VERSION ""

NS_ :

BS_:

BU_:

BO_ 2566697726 SPOC1: 64 Vector__XXX
 SG_ SwitchedOutput10Current : 144|16@1+ (0.005,0) [0|321.275] "A" Vector__XXX
 SG_ SwitchedOutput11Current : 160|16@1+ (0.005,0) [0|321.275] "A" Vector__XXX
 SG_ SwitchedOutput12Current : 176|16@1+ (0.005,0) [0|321.275] "A" Vector__XXX
 SG_ SwitchedOutput13Current : 192|16@1+ (0.005,0) [0|321.275] "A" Vector__XXX
 SG_ SwitchedOutput14Current : 208|16@1+ (0.005,0) [0|321.275] "A" Vector__XXX
 SG_ SwitchedOutput15Current : 224|16@1+ (0.005,0) [0|321.275] "A" Vector__XXX
 SG_ SwitchedOutput16Current : 240|16@1+ (0.005,0) [0|321.275] "A" Vector__XXX
 SG_ SwitchedOutput17Current : 256|16@1+ (0.005,0) [0|321.275] "A" Vector__XXX
 SG_ SwitchedOutput18Current : 272|16@1+ (0.005,0) [0|321.275] "A" Vector__XXX
 SG_ SwitchedOutput19Current : 288|16@1+ (0.005,0) [0|321.275] "A" Vector__XXX
 SG_ SwitchedOutput1Current : 0|16@1+ (0.005,0) [0|321.275] "A" Vector__XXX
 SG_ SwitchedOutput20Current : 304|16@1+ (0.005,0) [0|321.275] "A" Vector__XXX
 SG_ SwitchedOutput21Current : 320|16@1+ (0.005,0) [0|321.275] "A" Vector__XXX
 SG_ SwitchedOutput22Current : 336|16@1+ (0.005,0) [0|321.275] "A" Vector__XXX
 SG_ SwitchedOutput23Current : 352|16@1+ (0.005,0) [0|321.275] "A" Vector__XXX
 SG_ SwitchedOutput24Current : 368|16@1+ (0.005,0) [0|321.275] "A" Vector__XXX
 SG_ SwitchedOutput25Current : 384|16@1+ (0.005,0) [0|321.275] "A" Vector__XXX
 SG_ SwitchedOutput26Current : 400|16@1+ (0.005,0) [0|321.275] "A" Vector__XXX
 SG_ SwitchedOutput27Current : 416|16@1+ (0.005,0) [0|321.275] "A" Vector__XXX
 SG_ SwitchedOutput28Current : 432|16@1+ (0.005,0) [0|321.275] "A" Vector__XXX
 SG_ SwitchedOutput29Current : 448|16@1+ (0.005,0) [0|321.275] "A" Vector__XXX
 SG_ SwitchedOutput2Current : 16|16@1+ (0.005,0) [0|321.275] "A" Vector__XXX
 SG_ SwitchedOutput30Current : 464|16@1+ (0.005,0) [0|321.275] "A" Vector__XXX
 SG_ SwitchedOutput31Current : 480|16@1+ (0.005,0) [0|321.275] "A" Vector__XXX
 SG_ SwitchedOutput32Current : 496|16@1+ (0.005,0) [0|321.275] "A" Vector__XXX
 SG_ SwitchedOutput3Current : 32|16@1+ (0.005,0) [0|321.275] "A" Vector__XXX
 SG_ SwitchedOutput4Current : 48|16@1+ (0.005,0) [0|321.275] "A" Vector__XXX
 SG_ SwitchedOutput5Current : 64|16@1+ (0.005,0) [0|321.275] "A" Vector__XXX
 SG_ SwitchedOutput6Current : 80|16@1+ (0.005,0) [0|321.275] "A" Vector__XXX
 SG_ SwitchedOutput7Current : 96|16@1+ (0.005,0) [0|321.275] "A" Vector__XXX
 SG_ SwitchedOutput8Current : 112|16@1+ (0.005,0) [0|321.275] "A" Vector__XXX
 SG_ SwitchedOutput9Current : 128|16@1+ (0.005,0) [0|321.275] "A" Vector__XXX

BO_ 2566697982 FPOC: 64 Vector__XXX
 SG_ FusedOutput10Current : 144|16@1+ (0.005,0) [0|321.275] "A" Vector__XXX
 SG_ FusedOutput11Current : 160|16@1+ (0.005,0) [0|321.275] "A" Vector__XXX
 SG_ FusedOutput12Current : 176|16@1+ (0.005,0) [0|321.275] "A" Vector__XXX
 SG_ FusedOutput13Current : 192|16@1+ (0.005,0) [0|321.275] "A" Vector__XXX
 SG_ FusedOutput14Current : 208|16@1+ (0.005,0) [0|321.275] "A" Vector__XXX
 SG_ FusedOutput15Current : 224|16@1+ (0.005,0) [0|321.275] "A" Vector__XXX
 SG_ FusedOutput16Current : 240|16@1+ (0.005,0) [0|321.275] "A" Vector__XXX
 SG_ FusedOutput17Current : 256|16@1+ (0.005,0) [0|321.275] "A" Vector__XXX
 SG_ FusedOutput18Current : 272|16@1+ (0.005,0) [0|321.275] "A" Vector__XXX
 SG_ FusedOutput19Current : 288|16@1+ (0.005,0) [0|321.275] "A" Vector__XXX
 SG_ FusedOutput1Current : 0|16@1+ (0.005,0) [0|321.275] "A" Vector__XXX
 SG_ FusedOutput20Current : 304|16@1+ (0.005,0) [0|321.275] "A" Vector__XXX
 SG_ FusedOutput21Current : 320|16@1+ (0.005,0) [0|321.275] "A" Vector__XXX
 SG_ FusedOutput22Current : 336|16@1+ (0.005,0) [0|321.275] "A" Vector__XXX
 SG_ FusedOutput23Current : 352|16@1+ (0.005,0) [0|321.275] "A" Vector__XXX
 SG_ FusedOutput24Current : 368|16@1+ (0.005,0) [0|321.275] "A" Vector__XXX
 SG_ FusedOutput25Current : 384|16@1+ (0.005,0) [0|321.275] "A" Vector__XXX
 SG_ FusedOutput26Current : 400|16@1+ (0.005,0) [0|321.275] "A" Vector__XXX
 SG_ FusedOutput27Current : 416|16@1+ (0.005,0) [0|321.275] "A" Vector__XXX
 SG_ FusedOutput28Current : 432|16@1+ (0.005,0) [0|321.275] "A" Vector__XXX
 SG_ FusedOutput29Current : 448|16@1+ (0.005,0) [0|321.275] "A" Vector__XXX
 SG_ FusedOutput2Current : 16|16@1+ (0.005,0) [0|321.275] "A" Vector__XXX
 SG_ FusedOutput30Current : 464|16@1+ (0.005,0) [0|321.275] "A" Vector__XXX
 SG_ FusedOutput31Current : 480|16@1+ (0.005,0) [0|321.275] "A" Vector__XXX
 SG_ FusedOutput32Current : 496|16@1+ (0.005,0) [0|321.275] "A" Vector__XXX
 SG_ FusedOutput3Current : 32|16@1+ (0.005,0) [0|321.275] "A" Vector__XXX
 SG_ FusedOutput4Current : 48|16@1+ (0.005,0) [0|321.275] "A" Vector__XXX
 SG_ FusedOutput5Current : 64|16@1+ (0.005,0) [0|321.275] "A" Vector__XXX
 SG_ FusedOutput6Current : 80|16@1+ (0.005,0) [0|321.275] "A" Vector__XXX
 SG_ FusedOutput7Current : 96|16@1+ (0.005,0) [0|321.275] "A" Vector__XXX
 SG_ FusedOutput8Current : 112|16@1+ (0.005,0) [0|321.275] "A" Vector__XXX
 SG_ FusedOutput9Current : 128|16@1+ (0.005,0) [0|321.275] "A" Vector__XXX

BO_ 2566698238 SPOS: 8 Vector__XXX
 SG_ SwitchedOutput1 : 6|2@1+ (1,0) [0|3] "" Vector__XXX
 SG_ SwitchedOutput10 : 20|2@1+ (1,0) [0|3] "" Vector__XXX
 SG_ SwitchedOutput11 : 18|2@1+ (1,0) [0|3] "" Vector__XXX
 SG_ SwitchedOutput12 : 16|2@1+ (1,0) [0|3] "" Vector__XXX
 SG_ SwitchedOutput13 : 30|2@1+ (1,0) [0|3] "" Vector__XXX
 SG_ SwitchedOutput14 : 28|2@1+ (1,0) [0|3] "" Vector__XXX
 SG_ SwitchedOutput15 : 26|2@1+ (1,0) [0|3] "" Vector__XXX
 SG_ SwitchedOutput16 : 24|2@1+ (1,0) [0|3] "" Vector__XXX
 SG_ SwitchedOutput17 : 38|2@1+ (1,0) [0|3] "" Vector__XXX
 SG_ SwitchedOutput18 : 36|2@1+ (1,0) [0|3] "" Vector__XXX
 SG_ SwitchedOutput19 : 34|2@1+ (1,0) [0|3] "" Vector__XXX
 SG_ SwitchedOutput2 : 4|2@1+ (1,0) [0|3] "" Vector__XXX
 SG_ SwitchedOutput20 : 32|2@1+ (1,0) [0|3] "" Vector__XXX
 SG_ SwitchedOutput21 : 46|2@1+ (1,0) [0|3] "" Vector__XXX
 SG_ SwitchedOutput22 : 44|2@1+ (1,0) [0|3] "" Vector__XXX
 SG_ SwitchedOutput23 : 42|2@1+ (1,0) [0|3] "" Vector__XXX
 SG_ SwitchedOutput24 : 40|2@1+ (1,0) [0|3] "" Vector__XXX
 SG_ SwitchedOutput25 : 54|2@1+ (1,0) [0|3] "" Vector__XXX
 SG_ SwitchedOutput26 : 52|2@1+ (1,0) [0|3] "" Vector__XXX
 SG_ SwitchedOutput27 : 50|2@1+ (1,0) [0|3] "" Vector__XXX
 SG_ SwitchedOutput28 : 48|2@1+ (1,0) [0|3] "" Vector__XXX
 SG_ SwitchedOutput29 : 62|2@1+ (1,0) [0|3] "" Vector__XXX
 SG_ SwitchedOutput3 : 2|2@1+ (1,0) [0|3] "" Vector__XXX
 SG_ SwitchedOutput30 : 60|2@1+ (1,0) [0|3] "" Vector__XXX
 SG_ SwitchedOutput31 : 58|2@1+ (1,0) [0|3] "" Vector__XXX
 SG_ SwitchedOutput32 : 56|2@1+ (1,0) [0|3] "" Vector__XXX
 SG_ SwitchedOutput4 : 0|2@1+ (1,0) [0|3] "" Vector__XXX
 SG_ SwitchedOutput5 : 14|2@1+ (1,0) [0|3] "" Vector__XXX
 SG_ SwitchedOutput6 : 12|2@1+ (1,0) [0|3] "" Vector__XXX
 SG_ SwitchedOutput7 : 10|2@1+ (1,0) [0|3] "" Vector__XXX
 SG_ SwitchedOutput8 : 8|2@1+ (1,0) [0|3] "" Vector__XXX
 SG_ SwitchedOutput9 : 22|2@1+ (1,0) [0|3] "" Vector__XXX

BO_ 2566698494 FPOS: 8 Vector__XXX
 SG_ FusedOutput1 : 6|2@1+ (1,0) [0|3] "" Vector__XXX
 SG_ FusedOutput10 : 20|2@1+ (1,0) [0|3] "" Vector__XXX
 SG_ FusedOutput11 : 18|2@1+ (1,0) [0|3] "" Vector__XXX
 SG_ FusedOutput12 : 16|2@1+ (1,0) [0|3] "" Vector__XXX
 SG_ FusedOutput13 : 30|2@1+ (1,0) [0|3] "" Vector__XXX
 SG_ FusedOutput14 : 28|2@1+ (1,0) [0|3] "" Vector__XXX
 SG_ FusedOutput15 : 26|2@1+ (1,0) [0|3] "" Vector__XXX
 SG_ FusedOutput16 : 24|2@1+ (1,0) [0|3] "" Vector__XXX
 SG_ FusedOutput17 : 38|2@1+ (1,0) [0|3] "" Vector__XXX
 SG_ FusedOutput18 : 36|2@1+ (1,0) [0|3] "" Vector__XXX
 SG_ FusedOutput19 : 34|2@1+ (1,0) [0|3] "" Vector__XXX
 SG_ FusedOutput2 : 4|2@1+ (1,0) [0|3] "" Vector__XXX
 SG_ FusedOutput20 : 32|2@1+ (1,0) [0|3] "" Vector__XXX
 SG_ FusedOutput21 : 46|2@1+ (1,0) [0|3] "" Vector__XXX
 SG_ FusedOutput22 : 44|2@1+ (1,0) [0|3] "" Vector__XXX
 SG_ FusedOutput23 : 42|2@1+ (1,0) [0|3] "" Vector__XXX
 SG_ FusedOutput24 : 40|2@1+ (1,0) [0|3] "" Vector__XXX
 SG_ FusedOutput25 : 54|2@1+ (1,0) [0|3] "" Vector__XXX
 SG_ FusedOutput26 : 52|2@1+ (1,0) [0|3] "" Vector__XXX
 SG_ FusedOutput27 : 50|2@1+ (1,0) [0|3] "" Vector__XXX
 SG_ FusedOutput28 : 48|2@1+ (1,0) [0|3] "" Vector__XXX
 SG_ FusedOutput29 : 62|2@1+ (1,0) [0|3] "" Vector__XXX
 SG_ FusedOutput3 : 2|2@1+ (1,0) [0|3] "" Vector__XXX
 SG_ FusedOutput30 : 60|2@1+ (1,0) [0|3] "" Vector__XXX
 SG_ FusedOutput31 : 58|2@1+ (1,0) [0|3] "" Vector__XXX
 SG_ FusedOutput32 : 56|2@1+ (1,0) [0|3] "" Vector__XXX
 SG_ FusedOutput4 : 0|2@1+ (1,0) [0|3] "" Vector__XXX
 SG_ FusedOutput5 : 14|2@1+ (1,0) [0|3] "" Vector__XXX
 SG_ FusedOutput6 : 12|2@1+ (1,0) [0|3] "" Vector__XXX
 SG_ FusedOutput7 : 10|2@1+ (1,0) [0|3] "" Vector__XXX
 SG_ FusedOutput8 : 8|2@1+ (1,0) [0|3] "" Vector__XXX
 SG_ FusedOutput9 : 22|2@1+ (1,0) [0|3] "" Vector__XXX

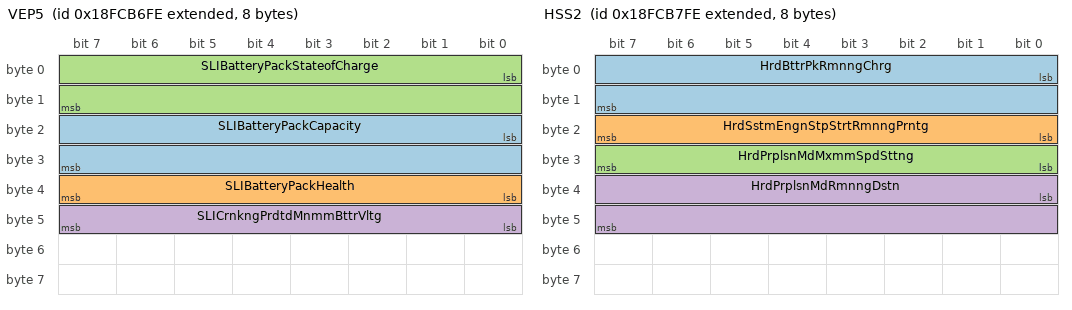
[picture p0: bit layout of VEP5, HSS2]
BO_ 2566698750 VEP5: 8 Vector__XXX
 SG_ SLIBatteryPackCapacity : 16|16@1+ (1,0) [0|64255] "Ah" Vector__XXX
 SG_ SLIBatteryPackHealth : 32|8@1+ (0.5,0) [0|125] "%" Vector__XXX
 SG_ SLIBatteryPackStateofCharge : 0|16@1+ (0.0025,0) [0|160.6375] "%" Vector__XXX
 SG_ SLICrnkngPrdtdMnmmBttrVltg : 40|8@1+ (0.2,0) [0|50] "V" Vector__XXX

BO_ 2566699006 HSS2: 8 Vector__XXX
 SG_ HrdBttrPkRmnngChrg : 0|16@1+ (0.0025,0) [0|160.6375] "%" Vector__XXX
 SG_ HrdSstmEngnStpStrtRmnngPrntg : 16|8@1+ (0.4,0) [0|100] "%" Vector__XXX
 SG_ HrdPrplsnMdMxmmSpdSttng : 24|8@1+ (1,0) [0|250] "km/h" Vector__XXX
 SG_ HrdPrplsnMdRmnngDstn : 32|16@1+ (0.03125,0) [0|2007.96875] "km" Vector__XXX

BO_ 2566699262 AT2S2: 8 Vector__XXX
 SG_ Atttt2DsPttFtTtNxtAtvRt : 0|32@1+ (1,0) [0|4211081215] "s" Vector__XXX
 SG_ Atttt2SCRSstTSLstSstCEvt : 32|32@1+ (1,0) [0|4211081215] "s" Vector__XXX

BO_ 2566699518 AT1S2: 8 Vector__XXX
 SG_ Atttt1DsPttFtTtNxtAtvRt : 0|32@1+ (1,0) [0|4211081215] "s" Vector__XXX
 SG_ Atttt1SCRSstTSLstSstCEvt : 32|32@1+ (1,0) [0|4211081215] "s" Vector__XXX

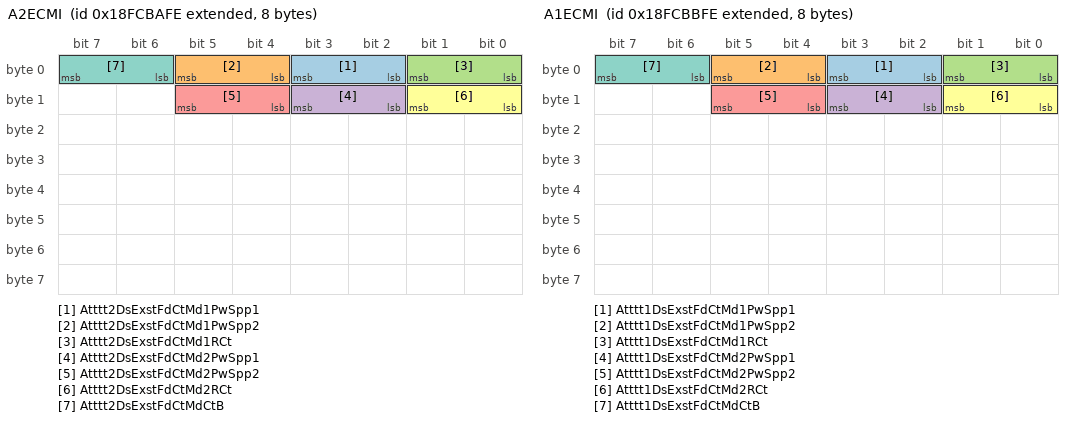
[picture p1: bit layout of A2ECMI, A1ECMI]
BO_ 2566699774 A2ECMI: 8 Vector__XXX
 SG_ Atttt2DsExstFdCtMd1PwSpp1 : 2|2@1+ (1,0) [0|3] "" Vector__XXX
 SG_ Atttt2DsExstFdCtMd1PwSpp2 : 4|2@1+ (1,0) [0|3] "" Vector__XXX
 SG_ Atttt2DsExstFdCtMd1RCt : 0|2@1+ (1,0) [0|3] "" Vector__XXX
 SG_ Atttt2DsExstFdCtMd2PwSpp1 : 10|2@1+ (1,0) [0|3] "" Vector__XXX
 SG_ Atttt2DsExstFdCtMd2PwSpp2 : 12|2@1+ (1,0) [0|3] "" Vector__XXX
 SG_ Atttt2DsExstFdCtMd2RCt : 8|2@1+ (1,0) [0|3] "" Vector__XXX
 SG_ Atttt2DsExstFdCtMdCtB : 6|2@1+ (1,0) [0|3] "" Vector__XXX

BO_ 2566700030 A1ECMI: 8 Vector__XXX
 SG_ Atttt1DsExstFdCtMd1PwSpp1 : 2|2@1+ (1,0) [0|3] "" Vector__XXX
 SG_ Atttt1DsExstFdCtMd1PwSpp2 : 4|2@1+ (1,0) [0|3] "" Vector__XXX
 SG_ Atttt1DsExstFdCtMd1RCt : 0|2@1+ (1,0) [0|3] "" Vector__XXX
 SG_ Atttt1DsExstFdCtMd2PwSpp1 : 10|2@1+ (1,0) [0|3] "" Vector__XXX
 SG_ Atttt1DsExstFdCtMd2PwSpp2 : 12|2@1+ (1,0) [0|3] "" Vector__XXX
 SG_ Atttt1DsExstFdCtMd2RCt : 8|2@1+ (1,0) [0|3] "" Vector__XXX
 SG_ Atttt1DsExstFdCtMdCtB : 6|2@1+ (1,0) [0|3] "" Vector__XXX

BO_ 2566700286 A2SCRSI2: 8 Vector__XXX
 SG_ Aftrtrtmnt2TtlDslExhstFldUsd : 0|32@1+ (0.5,0) [0|2105540607.5] "l" Vector__XXX

BO_ 2566700542 A1SCRSI2: 8 Vector__XXX
 SG_ Aftrtrtmnt1TtlDslExhstFldUsd : 0|32@1+ (0.5,0) [0|2105540607.5] "l" Vector__XXX
 SG_ AftrtrtmntTrpDslExhstFld : 32|32@1+ (0.05,0) [0|210554060.75] "l" Vector__XXX

BO_ 2566701566 TRF3: 8 Vector__XXX
 SG_ TransmissionClutch2Pressure : 0|8@1+ (16,0) [0|4000] "kPa" Vector__XXX
 SG_ TrnsmssnOlTrnsmssnClrOtltTmprtr : 8|8@1+ (1,-40) [-40|210] "degC" Vector__XXX

BO_ 2566701822 HSS1: 8 Vector__XXX
 SG_ ExtrnlEnrgSrCnntnStts : 48|4@1+ (1,0) [0|15] "" Vector__XXX
 SG_ HrdPrplsnMdTrnstnStts : 44|4@1+ (1,0) [0|15] "" Vector__XXX
 SG_ HrdSstmEltrAltrntrIndtr : 18|2@1+ (1,0) [0|3] "" Vector__XXX
 SG_ HrdSstmHghVltgExpsrIndtr : 24|2@1+ (1,0) [0|3] "" Vector__XXX
 SG_ HrdSstmIntlztnIndtr : 22|2@1+ (1,0) [0|3] "" Vector__XXX
 SG_ HrdSstmMtrOvrspdAdlAlrm : 16|2@1+ (1,0) [0|3] "" Vector__XXX
 SG_ HrdSstmMtrOvrspdIndtr : 14|2@1+ (1,0) [0|3] "" Vector__XXX
 SG_ HrdSstmPrplsnDslStts : 52|2@1+ (1,0) [0|3] "" Vector__XXX
 SG_ HrdSstmRgnrtvBrkngIndtr : 20|2@1+ (1,0) [0|3] "" Vector__XXX
 SG_ HybridPropulsionModeStatus : 40|4@1+ (1,0) [0|15] "" Vector__XXX
 SG_ HybridSystemEngineAssistStatus : 10|2@1+ (1,0) [0|3] "" Vector__XXX
 SG_ HybridSystemOBDRelatedDTCStatus : 6|2@1+ (1,0) [0|3] "" Vector__XXX
 SG_ HybridSystemOverheatIndicator : 2|2@1+ (1,0) [0|3] "" Vector__XXX
 SG_ HybridSystemServiceIndicator : 12|2@1+ (1,0) [0|3] "" Vector__XXX
 SG_ HybridSystemStopIndicator : 4|2@1+ (1,0) [0|3] "" Vector__XXX
 SG_ HybridSystemWarningIndicator : 0|2@1+ (1,0) [0|3] "" Vector__XXX
 SG_ PropulsionSystemActive : 8|2@1+ (1,0) [0|3] "" Vector__XXX
 SG_ StoredEnergySourceLevel : 32|8@1+ (0.4,0) [0|100] "%" Vector__XXX
 SG_ StrdEnrgSrInrsngMdAllwd : 28|2@1+ (1,0) [0|3] "" Vector__XXX
 SG_ StrdEnrgSrOnlMdAllwd : 26|2@1+ (1,0) [0|3] "" Vector__XXX

BO_ 2566702078 GFI4: 8 Vector__XXX
 SG_ SupplyGasMethanePercentage : 0|16@1+ (0.0025,0) [0|160.6375] "%" Vector__XXX

BO_ 2566702334 A2SCREGT2: 8 Vector__XXX
 SG_ Aftrtrtmnt2SCRIntrmdtTmprtr : 0|16@1+ (0.03125,-273) [-273|1734.96875] "degC" Vector__XXX
 SG_ Atttt2SCRItdtTptPFMI : 16|5@1+ (1,0) [0|31] "binary" Vector__XXX

BO_ 2566702590 A1SCREGT2: 8 Vector__XXX
 SG_ Aftrtrtmnt1SCRIntrmdtTmprtr : 0|16@1+ (0.03125,-273) [-273|1734.96875] "degC" Vector__XXX
 SG_ Atttt1SCRItdtTptPFMI : 16|5@1+ (1,0) [0|31] "binary" Vector__XXX

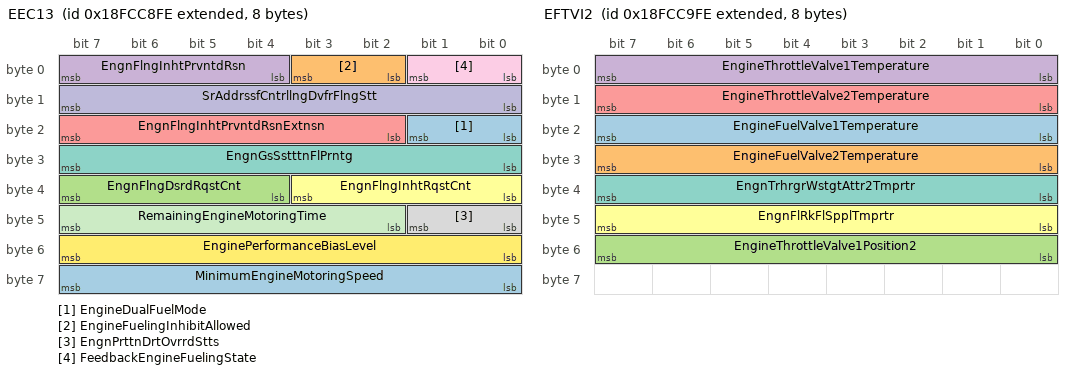
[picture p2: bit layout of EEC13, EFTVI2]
BO_ 2566703358 EEC13: 8 Vector__XXX
 SG_ EngineDualFuelMode : 16|2@1+ (1,0) [0|3] "" Vector__XXX
 SG_ EngineFuelingInhibitAllowed : 2|2@1+ (1,0) [0|3] "" Vector__XXX
 SG_ EngnFlngDsrdRqstCnt : 36|4@1+ (1,0) [0|15] "" Vector__XXX
 SG_ EngnFlngInhtPrvntdRsn : 4|4@1+ (1,0) [0|15] "" Vector__XXX
 SG_ EngnFlngInhtPrvntdRsnExtnsn : 18|6@1+ (1,0) [0|63] "" Vector__XXX
 SG_ EngnFlngInhtRqstCnt : 32|4@1+ (1,0) [0|15] "" Vector__XXX
 SG_ EngnGsSstttnFlPrntg : 24|8@1+ (0.5,0) [0|125] "%" Vector__XXX
 SG_ EngnPrttnDrtOvrrdStts : 40|2@1+ (1,0) [0|3] "" Vector__XXX
 SG_ FeedbackEngineFuelingState : 0|2@1+ (1,0) [0|3] "" Vector__XXX
 SG_ SrAddrssfCntrllngDvfrFlngStt : 8|8@1+ (1,0) [0|255] "SA" Vector__XXX
 SG_ RemainingEngineMotoringTime : 42|6@1+ (1,0) [0|58] "s" Vector__XXX
 SG_ EnginePerformanceBiasLevel : 48|8@1+ (0.4,0) [0|100] "%" Vector__XXX
 SG_ MinimumEngineMotoringSpeed : 56|8@1+ (10,0) [0|2500] "rpm" Vector__XXX

BO_ 2566703614 EFTVI2: 8 Vector__XXX
 SG_ EngineFuelValve1Temperature : 16|8@1+ (1,-40) [-40|210] "degC" Vector__XXX
 SG_ EngineFuelValve2Temperature : 24|8@1+ (1,-40) [-40|210] "degC" Vector__XXX
 SG_ EngineThrottleValve1Position2 : 48|8@1+ (0.4,0) [0|100] "%" Vector__XXX
 SG_ EngineThrottleValve1Temperature : 0|8@1+ (1,-40) [-40|210] "degC" Vector__XXX
 SG_ EngineThrottleValve2Temperature : 8|8@1+ (1,-40) [-40|210] "degC" Vector__XXX
 SG_ EngnFlRkFlSpplTmprtr : 40|8@1+ (1,-40) [-40|210] "degC" Vector__XXX
 SG_ EngnTrhrgrWstgtAttr2Tmprtr : 32|8@1+ (1,-40) [-40|210] "degC" Vector__XXX

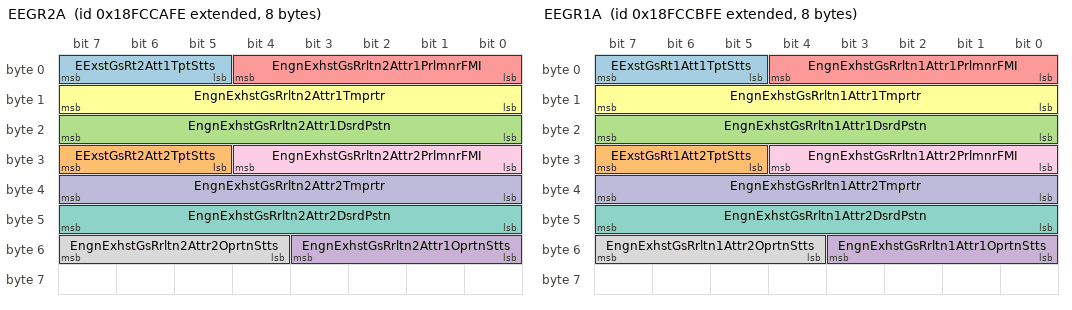
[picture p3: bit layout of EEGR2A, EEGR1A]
BO_ 2566703870 EEGR2A: 8 Vector__XXX
 SG_ EExstGsRt2Att1TptStts : 5|3@1+ (1,0) [0|7] "" Vector__XXX
 SG_ EExstGsRt2Att2TptStts : 29|3@1+ (1,0) [0|7] "" Vector__XXX
 SG_ EngnExhstGsRrltn2Attr1DsrdPstn : 16|8@1+ (0.4,0) [0|100] "%" Vector__XXX
 SG_ EngnExhstGsRrltn2Attr1OprtnStts : 48|4@1+ (1,0) [0|15] "" Vector__XXX
 SG_ EngnExhstGsRrltn2Attr1PrlmnrFMI : 0|5@1+ (1,0) [0|31] "binary" Vector__XXX
 SG_ EngnExhstGsRrltn2Attr1Tmprtr : 8|8@1+ (1,-40) [-40|210] "degC" Vector__XXX
 SG_ EngnExhstGsRrltn2Attr2DsrdPstn : 40|8@1+ (0.4,0) [0|100] "%" Vector__XXX
 SG_ EngnExhstGsRrltn2Attr2OprtnStts : 52|4@1+ (1,0) [0|15] "" Vector__XXX
 SG_ EngnExhstGsRrltn2Attr2PrlmnrFMI : 24|5@1+ (1,0) [0|31] "binary" Vector__XXX
 SG_ EngnExhstGsRrltn2Attr2Tmprtr : 32|8@1+ (1,-40) [-40|210] "degC" Vector__XXX

BO_ 2566704126 EEGR1A: 8 Vector__XXX
 SG_ EExstGsRt1Att1TptStts : 5|3@1+ (1,0) [0|7] "" Vector__XXX
 SG_ EExstGsRt1Att2TptStts : 29|3@1+ (1,0) [0|7] "" Vector__XXX
 SG_ EngnExhstGsRrltn1Attr1DsrdPstn : 16|8@1+ (0.4,0) [0|100] "%" Vector__XXX
 SG_ EngnExhstGsRrltn1Attr1OprtnStts : 48|4@1+ (1,0) [0|15] "" Vector__XXX
 SG_ EngnExhstGsRrltn1Attr1PrlmnrFMI : 0|5@1+ (1,0) [0|31] "binary" Vector__XXX
 SG_ EngnExhstGsRrltn1Attr1Tmprtr : 8|8@1+ (1,-40) [-40|210] "degC" Vector__XXX
 SG_ EngnExhstGsRrltn1Attr2DsrdPstn : 40|8@1+ (0.4,0) [0|100] "%" Vector__XXX
 SG_ EngnExhstGsRrltn1Attr2OprtnStts : 52|4@1+ (1,0) [0|15] "" Vector__XXX
 SG_ EngnExhstGsRrltn1Attr2PrlmnrFMI : 24|5@1+ (1,0) [0|31] "binary" Vector__XXX
 SG_ EngnExhstGsRrltn1Attr2Tmprtr : 32|8@1+ (1,-40) [-40|210] "degC" Vector__XXX

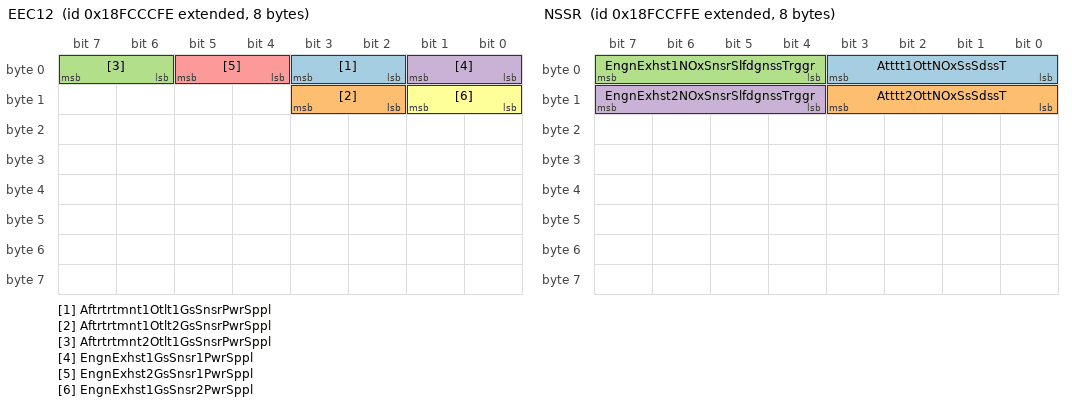
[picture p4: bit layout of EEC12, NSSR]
BO_ 2566704382 EEC12: 8 Vector__XXX
 SG_ Aftrtrtmnt1Otlt1GsSnsrPwrSppl : 2|2@1+ (1,0) [0|3] "" Vector__XXX
 SG_ Aftrtrtmnt1Otlt2GsSnsrPwrSppl : 10|2@1+ (1,0) [0|3] "" Vector__XXX
 SG_ Aftrtrtmnt2Otlt1GsSnsrPwrSppl : 6|2@1+ (1,0) [0|3] "" Vector__XXX
 SG_ EngnExhst1GsSnsr1PwrSppl : 0|2@1+ (1,0) [0|3] "" Vector__XXX
 SG_ EngnExhst2GsSnsr1PwrSppl : 4|2@1+ (1,0) [0|3] "" Vector__XXX
 SG_ EngnExhst1GsSnsr2PwrSppl : 8|2@1+ (1,0) [0|3] "" Vector__XXX

BO_ 2566705150 NSSR: 8 Vector__XXX
 SG_ Atttt1OttNOxSsSdssT : 0|4@1+ (1,0) [0|15] "" Vector__XXX
 SG_ Atttt2OttNOxSsSdssT : 8|4@1+ (1,0) [0|15] "" Vector__XXX
 SG_ EngnExhst1NOxSnsrSlfdgnssTrggr : 4|4@1+ (1,0) [0|15] "" Vector__XXX
 SG_ EngnExhst2NOxSnsrSlfdgnssTrggr : 12|4@1+ (1,0) [0|15] "" Vector__XXX

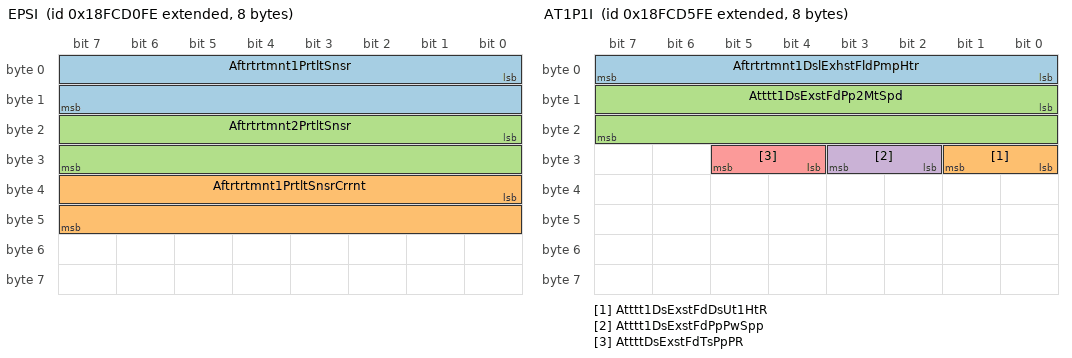
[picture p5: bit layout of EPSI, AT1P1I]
BO_ 2566705406 EPSI: 8 Vector__XXX
 SG_ Aftrtrtmnt1PrtltSnsr : 0|16@1+ (0.0125,0) [0|803.1875] "mg/(m*m*m)" Vector__XXX
 SG_ Aftrtrtmnt1PrtltSnsrCrrnt : 32|16@1+ (0.00390625,0) [0|250.99609375] "micro A" Vector__XXX
 SG_ Aftrtrtmnt2PrtltSnsr : 16|16@1+ (0.0125,0) [0|803.1875] "mg/(m*m*m)" Vector__XXX

BO_ 2566706686 AT1P1I: 8 Vector__XXX
 SG_ Aftrtrtmnt1DslExhstFldPmpHtr : 0|8@1+ (0.4,0) [0|100] "%" Vector__XXX
 SG_ Atttt1DsExstFdDsUt1HtR : 24|2@1+ (1,0) [0|3] "" Vector__XXX
 SG_ Atttt1DsExstFdPp2MtSpd : 8|16@1+ (0.5,0) [0|32127.5] "rpm" Vector__XXX
 SG_ Atttt1DsExstFdPpPwSpp : 26|2@1+ (1,0) [0|3] "" Vector__XXX
 SG_ AttttDsExstFdTsPpPR : 28|2@1+ (1,0) [0|3] "" Vector__XXX

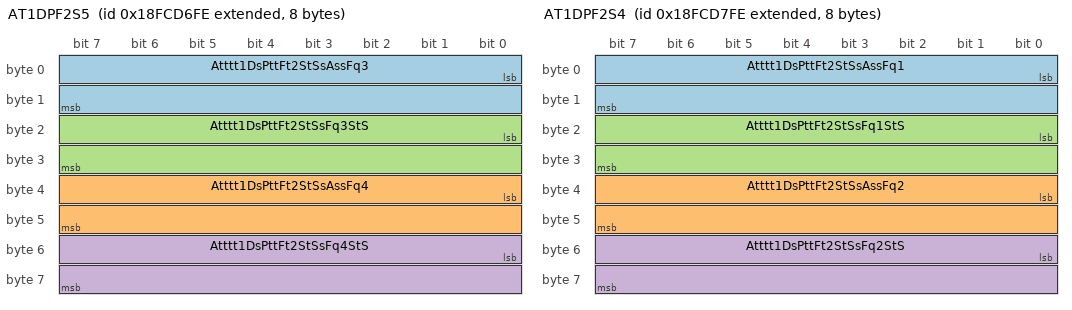
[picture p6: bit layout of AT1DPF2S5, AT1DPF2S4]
BO_ 2566706942 AT1DPF2S5: 8 Vector__XXX
 SG_ Atttt1DsPttFt2StSsAssFq3 : 0|16@1+ (0.1,0) [0|6425.5] "MHz" Vector__XXX
 SG_ Atttt1DsPttFt2StSsAssFq4 : 32|16@1+ (0.1,0) [0|6425.5] "MHz" Vector__XXX
 SG_ Atttt1DsPttFt2StSsFq3StS : 16|16@1+ (0.0025,0) [0|160.6375] "%" Vector__XXX
 SG_ Atttt1DsPttFt2StSsFq4StS : 48|16@1+ (0.0025,0) [0|160.6375] "%" Vector__XXX

BO_ 2566707198 AT1DPF2S4: 8 Vector__XXX
 SG_ Atttt1DsPttFt2StSsAssFq1 : 0|16@1+ (0.1,0) [0|6425.5] "MHz" Vector__XXX
 SG_ Atttt1DsPttFt2StSsAssFq2 : 32|16@1+ (0.1,0) [0|6425.5] "MHz" Vector__XXX
 SG_ Atttt1DsPttFt2StSsFq1StS : 16|16@1+ (0.0025,0) [0|160.6375] "%" Vector__XXX
 SG_ Atttt1DsPttFt2StSsFq2StS : 48|16@1+ (0.0025,0) [0|160.6375] "%" Vector__XXX

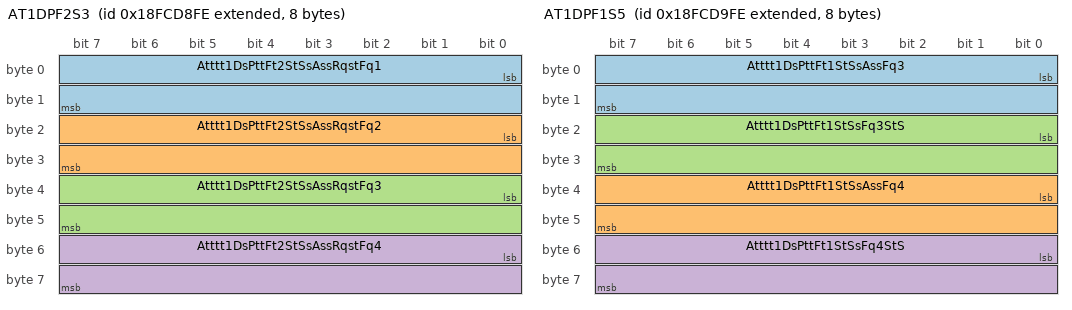
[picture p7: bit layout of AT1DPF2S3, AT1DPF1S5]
BO_ 2566707454 AT1DPF2S3: 8 Vector__XXX
 SG_ Atttt1DsPttFt2StSsAssRqstFq1 : 0|16@1+ (0.1,0) [0|6425.5] "MHz" Vector__XXX
 SG_ Atttt1DsPttFt2StSsAssRqstFq2 : 16|16@1+ (0.1,0) [0|6425.5] "MHz" Vector__XXX
 SG_ Atttt1DsPttFt2StSsAssRqstFq3 : 32|16@1+ (0.1,0) [0|6425.5] "MHz" Vector__XXX
 SG_ Atttt1DsPttFt2StSsAssRqstFq4 : 48|16@1+ (0.1,0) [0|6425.5] "MHz" Vector__XXX

BO_ 2566707710 AT1DPF1S5: 8 Vector__XXX
 SG_ Atttt1DsPttFt1StSsAssFq3 : 0|16@1+ (0.1,0) [0|6425.5] "MHz" Vector__XXX
 SG_ Atttt1DsPttFt1StSsAssFq4 : 32|16@1+ (0.1,0) [0|6425.5] "MHz" Vector__XXX
 SG_ Atttt1DsPttFt1StSsFq3StS : 16|16@1+ (0.0025,0) [0|160.6375] "%" Vector__XXX
 SG_ Atttt1DsPttFt1StSsFq4StS : 48|16@1+ (0.0025,0) [0|160.6375] "%" Vector__XXX

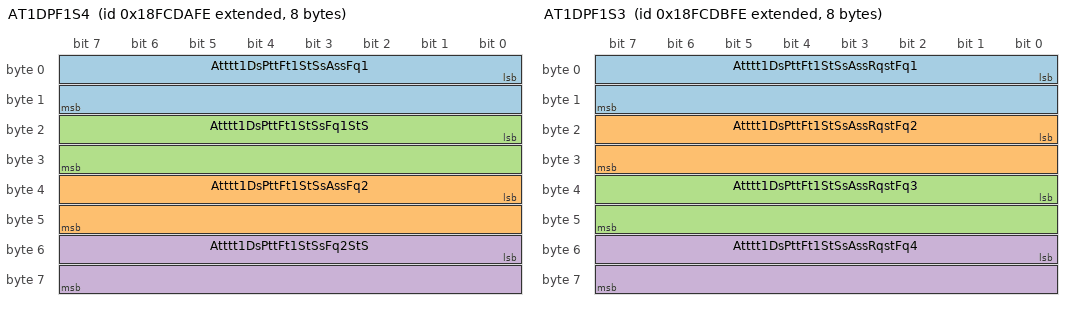
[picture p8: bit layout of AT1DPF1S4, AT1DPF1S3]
BO_ 2566707966 AT1DPF1S4: 8 Vector__XXX
 SG_ Atttt1DsPttFt1StSsAssFq1 : 0|16@1+ (0.1,0) [0|6425.5] "MHz" Vector__XXX
 SG_ Atttt1DsPttFt1StSsAssFq2 : 32|16@1+ (0.1,0) [0|6425.5] "MHz" Vector__XXX
 SG_ Atttt1DsPttFt1StSsFq1StS : 16|16@1+ (0.0025,0) [0|160.6375] "%" Vector__XXX
 SG_ Atttt1DsPttFt1StSsFq2StS : 48|16@1+ (0.0025,0) [0|160.6375] "%" Vector__XXX

BO_ 2566708222 AT1DPF1S3: 8 Vector__XXX
 SG_ Atttt1DsPttFt1StSsAssRqstFq1 : 0|16@1+ (0.1,0) [0|6425.5] "MHz" Vector__XXX
 SG_ Atttt1DsPttFt1StSsAssRqstFq2 : 16|16@1+ (0.1,0) [0|6425.5] "MHz" Vector__XXX
 SG_ Atttt1DsPttFt1StSsAssRqstFq3 : 32|16@1+ (0.1,0) [0|6425.5] "MHz" Vector__XXX
 SG_ Atttt1DsPttFt1StSsAssRqstFq4 : 48|16@1+ (0.1,0) [0|6425.5] "MHz" Vector__XXX

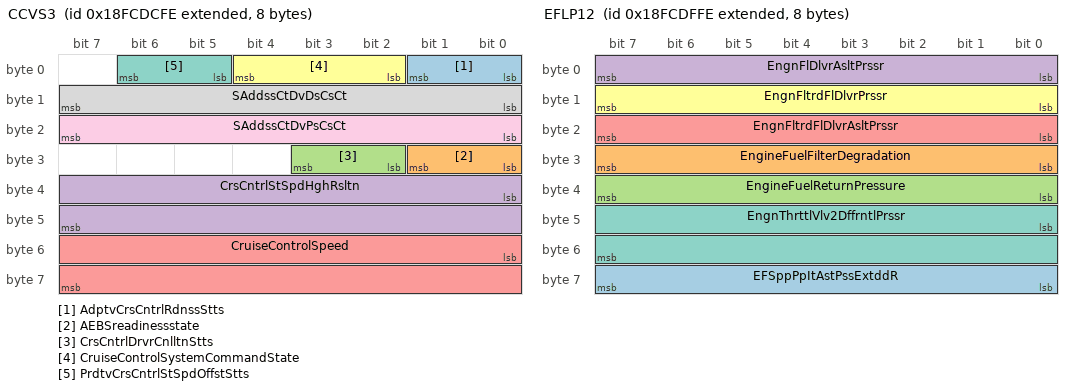
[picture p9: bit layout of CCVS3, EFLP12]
BO_ 2566708478 CCVS3: 8 Vector__XXX
 SG_ AdptvCrsCntrlRdnssStts : 0|2@1+ (1,0) [0|3] "" Vector__XXX
 SG_ AEBSreadinessstate : 24|2@1+ (1,0) [0|3] "" Vector__XXX
 SG_ CrsCntrlDrvrCnlltnStts : 26|2@1+ (1,0) [0|3] "" Vector__XXX
 SG_ CrsCntrlStSpdHghRsltn : 32|16@1+ (0.00390625,0) [0|250.996] "km/h" Vector__XXX
 SG_ CruiseControlSpeed : 48|16@1+ (0.00390625,0) [0|250.996] "km/h" Vector__XXX
 SG_ CruiseControlSystemCommandState : 2|3@1+ (1,0) [0|7] "" Vector__XXX
 SG_ PrdtvCrsCntrlStSpdOffstStts : 5|2@1+ (1,0) [0|3] "" Vector__XXX
 SG_ SAddssCtDvDsCsCt : 8|8@1+ (1,0) [0|255] "SA" Vector__XXX
 SG_ SAddssCtDvPsCsCt : 16|8@1+ (1,0) [0|255] "SA" Vector__XXX

BO_ 2566708734 AT2AC3: 8 Vector__XXX
 SG_ Aftrtrtmnt2SndrArAsltPrssr : 0|16@1+ (0.1,0) [0|6425.5] "kPa" Vector__XXX

BO_ 2566708990 AT1AC3: 8 Vector__XXX
 SG_ Aftrtrtmnt1SndrArAsltPrssr : 0|16@1+ (0.1,0) [0|6425.5] "kPa" Vector__XXX
 SG_ OprtrIndmntOvrrdRnwlRqrd : 16|2@1+ (1,0) [0|3] "" Vector__XXX

BO_ 2566709246 EFLP12: 8 Vector__XXX
 SG_ EFSppPpItAstPssExtddR : 56|8@1+ (5,0) [0|1250] "kPa" Vector__XXX
 SG_ EngineFuelFilterDegradation : 24|8@1+ (1,0) [0|250] "%" Vector__XXX
 SG_ EngineFuelReturnPressure : 32|8@1+ (1.64,-7) [-7|403] "kPa" Vector__XXX
 SG_ EngnFlDlvrAsltPrssr : 0|8@1+ (4,0) [0|1000] "kPa" Vector__XXX
 SG_ EngnFltrdFlDlvrAsltPrssr : 16|8@1+ (4,0) [0|1000] "kPa" Vector__XXX
 SG_ EngnFltrdFlDlvrPrssr : 8|8@1+ (4,0) [0|1000] "kPa" Vector__XXX
 SG_ EngnThrttlVlv2DffrntlPrssr : 40|16@1+ (0.1,0) [0|6425.5] "kPa" Vector__XXX

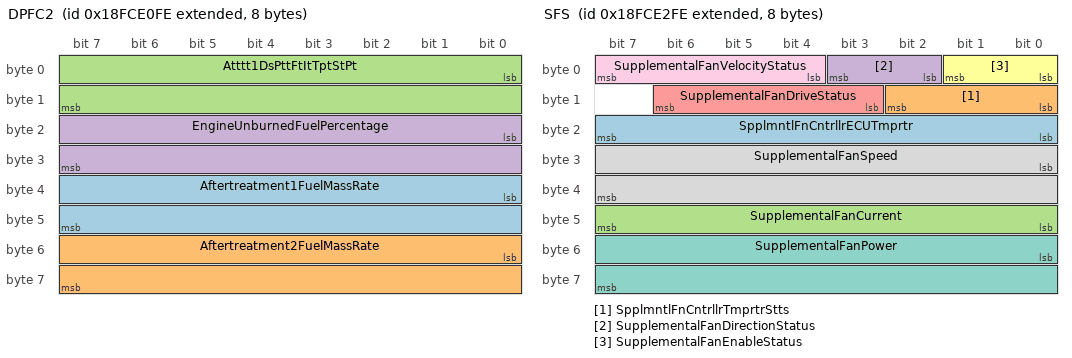
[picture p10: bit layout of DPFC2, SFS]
BO_ 2566709502 DPFC2: 8 Vector__XXX
 SG_ Aftertreatment1FuelMassRate : 32|16@1+ (0.05,0) [0|3212.75] "g/min" Vector__XXX
 SG_ Aftertreatment2FuelMassRate : 48|16@1+ (0.05,0) [0|3212.75] "g/min" Vector__XXX
 SG_ Atttt1DsPttFtItTptStPt : 0|16@1+ (0.03125,-273) [-273|1734.96875] "degC" Vector__XXX
 SG_ EngineUnburnedFuelPercentage : 16|16@1+ (0.0025,0) [0|160.6375] "%" Vector__XXX

BO_ 2566709758 LFE2: 8 Vector__XXX
 SG_ EngineDieselFuelDemandRate : 32|16@1+ (0.05,0) [0|3212.75] "l/h" Vector__XXX
 SG_ EngineFuelRateHighResolution : 0|32@1+ (0.001,0) [0|4211081.215] "l/h" Vector__XXX

BO_ 2566710014 SFS: 8 Vector__XXX
 SG_ SpplmntlFnCntrllrECUTmprtr : 16|8@1+ (1,-40) [-40|210] "degC" Vector__XXX
 SG_ SpplmntlFnCntrllrTmprtrStts : 8|3@1+ (1,0) [0|7] "" Vector__XXX
 SG_ SupplementalFanCurrent : 40|8@1+ (1,-125) [-125|125] "A" Vector__XXX
 SG_ SupplementalFanDirectionStatus : 2|2@1+ (1,0) [0|3] "" Vector__XXX
 SG_ SupplementalFanDriveStatus : 11|4@1+ (1,0) [0|15] "" Vector__XXX
 SG_ SupplementalFanEnableStatus : 0|2@1+ (1,0) [0|3] "" Vector__XXX
 SG_ SupplementalFanPower : 48|16@1+ (0.5,0) [0|32127.5] "W" Vector__XXX
 SG_ SupplementalFanSpeed : 24|16@1+ (0.5,0) [0|32127.5] "rpm" Vector__XXX
 SG_ SupplementalFanVelocityStatus : 4|4@1+ (1,0) [0|15] "" Vector__XXX

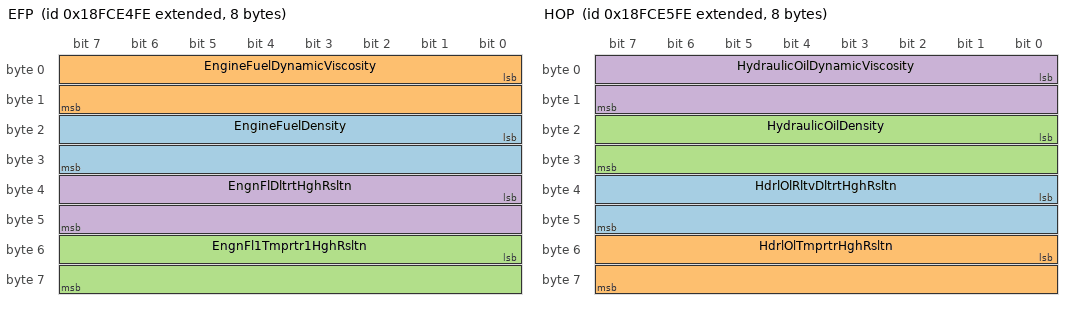
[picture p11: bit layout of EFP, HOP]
BO_ 2566710526 EFP: 8 Vector__XXX
 SG_ EngineFuelDensity : 16|16@1+ (0.00003052,0) [0|1.961] "g/cc" Vector__XXX
 SG_ EngineFuelDynamicViscosity : 0|16@1+ (0.015625,0) [0|1003.984375] "Cp" Vector__XXX
 SG_ EngnFl1Tmprtr1HghRsltn : 48|16@1+ (0.03125,-273) [-273|1734.96875] "degC" Vector__XXX
 SG_ EngnFlDltrtHghRsltn : 32|16@1+ (0.0001220703125,0) [0|7.844] "" Vector__XXX

BO_ 2566710782 HOP: 8 Vector__XXX
 SG_ HdrlOlRltvDltrtHghRsltn : 32|16@1+ (0.0001220703125,0) [0|7.844] "" Vector__XXX
 SG_ HdrlOlTmprtrHghRsltn : 48|16@1+ (0.03125,-273) [-273|1734.96875] "degC" Vector__XXX
 SG_ HydraulicOilDensity : 16|16@1+ (0.00003052,0) [0|1.961] "g/cc" Vector__XXX
 SG_ HydraulicOilDynamicViscosity : 0|16@1+ (0.015625,0) [0|1003.984375] "Cp" Vector__XXX

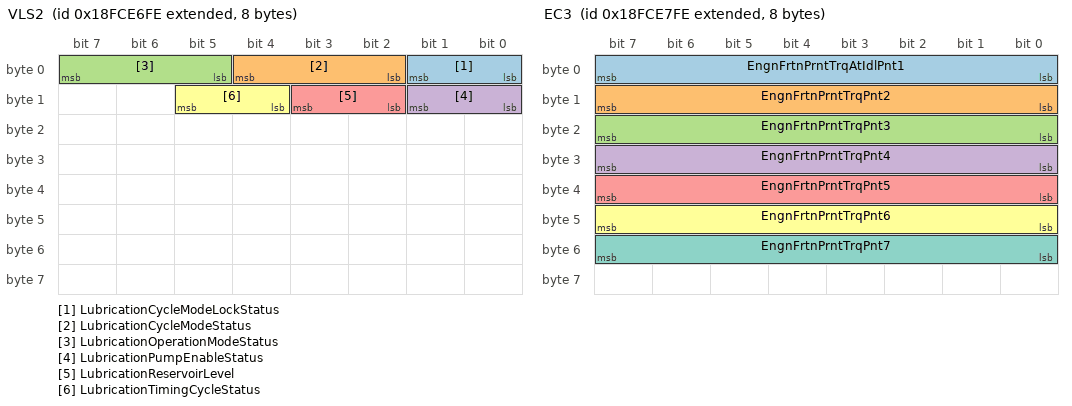
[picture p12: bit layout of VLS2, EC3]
BO_ 2566711038 VLS2: 8 Vector__XXX
 SG_ LubricationCycleModeLockStatus : 0|2@1+ (1,0) [0|3] "" Vector__XXX
 SG_ LubricationCycleModeStatus : 2|3@1+ (1,0) [0|7] "" Vector__XXX
 SG_ LubricationOperationModeStatus : 5|3@1+ (1,0) [0|7] "" Vector__XXX
 SG_ LubricationPumpEnableStatus : 8|2@1+ (1,0) [0|3] "" Vector__XXX
 SG_ LubricationReservoirLevel : 10|2@1+ (1,0) [0|3] "" Vector__XXX
 SG_ LubricationTimingCycleStatus : 12|2@1+ (1,0) [0|3] "" Vector__XXX

BO_ 2566711294 EC3: 8 Vector__XXX
 SG_ EngnFrtnPrntTrqAtIdlPnt1 : 0|8@1+ (1,-125) [-125|125] "%" Vector__XXX
 SG_ EngnFrtnPrntTrqPnt2 : 8|8@1+ (1,-125) [-125|125] "%" Vector__XXX
 SG_ EngnFrtnPrntTrqPnt3 : 16|8@1+ (1,-125) [-125|125] "%" Vector__XXX
 SG_ EngnFrtnPrntTrqPnt4 : 24|8@1+ (1,-125) [-125|125] "%" Vector__XXX
 SG_ EngnFrtnPrntTrqPnt5 : 32|8@1+ (1,-125) [-125|125] "%" Vector__XXX
 SG_ EngnFrtnPrntTrqPnt6 : 40|8@1+ (1,-125) [-125|125] "%" Vector__XXX
 SG_ EngnFrtnPrntTrqPnt7 : 48|8@1+ (1,-125) [-125|125] "%" Vector__XXX

BO_ 2566711550 IVAC: 8 Vector__XXX
 SG_ ItVvAttSstOPss1SdCt : 0|2@1+ (1,0) [0|3] "" Vector__XXX
 SG_ ItVvAttSstOPss2SdCt : 2|2@1+ (1,0) [0|3] "" Vector__XXX

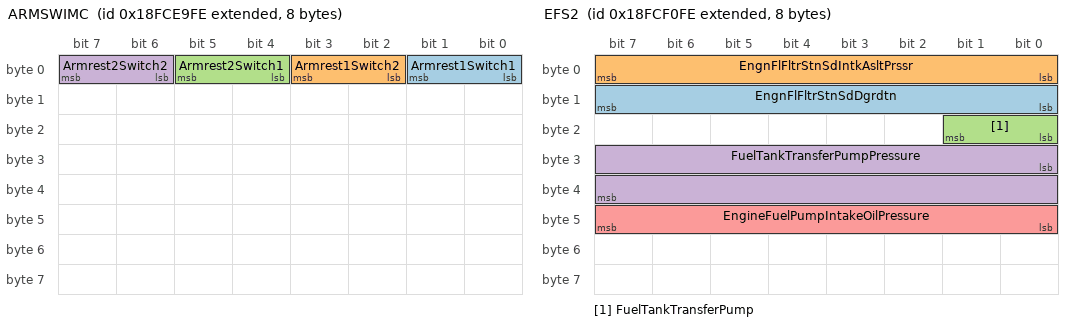
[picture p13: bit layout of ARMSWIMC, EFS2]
BO_ 2566711806 ARMSWIMC: 8 Vector__XXX
 SG_ Armrest1Switch1 : 0|2@1+ (1,0) [0|3] "" Vector__XXX
 SG_ Armrest1Switch2 : 2|2@1+ (1,0) [0|3] "" Vector__XXX
 SG_ Armrest2Switch1 : 4|2@1+ (1,0) [0|3] "" Vector__XXX
 SG_ Armrest2Switch2 : 6|2@1+ (1,0) [0|3] "" Vector__XXX

BO_ 2566712318 AFT2NAI: 8 Vector__XXX
 SG_ Aftrtrtmnt2NOxAdsrrDslftnStts : 2|2@1+ (1,0) [0|3] "" Vector__XXX
 SG_ Aftrtrtmnt2NOxAdsrrRgnrtnStts : 0|2@1+ (1,0) [0|3] "" Vector__XXX

BO_ 2566712574 AFT1NAI: 8 Vector__XXX
 SG_ Aftrtrtmnt1NOxAdsrrDslftnStts : 2|2@1+ (1,0) [0|3] "" Vector__XXX
 SG_ Aftrtrtmnt1NOxAdsrrRgnrtnStts : 0|2@1+ (1,0) [0|3] "" Vector__XXX

BO_ 2566712830 AT2WUDOC: 8 Vector__XXX
 SG_ Atttt2WUpDsOxdtCtstItTpt : 0|16@1+ (0.03125,-273) [-273|1734.96875] "degC" Vector__XXX
 SG_ Atttt2WUpDsOxdtCtstOttTpt : 16|16@1+ (0.03125,-273) [-273|1734.96875] "degC" Vector__XXX

BO_ 2566713598 EFS2: 8 Vector__XXX
 SG_ EngnFlFltrStnSdDgrdtn : 8|8@1+ (1,0) [0|250] "%" Vector__XXX
 SG_ EngnFlFltrStnSdIntkAsltPrssr : 0|8@1+ (2,0) [0|500] "kPa" Vector__XXX
 SG_ FuelTankTransferPump : 16|2@1+ (1,0) [0|3] "" Vector__XXX
 SG_ FuelTankTransferPumpPressure : 24|16@1+ (0.1,0) [0|6425.5] "kPa" Vector__XXX
 SG_ EngineFuelPumpIntakeOilPressure : 40|8@1+ (4,0) [0|1000] "kPa" Vector__XXX

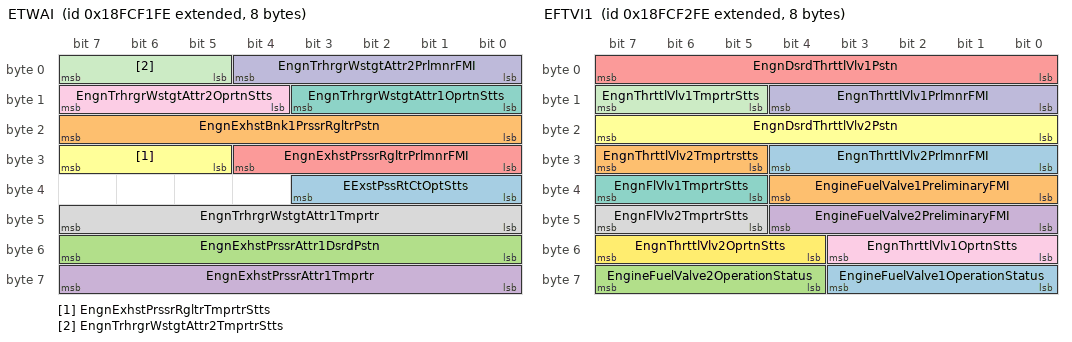
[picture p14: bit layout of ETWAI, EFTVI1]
BO_ 2566713854 ETWAI: 8 Vector__XXX
 SG_ EExstPssRtCtOptStts : 32|4@1+ (1,0) [0|15] "" Vector__XXX
 SG_ EngnExhstBnk1PrssrRgltrPstn : 16|8@1+ (0.4,0) [0|100] "%" Vector__XXX
 SG_ EngnExhstPrssrAttr1DsrdPstn : 48|8@1+ (0.4,0) [0|100] "%" Vector__XXX
 SG_ EngnExhstPrssrAttr1Tmprtr : 56|8@1+ (1,-40) [-40|210] "degC" Vector__XXX
 SG_ EngnExhstPrssrRgltrPrlmnrFMI : 24|5@1+ (1,0) [0|31] "binary" Vector__XXX
 SG_ EngnExhstPrssrRgltrTmprtrStts : 29|3@1+ (1,0) [0|7] "" Vector__XXX
 SG_ EngnTrhrgrWstgtAttr1OprtnStts : 8|4@1+ (1,0) [0|15] "" Vector__XXX
 SG_ EngnTrhrgrWstgtAttr1Tmprtr : 40|8@1+ (1,-40) [-40|210] "degC" Vector__XXX
 SG_ EngnTrhrgrWstgtAttr2OprtnStts : 12|4@1+ (1,0) [0|15] "" Vector__XXX
 SG_ EngnTrhrgrWstgtAttr2PrlmnrFMI : 0|5@1+ (1,0) [0|31] "binary" Vector__XXX
 SG_ EngnTrhrgrWstgtAttr2TmprtrStts : 5|3@1+ (1,0) [0|7] "" Vector__XXX

BO_ 2566714110 EFTVI1: 8 Vector__XXX
 SG_ EngineFuelValve1OperationStatus : 56|4@1+ (1,0) [0|15] "" Vector__XXX
 SG_ EngineFuelValve1PreliminaryFMI : 32|5@1+ (1,0) [0|31] "binary" Vector__XXX
 SG_ EngineFuelValve2OperationStatus : 60|4@1+ (1,0) [0|15] "" Vector__XXX
 SG_ EngineFuelValve2PreliminaryFMI : 40|5@1+ (1,0) [0|31] "binary" Vector__XXX
 SG_ EngnDsrdThrttlVlv1Pstn : 0|8@1+ (0.4,0) [0|100] "%" Vector__XXX
 SG_ EngnDsrdThrttlVlv2Pstn : 16|8@1+ (0.4,0) [0|100] "%" Vector__XXX
 SG_ EngnFlVlv1TmprtrStts : 37|3@1+ (1,0) [0|7] "" Vector__XXX
 SG_ EngnFlVlv2TmprtrStts : 45|3@1+ (1,0) [0|7] "" Vector__XXX
 SG_ EngnThrttlVlv1OprtnStts : 48|4@1+ (1,0) [0|15] "" Vector__XXX
 SG_ EngnThrttlVlv1PrlmnrFMI : 8|5@1+ (1,0) [0|31] "binary" Vector__XXX
 SG_ EngnThrttlVlv1TmprtrStts : 13|3@1+ (1,0) [0|7] "" Vector__XXX
 SG_ EngnThrttlVlv2OprtnStts : 52|4@1+ (1,0) [0|15] "" Vector__XXX
 SG_ EngnThrttlVlv2PrlmnrFMI : 24|5@1+ (1,0) [0|31] "binary" Vector__XXX
 SG_ EngnThrttlVlv2Tmprtrstts : 29|3@1+ (1,0) [0|7] "" Vector__XXX

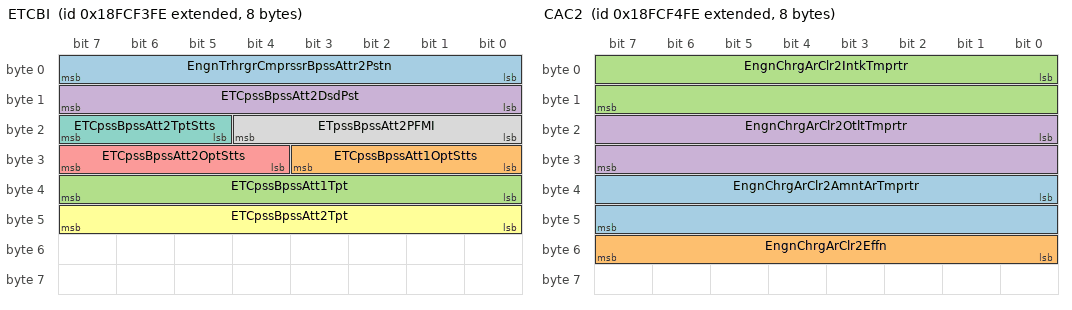
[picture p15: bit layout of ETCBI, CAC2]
BO_ 2566714366 ETCBI: 8 Vector__XXX
 SG_ EngnTrhrgrCmprssrBpssAttr2Pstn : 0|8@1+ (0.4,0) [0|100] "%" Vector__XXX
 SG_ ETCpssBpssAtt1OptStts : 24|4@1+ (1,0) [0|15] "" Vector__XXX
 SG_ ETCpssBpssAtt1Tpt : 32|8@1+ (1,-40) [-40|210] "degC" Vector__XXX
 SG_ ETCpssBpssAtt2DsdPst : 8|8@1+ (0.4,0) [0|100] "%" Vector__XXX
 SG_ ETCpssBpssAtt2OptStts : 28|4@1+ (1,0) [0|15] "" Vector__XXX
 SG_ ETCpssBpssAtt2Tpt : 40|8@1+ (1,-40) [-40|210] "degC" Vector__XXX
 SG_ ETCpssBpssAtt2TptStts : 21|3@1+ (1,0) [0|7] "" Vector__XXX
 SG_ ETpssBpssAtt2PFMI : 16|5@1+ (1,0) [0|31] "binary" Vector__XXX

BO_ 2566714622 CAC2: 8 Vector__XXX
 SG_ EngnChrgArClr2AmntArTmprtr : 32|16@1+ (0.03125,-273) [-273|1734.96875] "degC" Vector__XXX
 SG_ EngnChrgArClr2Effn : 48|8@1+ (0.4,0) [0|100] "%" Vector__XXX
 SG_ EngnChrgArClr2IntkTmprtr : 0|16@1+ (0.03125,-273) [-273|1734.96875] "degC" Vector__XXX
 SG_ EngnChrgArClr2OtltTmprtr : 16|16@1+ (0.03125,-273) [-273|1734.96875] "degC" Vector__XXX

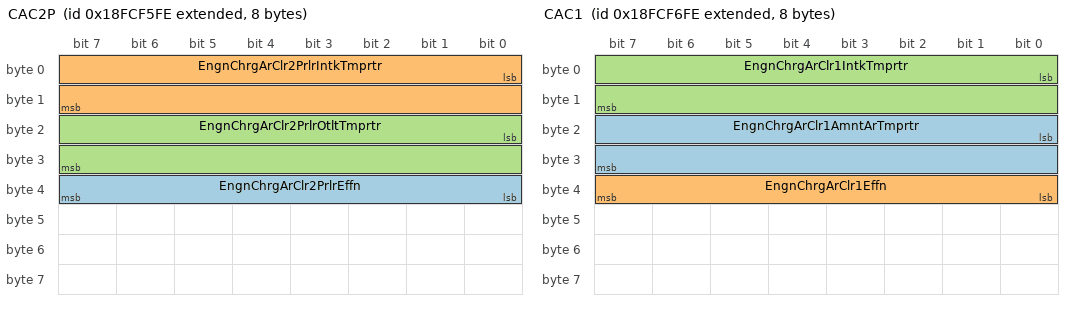
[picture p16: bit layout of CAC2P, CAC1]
BO_ 2566714878 CAC2P: 8 Vector__XXX
 SG_ EngnChrgArClr2PrlrEffn : 32|8@1+ (0.4,0) [0|100] "%" Vector__XXX
 SG_ EngnChrgArClr2PrlrIntkTmprtr : 0|16@1+ (0.03125,-273) [-273|1734.96875] "degC" Vector__XXX
 SG_ EngnChrgArClr2PrlrOtltTmprtr : 16|16@1+ (0.03125,-273) [-273|1734.96875] "degC" Vector__XXX

BO_ 2566715134 CAC1: 8 Vector__XXX
 SG_ EngnChrgArClr1AmntArTmprtr : 16|16@1+ (0.03125,-273) [-273|1734.96875] "degC" Vector__XXX
 SG_ EngnChrgArClr1Effn : 32|8@1+ (0.4,0) [0|100] "%" Vector__XXX
 SG_ EngnChrgArClr1IntkTmprtr : 0|16@1+ (0.03125,-273) [-273|1734.96875] "degC" Vector__XXX

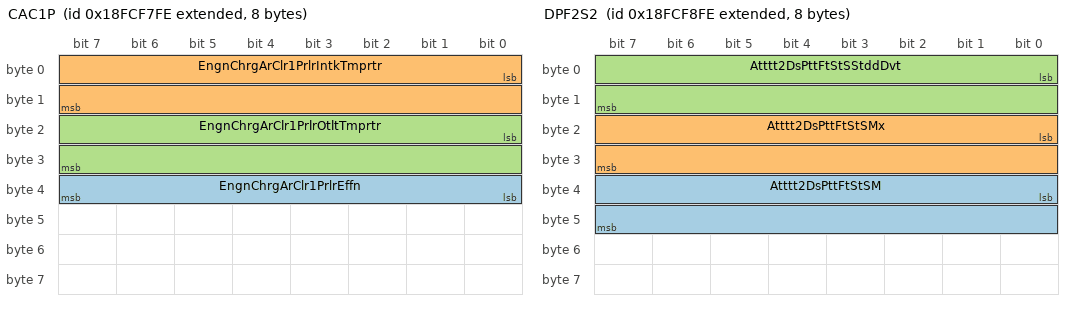
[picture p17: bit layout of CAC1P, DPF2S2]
BO_ 2566715390 CAC1P: 8 Vector__XXX
 SG_ EngnChrgArClr1PrlrEffn : 32|8@1+ (0.4,0) [0|100] "%" Vector__XXX
 SG_ EngnChrgArClr1PrlrIntkTmprtr : 0|16@1+ (0.03125,-273) [-273|1734.96875] "degC" Vector__XXX
 SG_ EngnChrgArClr1PrlrOtltTmprtr : 16|16@1+ (0.03125,-273) [-273|1734.96875] "degC" Vector__XXX

BO_ 2566715646 DPF2S2: 8 Vector__XXX
 SG_ Atttt2DsPttFtStSM : 32|16@1+ (0.0025,0) [0|160.6375] "%" Vector__XXX
 SG_ Atttt2DsPttFtStSMx : 16|16@1+ (0.0025,0) [0|160.6375] "%" Vector__XXX
 SG_ Atttt2DsPttFtStSStddDvt : 0|16@1+ (0.0025,0) [0|160.6375] "%" Vector__XXX

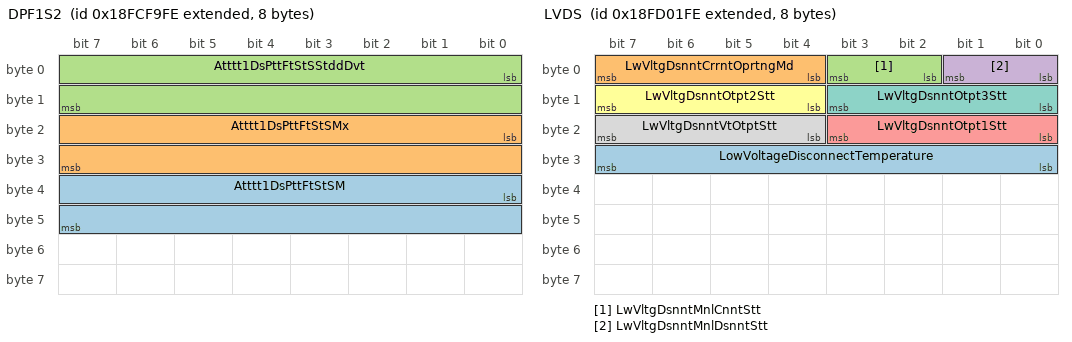
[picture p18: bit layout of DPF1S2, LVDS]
BO_ 2566715902 DPF1S2: 8 Vector__XXX
 SG_ Atttt1DsPttFtStSM : 32|16@1+ (0.0025,0) [0|160.6375] "%" Vector__XXX
 SG_ Atttt1DsPttFtStSMx : 16|16@1+ (0.0025,0) [0|160.6375] "%" Vector__XXX
 SG_ Atttt1DsPttFtStSStddDvt : 0|16@1+ (0.0025,0) [0|160.6375] "%" Vector__XXX

BO_ 2566717438 ET5: 8 Vector__XXX
 SG_ EngnExhstGsRrltn2MxrIntkTmprtr : 16|16@1+ (0.03125,-273) [-273|1734.96875] "degC" Vector__XXX
 SG_ EngnExhstGsRrltn2Tmprtr : 0|16@1+ (0.03125,-273) [-273|1734.96875] "degC" Vector__XXX

BO_ 2566717950 LVDS: 8 Vector__XXX
 SG_ LowVoltageDisconnectTemperature : 24|8@1+ (1,-40) [-40|210] "degC" Vector__XXX
 SG_ LwVltgDsnntCrrntOprtngMd : 4|4@1+ (1,0) [0|15] "" Vector__XXX
 SG_ LwVltgDsnntMnlCnntStt : 2|2@1+ (1,0) [0|3] "" Vector__XXX
 SG_ LwVltgDsnntMnlDsnntStt : 0|2@1+ (1,0) [0|3] "" Vector__XXX
 SG_ LwVltgDsnntOtpt1Stt : 16|4@1+ (1,0) [0|15] "" Vector__XXX
 SG_ LwVltgDsnntOtpt2Stt : 12|4@1+ (1,0) [0|15] "" Vector__XXX
 SG_ LwVltgDsnntOtpt3Stt : 8|4@1+ (1,0) [0|15] "" Vector__XXX
 SG_ LwVltgDsnntVtOtptStt : 20|4@1+ (1,0) [0|15] "" Vector__XXX

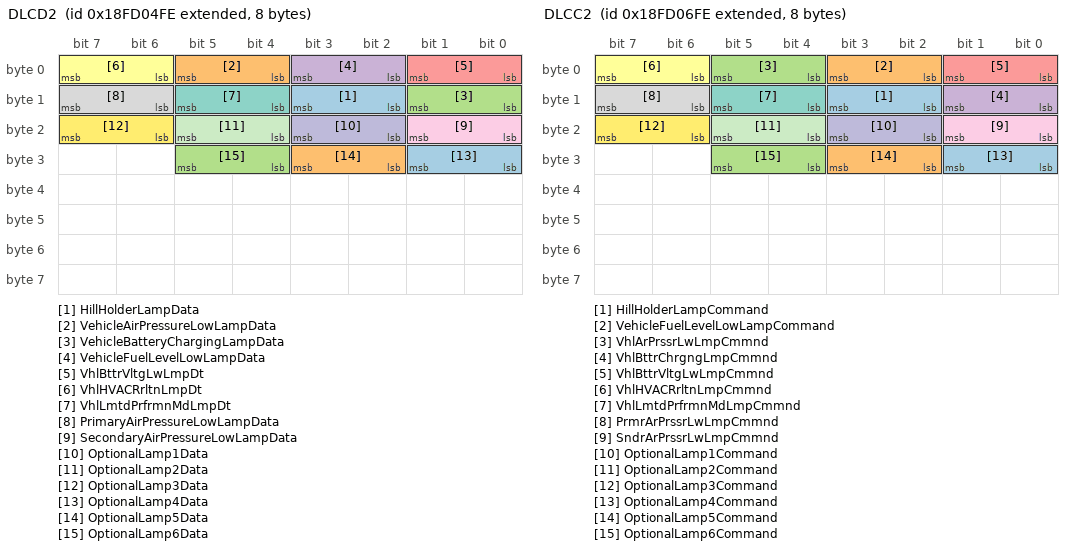
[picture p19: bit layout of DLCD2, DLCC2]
BO_ 2566718718 DLCD2: 8 Vector__XXX
 SG_ HillHolderLampData : 10|2@1+ (1,0) [0|3] "" Vector__XXX
 SG_ VehicleAirPressureLowLampData : 4|2@1+ (1,0) [0|3] "" Vector__XXX
 SG_ VehicleBatteryChargingLampData : 8|2@1+ (1,0) [0|3] "" Vector__XXX
 SG_ VehicleFuelLevelLowLampData : 2|2@1+ (1,0) [0|3] "" Vector__XXX
 SG_ VhlBttrVltgLwLmpDt : 0|2@1+ (1,0) [0|3] "" Vector__XXX
 SG_ VhlHVACRrltnLmpDt : 6|2@1+ (1,0) [0|3] "" Vector__XXX
 SG_ VhlLmtdPrfrmnMdLmpDt : 12|2@1+ (1,0) [0|3] "" Vector__XXX
 SG_ PrimaryAirPressureLowLampData : 14|2@1+ (1,0) [0|3] "" Vector__XXX
 SG_ SecondaryAirPressureLowLampData : 16|2@1+ (1,0) [0|3] "" Vector__XXX
 SG_ OptionalLamp1Data : 18|2@1+ (1,0) [0|3] "" Vector__XXX
 SG_ OptionalLamp2Data : 20|2@1+ (1,0) [0|3] "" Vector__XXX
 SG_ OptionalLamp3Data : 22|2@1+ (1,0) [0|3] "" Vector__XXX
 SG_ OptionalLamp4Data : 24|2@1+ (1,0) [0|3] "" Vector__XXX
 SG_ OptionalLamp5Data : 26|2@1+ (1,0) [0|3] "" Vector__XXX
 SG_ OptionalLamp6Data : 28|2@1+ (1,0) [0|3] "" Vector__XXX

BO_ 2566718974 DLCD1: 8 Vector__XXX
 SG_ CmprssnBrkEnlSwthIndtrLmpDt : 10|2@1+ (1,0) [0|3] "" Vector__XXX
 SG_ EngineAmberWarningLampData : 2|2@1+ (1,0) [0|3] "" Vector__XXX
 SG_ EngineBrakeActiveLampData : 8|2@1+ (1,0) [0|3] "" Vector__XXX
 SG_ EngineCoolantLevelLowLampData : 16|2@1+ (1,0) [0|3] "" Vector__XXX
 SG_ EngineOilPressureLowLampData : 12|2@1+ (1,0) [0|3] "" Vector__XXX
 SG_ EngineProtectLampData : 0|2@1+ (1,0) [0|3] "" Vector__XXX
 SG_ EngineRedStopLampData : 4|2@1+ (1,0) [0|3] "" Vector__XXX
 SG_ EngineSpeedHighLampData : 30|2@1+ (1,0) [0|3] "" Vector__XXX
 SG_ EngineSpeedVeryHighLampData : 32|2@1+ (1,0) [0|3] "" Vector__XXX
 SG_ EngineWaitToStartLampData : 62|2@1+ (1,0) [0|3] "" Vector__XXX
 SG_ EngnArFltrRstrtnLmpDt : 20|2@1+ (1,0) [0|3] "" Vector__XXX
 SG_ EngnClntTmprtrHghLmpDt : 14|2@1+ (1,0) [0|3] "" Vector__XXX
 SG_ EngnCntrlMdl1RdfrUsLmpDt : 24|2@1+ (1,0) [0|3] "" Vector__XXX
 SG_ EngnCntrlMdl2RdfrUsLmpDt : 26|2@1+ (1,0) [0|3] "" Vector__XXX
 SG_ EngnCntrlMdl3RdfrUsLmpDt : 28|2@1+ (1,0) [0|3] "" Vector__XXX
 SG_ EngnFlFltrRstrtdLmpDt : 22|2@1+ (1,0) [0|3] "" Vector__XXX
 SG_ EngnIdlMngmntAtvLmpDt : 18|2@1+ (1,0) [0|3] "" Vector__XXX
 SG_ OBDMalfunctionIndicatorLampData : 6|2@1+ (1,0) [0|3] "" Vector__XXX
 SG_ VhlAlrtnRtLmtLmpDt : 34|2@1+ (1,0) [0|3] "" Vector__XXX
 SG_ EngnStpStrtAtmtStpAtvLmpDt : 38|2@1+ (1,0) [0|3] "" Vector__XXX
 SG_ EngnStpStrtAtmtStrtFldLmpDt : 40|2@1+ (1,0) [0|3] "" Vector__XXX
 SG_ EngineStopStartEnabledLampData : 42|2@1+ (1,0) [0|3] "" Vector__XXX
 SG_ EngnOlTmprtrHghLmpDt : 44|2@1+ (1,0) [0|3] "" Vector__XXX
 SG_ EngnFlTmprtrHghLmpDt : 46|2@1+ (1,0) [0|3] "" Vector__XXX
 SG_ EngnIntrlrTmprtrHghLmpDt : 48|2@1+ (1,0) [0|3] "" Vector__XXX
 SG_ EngineAirShutoffLampData : 50|2@1+ (1,0) [0|3] "" Vector__XXX

BO_ 2566719230 DLCC2: 8 Vector__XXX
 SG_ HillHolderLampCommand : 10|2@1+ (1,0) [0|3] "" Vector__XXX
 SG_ VehicleFuelLevelLowLampCommand : 2|2@1+ (1,0) [0|3] "" Vector__XXX
 SG_ VhlArPrssrLwLmpCmmnd : 4|2@1+ (1,0) [0|3] "" Vector__XXX
 SG_ VhlBttrChrgngLmpCmmnd : 8|2@1+ (1,0) [0|3] "" Vector__XXX
 SG_ VhlBttrVltgLwLmpCmmnd : 0|2@1+ (1,0) [0|3] "" Vector__XXX
 SG_ VhlHVACRrltnLmpCmmnd : 6|2@1+ (1,0) [0|3] "" Vector__XXX
 SG_ VhlLmtdPrfrmnMdLmpCmmnd : 12|2@1+ (1,0) [0|3] "" Vector__XXX
 SG_ PrmrArPrssrLwLmpCmmnd : 14|2@1+ (1,0) [0|3] "" Vector__XXX
 SG_ SndrArPrssrLwLmpCmmnd : 16|2@1+ (1,0) [0|3] "" Vector__XXX
 SG_ OptionalLamp1Command : 18|2@1+ (1,0) [0|3] "" Vector__XXX
 SG_ OptionalLamp2Command : 20|2@1+ (1,0) [0|3] "" Vector__XXX
 SG_ OptionalLamp3Command : 22|2@1+ (1,0) [0|3] "" Vector__XXX
 SG_ OptionalLamp4Command : 24|2@1+ (1,0) [0|3] "" Vector__XXX
 SG_ OptionalLamp5Command : 26|2@1+ (1,0) [0|3] "" Vector__XXX
 SG_ OptionalLamp6Command : 28|2@1+ (1,0) [0|3] "" Vector__XXX

BO_ 2566719486 DLCC1: 8 Vector__XXX
 SG_ CmprssnBrkEnlSwthIndtrLmpCmmnd : 10|2@1+ (1,0) [0|3] "" Vector__XXX
 SG_ EngineAmberWarningLampCommand : 2|2@1+ (1,0) [0|3] "" Vector__XXX
 SG_ EngineBrakeActiveLampCommand : 8|2@1+ (1,0) [0|3] "" Vector__XXX
 SG_ EngineOilPressureLowLampCommand : 12|2@1+ (1,0) [0|3] "" Vector__XXX
 SG_ EngineProtectLampCommand : 0|2@1+ (1,0) [0|3] "" Vector__XXX
 SG_ EngineRedStopLampCommand : 4|2@1+ (1,0) [0|3] "" Vector__XXX
 SG_ EngineSpeedHighLampCommand : 30|2@1+ (1,0) [0|3] "" Vector__XXX
 SG_ EngineSpeedVeryHighLampCommand : 32|2@1+ (1,0) [0|3] "" Vector__XXX
 SG_ EngnArFltrRstrtnLmpCmmnd : 20|2@1+ (1,0) [0|3] "" Vector__XXX
 SG_ EngnClntLvlLwLmpCmmnd : 16|2@1+ (1,0) [0|3] "" Vector__XXX
 SG_ EngnClntTmprtrHghLmpCmmnd : 14|2@1+ (1,0) [0|3] "" Vector__XXX
 SG_ EngnCntrlMdl1RdfrUsLmpCmmnd : 24|2@1+ (1,0) [0|3] "" Vector__XXX
 SG_ EngnCntrlMdl2RdfrUsLmpCmmnd : 26|2@1+ (1,0) [0|3] "" Vector__XXX
 SG_ EngnCntrlMdl3RdfrUsLmpCmmnd : 28|2@1+ (1,0) [0|3] "" Vector__XXX
 SG_ EngnFlFltrRstrtdLmpCmmnd : 22|2@1+ (1,0) [0|3] "" Vector__XXX
 SG_ EngnIdlMngmntAtvLmpCmmnd : 18|2@1+ (1,0) [0|3] "" Vector__XXX
 SG_ EngnIdlMngmntPndngEvntLmpCmmnd : 36|2@1+ (1,0) [0|3] "" Vector__XXX
 SG_ OBDMlfntnIndtrLmpCmmnd : 6|2@1+ (1,0) [0|3] "" Vector__XXX
 SG_ VhlAlrtnRtLmtLmpCmmnd : 34|2@1+ (1,0) [0|3] "" Vector__XXX
 SG_ EngnStpStrtAtmtStpAtvLmpCmmnd : 38|2@1+ (1,0) [0|3] "" Vector__XXX
 SG_ EngnStpStrtAtmtStrtFldLmpCmmnd : 40|2@1+ (1,0) [0|3] "" Vector__XXX
 SG_ EngnStpStrtEnldLmpCmmnd : 42|2@1+ (1,0) [0|3] "" Vector__XXX
 SG_ EngnOlTmprtrHghLmpCmmnd : 44|2@1+ (1,0) [0|3] "" Vector__XXX
 SG_ EngnFlTmprtrHghLmpCmmnd : 46|2@1+ (1,0) [0|3] "" Vector__XXX
 SG_ EngnIntrlrTmprtrHghLmpCmmnd : 48|2@1+ (1,0) [0|3] "" Vector__XXX
 SG_ EngineAirShutoffLampCommand : 50|2@1+ (1,0) [0|3] "" Vector__XXX

BO_ 2566719998 HRLFC: 8 Vector__XXX
 SG_ EngineTripFuelHighResolution : 0|32@1+ (0.001,0) [0|4211081.215] "l" Vector__XXX
 SG_ EngnTtlFlUsdHghRsltn : 32|32@1+ (0.001,0) [0|4211081.215] "l" Vector__XXX

CM_ BO_ 2566697726 "Switched Power Output Current";
CM_ SG_ 2566697726 SwitchedOutput10Current "Switched Output #10 Current: Measured electrical current flowing out of Power Distribution Module (PDM) Switched Output #10.";
CM_ SG_ 2566697726 SwitchedOutput11Current "Switched Output #11 Current: Measured electrical current flowing out of Power Distribution Module (PDM) Switched Output #11.";
CM_ SG_ 2566697726 SwitchedOutput12Current "Switched Output #12 Current: Measured electrical current flowing out of Power Distribution Module (PDM) Switched Output #12.";
CM_ SG_ 2566697726 SwitchedOutput13Current "Switched Output #13 Current: Measured electrical current flowing out of Power Distribution Module (PDM) Switched Output #13.";
CM_ SG_ 2566697726 SwitchedOutput14Current "Switched Output #14 Current: Measured electrical current flowing out of Power Distribution Module (PDM) Switched Output #14.";
CM_ SG_ 2566697726 SwitchedOutput15Current "Switched Output #15 Current: Measured electrical current flowing out of Power Distribution Module (PDM) Switched Output #15.";
CM_ SG_ 2566697726 SwitchedOutput16Current "Switched Output #16 Current: Measured electrical current flowing out of Power Distribution Module (PDM) Switched Output #16.";
CM_ SG_ 2566697726 SwitchedOutput17Current "Switched Output #17 Current: Measured electrical current flowing out of Power Distribution Module (PDM) Switched Output #17.";
CM_ SG_ 2566697726 SwitchedOutput18Current "Switched Output #18 Current: Measured electrical current flowing out of Power Distribution Module (PDM) Switched Output #18.";
CM_ SG_ 2566697726 SwitchedOutput19Current "Switched Output #19 Current: Measured electrical current flowing out of Power Distribution Module (PDM) Switched Output #19.";
CM_ SG_ 2566697726 SwitchedOutput1Current "Switched Output #1 Current: Measured electrical current flowing out of Power Distribution Module (PDM) Switched Output #1.";
CM_ SG_ 2566697726 SwitchedOutput20Current "Switched Output #20 Current: Measured electrical current flowing out of Power Distribution Module (PDM) Switched Output #20.";
CM_ SG_ 2566697726 SwitchedOutput21Current "Switched Output #21 Current: Measured electrical current flowing out of Power Distribution Module (PDM) Switched Output #21.";
CM_ SG_ 2566697726 SwitchedOutput22Current "Switched Output #22 Current: Measured electrical current flowing out of Power Distribution Module (PDM) Switched Output #22.";
CM_ SG_ 2566697726 SwitchedOutput23Current "Switched Output #23 Current: Measured electrical current flowing out of Power Distribution Module (PDM) Switched Output #23.";
CM_ SG_ 2566697726 SwitchedOutput24Current "Switched Output #24 Current: Measured electrical current flowing out of Power Distribution Module (PDM) Switched Output #24.";
CM_ SG_ 2566697726 SwitchedOutput25Current "Switched Output #25 Current: Measured electrical current flowing out of Power Distribution Module (PDM) Switched Output #25.";
CM_ SG_ 2566697726 SwitchedOutput26Current "Switched Output #26 Current: Measured electrical current flowing out of Power Distribution Module (PDM) Switched Output #26.";
CM_ SG_ 2566697726 SwitchedOutput27Current "Switched Output #27 Current: Measured electrical current flowing out of Power Distribution Module (PDM) Switched Output #27.";
CM_ SG_ 2566697726 SwitchedOutput28Current "Switched Output #28 Current: Measured electrical current flowing out of Power Distribution Module (PDM) Switched Output #28.";
CM_ SG_ 2566697726 SwitchedOutput29Current "Switched Output #29 Current: Measured electrical current flowing out of Power Distribution Module (PDM) Switched Output #29.";
CM_ SG_ 2566697726 SwitchedOutput2Current "Switched Output #2 Current: Measured electrical current flowing out of Power Distribution Module (PDM) Switched Output #2.";
CM_ SG_ 2566697726 SwitchedOutput30Current "Switched Output #30 Current: Measured electrical current flowing out of Power Distribution Module (PDM) Switched Output #30.";
CM_ SG_ 2566697726 SwitchedOutput31Current "Switched Output #31 Current: Measured electrical current flowing out of Power Distribution Module (PDM) Switched Output #31.";
CM_ SG_ 2566697726 SwitchedOutput32Current "Switched Output #32 Current: Measured electrical current flowing out of Power Distribution Module (PDM) Switched Output #32.";
CM_ SG_ 2566697726 SwitchedOutput3Current "Switched Output #3 Current: Measured electrical current flowing out of Power Distribution Module (PDM) Switched Output #3.";
CM_ SG_ 2566697726 SwitchedOutput4Current "Switched Output #4 Current: Measured electrical current flowing out of Power Distribution Module (PDM) Switched Output #4.";
CM_ SG_ 2566697726 SwitchedOutput5Current "Switched Output #5 Current: Measured electrical current flowing out of Power Distribution Module (PDM) Switched Output #5.";
CM_ SG_ 2566697726 SwitchedOutput6Current "Switched Output #6 Current: Measured electrical current flowing out of Power Distribution Module (PDM) Switched Output #6.";
CM_ SG_ 2566697726 SwitchedOutput7Current "Switched Output #7 Current: Measured electrical current flowing out of Power Distribution Module (PDM) Switched Output #7.";
CM_ SG_ 2566697726 SwitchedOutput8Current "Switched Output #8 Current: Measured electrical current flowing out of Power Distribution Module (PDM) Switched Output #8.";
CM_ SG_ 2566697726 SwitchedOutput9Current "Switched Output #9 Current: Measured electrical current flowing out of Power Distribution Module (PDM) Switched Output #9.";
CM_ BO_ 2566697982 "Fused Power Output Current";
CM_ SG_ 2566697982 FusedOutput10Current "Fused Output #10 Current: Measured electrical current flowing out of Power Distribution Module (PDM) Fused Output #10.";
CM_ SG_ 2566697982 FusedOutput11Current "Fused Output #11 Current: Measured electrical current flowing out of Power Distribution Module (PDM) Fused Output #11.";
CM_ SG_ 2566697982 FusedOutput12Current "Fused Output #12 Current: Measured electrical current flowing out of Power Distribution Module (PDM) Fused Output #12.";
CM_ SG_ 2566697982 FusedOutput13Current "Fused Output #13 Current: Measured electrical current flowing out of Power Distribution Module (PDM) Fused Output #13.";
CM_ SG_ 2566697982 FusedOutput14Current "Fused Output #14 Current: Measured electrical current flowing out of Power Distribution Module (PDM) Fused Output #14.";
CM_ SG_ 2566697982 FusedOutput15Current "Fused Output #15 Current: Measured electrical current flowing out of Power Distribution Module (PDM) Fused Output #15.";
CM_ SG_ 2566697982 FusedOutput16Current "Fused Output #16 Current: Measured electrical current flowing out of Power Distribution Module (PDM) Fused Output #16.";
CM_ SG_ 2566697982 FusedOutput17Current "Fused Output #17 Current: Measured electrical current flowing out of Power Distribution Module (PDM) Fused Output #17.";
CM_ SG_ 2566697982 FusedOutput18Current "Fused Output #18 Current: Measured electrical current flowing out of Power Distribution Module (PDM) Fused Output #18.";
CM_ SG_ 2566697982 FusedOutput19Current "Fused Output #19 Current: Measured electrical current flowing out of Power Distribution Module (PDM) Fused Output #19.";
CM_ SG_ 2566697982 FusedOutput1Current "Fused Output #1 Current: Measured electrical current flowing out of Power Distribution Module (PDM) Fused Output #1.";
CM_ SG_ 2566697982 FusedOutput20Current "Fused Output #20 Current: Measured electrical current flowing out of Power Distribution Module (PDM) Fused Output #20.";
CM_ SG_ 2566697982 FusedOutput21Current "Fused Output #21 Current: Measured electrical current flowing out of Power Distribution Module (PDM) Fused Output #21.";
CM_ SG_ 2566697982 FusedOutput22Current "Fused Output #22 Current: Measured electrical current flowing out of Power Distribution Module (PDM) Fused Output #22.";
CM_ SG_ 2566697982 FusedOutput23Current "Fused Output #23 Current: Measured electrical current flowing out of Power Distribution Module (PDM) Fused Output #23.";
CM_ SG_ 2566697982 FusedOutput24Current "Fused Output #24 Current: Measured electrical current flowing out of Power Distribution Module (PDM) Fused Output #24.";
CM_ SG_ 2566697982 FusedOutput25Current "Fused Output #25 Current: Measured electrical current flowing out of Power Distribution Module (PDM) Fused Output #25.";
CM_ SG_ 2566697982 FusedOutput26Current "Fused Output #26 Current: Measured electrical current flowing out of Power Distribution Module (PDM) Fused Output #26.";
CM_ SG_ 2566697982 FusedOutput27Current "Fused Output #27 Current: Measured electrical current flowing out of Power Distribution Module (PDM) Fused Output #27.";
CM_ SG_ 2566697982 FusedOutput28Current "Fused Output #28 Current: Measured electrical current flowing out of Power Distribution Module (PDM) Fused Output #28.";
CM_ SG_ 2566697982 FusedOutput29Current "Fused Output #29 Current: Measured electrical current flowing out of Power Distribution Module (PDM) Fused Output #29.";
CM_ SG_ 2566697982 FusedOutput2Current "Fused Output #2 Current: Measured electrical current flowing out of Power Distribution Module (PDM) Fused Output #2.";
CM_ SG_ 2566697982 FusedOutput30Current "Fused Output #30 Current: Measured electrical current flowing out of Power Distribution Module (PDM) Fused Output #30.";
CM_ SG_ 2566697982 FusedOutput31Current "Fused Output #31 Current: Measured electrical current flowing out of Power Distribution Module (PDM) Fused Output #31.";
CM_ SG_ 2566697982 FusedOutput32Current "Fused Output #32 Current: Measured electrical current flowing out of Power Distribution Module (PDM) Fused Output #32.";
CM_ SG_ 2566697982 FusedOutput3Current "Fused Output #3 Current: Measured electrical current flowing out of Power Distribution Module (PDM) Fused Output #3.";
CM_ SG_ 2566697982 FusedOutput4Current "Fused Output #4 Current: Measured electrical current flowing out of Power Distribution Module (PDM) Fused Output #4.";
CM_ SG_ 2566697982 FusedOutput5Current "Fused Output #5 Current: Measured electrical current flowing out of Power Distribution Module (PDM) Fused Output #5.";
CM_ SG_ 2566697982 FusedOutput6Current "Fused Output #6 Current: Measured electrical current flowing out of Power Distribution Module (PDM) Fused Output #6.";
CM_ SG_ 2566697982 FusedOutput7Current "Fused Output #7 Current: Measured electrical current flowing out of Power Distribution Module (PDM) Fused Output #7.";
CM_ SG_ 2566697982 FusedOutput8Current "Fused Output #8 Current: Measured electrical current flowing out of Power Distribution Module (PDM) Fused Output #8.";
CM_ SG_ 2566697982 FusedOutput9Current "Fused Output #9 Current: Measured electrical current flowing out of Power Distribution Module (PDM) Fused Output #9.";
CM_ BO_ 2566698238 "Switched Power Output Status";
CM_ SG_ 2566698238 SwitchedOutput1 "Switched Output #1: State of Switched Output #1. Used to indicate the output state.00b = Output off01b = Output on10b = Reserved11b = Take no action";
CM_ SG_ 2566698238 SwitchedOutput10 "Switched Output #10: State of Switched Output #10. Used to indicate the output state.00b = Output off01b = Output on10b = Reserved11b = Take no action";
CM_ SG_ 2566698238 SwitchedOutput11 "Switched Output #11: State of Switched Output #11. Used to indicate the output state.00b = Output off01b = Output on10b = Reserved11b = Take no action";
CM_ SG_ 2566698238 SwitchedOutput12 "Switched Output #12: State of Switched Output #12. Used to indicate the output state.00b = Output off01b = Output on10b = Reserved11b = Take no action";
CM_ SG_ 2566698238 SwitchedOutput13 "Switched Output #13: State of Switched Output #13. Used to indicate the output state.00b = Output off01b = Output on10b = Reserved11b = Take no action";
CM_ SG_ 2566698238 SwitchedOutput14 "Switched Output #14: State of Switched Output #14. Used to indicate the output state.00b = Output off01b = Output on10b = Reserved11b = Take no action";
CM_ SG_ 2566698238 SwitchedOutput15 "Switched Output #15: State of Switched Output #15. Used to indicate the output state.00b = Output off01b = Output on10b = Reserved11b = Take no action";
CM_ SG_ 2566698238 SwitchedOutput16 "Switched Output #16: State of Switched Output #16. Used to indicate the output state.00b = Output off01b = Output on10b = Reserved11b = Take no action";
CM_ SG_ 2566698238 SwitchedOutput17 "Switched Output #17: State of Switched Output #17. Used to indicate the output state.00b = Output off01b = Output on10b = Reserved11b = Take no action";
CM_ SG_ 2566698238 SwitchedOutput18 "Switched Output #18: State of Switched Output #18. Used to indicate the output state.00b = Output off01b = Output on10b = Reserved11b = Take no action";
CM_ SG_ 2566698238 SwitchedOutput19 "Switched Output #19: State of Switched Output #19. Used to indicate the output state.00b = Output off01b = Output on10b = Reserved11b = Take no action";
CM_ SG_ 2566698238 SwitchedOutput2 "Switched Output #2: State of Switched Output #2. Used to indicate the output state.00b = Output off01b = Output on10b = Reserved11b = Take no action";
CM_ SG_ 2566698238 SwitchedOutput20 "Switched Output #20: State of Switched Output #20. Used to indicate the output state.00b = Output off01b = Output on10b = Reserved11b = Take no action";
CM_ SG_ 2566698238 SwitchedOutput21 "Switched Output #21: State of Switched Output #21. Used to indicate the output state.00b = Output off01b = Output on10b = Reserved11b = Take no action";
CM_ SG_ 2566698238 SwitchedOutput22 "Switched Output #22: State of Switched Output #22. Used to indicate the output state.00b = Output off01b = Output on10b = Reserved11b = Take no action";
CM_ SG_ 2566698238 SwitchedOutput23 "Switched Output #23: State of Switched Output #23. Used to indicate the output state.00b = Output off01b = Output on10b = Reserved11b = Take no action";
CM_ SG_ 2566698238 SwitchedOutput24 "Switched Output #24: State of Switched Output #24. Used to indicate the output state.00b = Output off01b = Output on10b = Reserved11b = Take no action";
CM_ SG_ 2566698238 SwitchedOutput25 "Switched Output #25: State of Switched Output #25. Used to indicate the output state.00b = Output off01b = Output on10b = Reserved11b = Take no action";
CM_ SG_ 2566698238 SwitchedOutput26 "Switched Output #26: State of Switched Output #26. Used to indicate the output state.00b = Output off01b = Output on10b = Reserved11b = Take no action";
CM_ SG_ 2566698238 SwitchedOutput27 "Switched Output #27: State of Switched Output #27. Used to indicate the output state.00b = Output off01b = Output on10b = Reserved11b = Take no action";
CM_ SG_ 2566698238 SwitchedOutput28 "Switched Output #28: State of Switched Output #28. Used to indicate the output state.00b = Output off01b = Output on10b = Reserved11b = Take no action";
CM_ SG_ 2566698238 SwitchedOutput29 "Switched Output #29: State of Switched Output #29. Used to indicate the output state.00b = Output off01b = Output on10b = Reserved11b = Take no action";
CM_ SG_ 2566698238 SwitchedOutput3 "Switched Output #3: State of Switched Output #3. Used to indicate the output state.00b = Output off01b = Output on10b = Reserved11b = Take no action";
CM_ SG_ 2566698238 SwitchedOutput30 "Switched Output #30: State of Switched Output #30. Used to indicate the output state.00b = Output off01b = Output on10b = Reserved11b = Take no action";
CM_ SG_ 2566698238 SwitchedOutput31 "Switched Output #31: State of Switched Output #31. Used to indicate the output state.00b = Output off01b = Output on10b = Reserved11b = Take no action";
CM_ SG_ 2566698238 SwitchedOutput32 "Switched Output #32: State of Switched Output #32. Used to indicate the output state.00b = Output off01b = Output on10b = Reserved11b = Take no action";
CM_ SG_ 2566698238 SwitchedOutput4 "Switched Output #4: State of Switched Output #4. Used to indicate the output state.00b = Output off01b = Output on10b = Reserved11b = Take no action";
CM_ SG_ 2566698238 SwitchedOutput5 "Switched Output #5: State of Switched Output #5. Used to indicate the output state.00b = Output off01b = Output on10b = Reserved11b = Take no action";
CM_ SG_ 2566698238 SwitchedOutput6 "Switched Output #6: State of Switched Output #6. Used to indicate the output state.00b = Output off01b = Output on10b = Reserved11b = Take no action";
CM_ SG_ 2566698238 SwitchedOutput7 "Switched Output #7: State of Switched Output #7. Used to indicate the output state.00b = Output off01b = Output on10b = Reserved11b = Take no action";
CM_ SG_ 2566698238 SwitchedOutput8 "Switched Output #8: State of Switched Output #8. Used to indicate the output state.00b = Output off01b = Output on10b = Reserved11b = Take no action";
CM_ SG_ 2566698238 SwitchedOutput9 "Switched Output #9: State of Switched Output #9. Used to indicate the output state.00b = Output off01b = Output on10b = Reserved11b = Take no action";
CM_ BO_ 2566698494 "Fused Power Output Status";
CM_ SG_ 2566698494 FusedOutput1 "Fused Output #1: State of Fused Output #1. Used to indicate the output state.00b = Output not powered01b = Output powered10b = Reserved11b = Take no action";
CM_ SG_ 2566698494 FusedOutput10 "Fused Output #10: State of Fused Output #10. Used to indicate the output state.00b = Output not powered01b = Output powered10b = Reserved11b = Take no action";
CM_ SG_ 2566698494 FusedOutput11 "Fused Output #11: State of Fused Output #11. Used to indicate the output state.00b = Output not powered01b = Output powered10b = Reserved11b = Take no action";
CM_ SG_ 2566698494 FusedOutput12 "Fused Output #12: State of Fused Output #12. Used to indicate the output state.00b = Output not powered01b = Output powered10b = Reserved11b = Take no action";
CM_ SG_ 2566698494 FusedOutput13 "Fused Output #13: State of Fused Output #13. Used to indicate the output state.00b = Output not powered01b = Output powered10b = Reserved11b = Take no action";
CM_ SG_ 2566698494 FusedOutput14 "Fused Output #14: State of Fused Output #14. Used to indicate the output state.00b = Output not powered01b = Output powered10b = Reserved11b = Take no action";
CM_ SG_ 2566698494 FusedOutput15 "Fused Output #15: State of Fused Output #15. Used to indicate the output state.00b = Output not powered01b = Output powered10b = Reserved11b = Take no action";
CM_ SG_ 2566698494 FusedOutput16 "Fused Output #16: State of Fused Output #16. Used to indicate the output state.00b = Output not powered01b = Output powered10b = Reserved11b = Take no action";
CM_ SG_ 2566698494 FusedOutput17 "Fused Output #17: State of Fused Output #17. Used to indicate the output state.00b = Output not powered01b = Output powered10b = Reserved11b = Take no action";
CM_ SG_ 2566698494 FusedOutput18 "Fused Output #18: State of Fused Output #18. Used to indicate the output state.00b = Output not powered01b = Output powered10b = Reserved11b = Take no action";
CM_ SG_ 2566698494 FusedOutput19 "Fused Output #19: State of Fused Output #19. Used to indicate the output state.00b = Output not powered01b = Output powered10b = Reserved11b = Take no action";
CM_ SG_ 2566698494 FusedOutput2 "Fused Output #2: State of Fused Output #2. Used to indicate the output state.00b = Output not powered01b = Output powered10b = Reserved11b = Take no action";
CM_ SG_ 2566698494 FusedOutput20 "Fused Output #20: State of Fused Output #20. Used to indicate the output state.00b = Output not powered01b = Output powered10b = Reserved11b = Take no action";
CM_ SG_ 2566698494 FusedOutput21 "Fused Output #21: State of Fused Output #21. Used to indicate the output state.00b = Output not powered01b = Output powered10b = Reserved11b = Take no action";
CM_ SG_ 2566698494 FusedOutput22 "Fused Output #22: State of Fused Output #22. Used to indicate the output state.00b = Output not powered01b = Output powered10b = Reserved11b = Take no action";
CM_ SG_ 2566698494 FusedOutput23 "Fused Output #23: State of Fused Output #23. Used to indicate the output state.00b = Output not powered01b = Output powered10b = Reserved11b = Take no action";
CM_ SG_ 2566698494 FusedOutput24 "Fused Output #24: State of Fused Output #24. Used to indicate the output state.00b = Output not powered01b = Output powered10b = Reserved11b = Take no action";
CM_ SG_ 2566698494 FusedOutput25 "Fused Output #25: State of Fused Output #25. Used to indicate the output state.00b = Output not powered01b = Output powered10b = Reserved11b = Take no action";
CM_ SG_ 2566698494 FusedOutput26 "Fused Output #26: State of Fused Output #26. Used to indicate the output state.00b = Output not powered01b = Output powered10b = Reserved11b = Take no action";
CM_ SG_ 2566698494 FusedOutput27 "Fused Output #27: State of Fused Output #27. Used to indicate the output state.00b = Output not powered01b = Output powered10b = Reserved11b = Take no action";
CM_ SG_ 2566698494 FusedOutput28 "Fused Output #28: State of Fused Output #28. Used to indicate the output state.00b = Output not powered01b = Output powered10b = Reserved11b = Take no action";
CM_ SG_ 2566698494 FusedOutput29 "Fused Output #29: State of Fused Output #29. Used to indicate the output state.00b = Output not powered01b = Output powered10b = Reserved11b = Take no action";
CM_ SG_ 2566698494 FusedOutput3 "Fused Output #3: State of Fused Output #3. Used to indicate the output state.00b = Output not powered01b = Output powered10b = Reserved11b = Take no action";
CM_ SG_ 2566698494 FusedOutput30 "Fused Output #30: State of Fused Output #30. Used to indicate the output state.00b = Output not powered01b = Output powered10b = Reserved11b = Take no action";
CM_ SG_ 2566698494 FusedOutput31 "Fused Output #31: State of Fused Output #31. Used to indicate the output state.00b = Output not powered01b = Output powered10b = Reserved11b = Take no action";
CM_ SG_ 2566698494 FusedOutput32 "Fused Output #32: State of Fused Output #32. Used to indicate the output state.00b = Output not powered01b = Output powered10b = Reserved11b = Take no action";
CM_ SG_ 2566698494 FusedOutput4 "Fused Output #4: State of Fused Output #4. Used to indicate the output state.00b = Output not powered01b = Output powered10b = Reserved11b = Take no action";
CM_ SG_ 2566698494 FusedOutput5 "Fused Output #5: State of Fused Output #5. Used to indicate the output state.00b = Output not powered01b = Output powered10b = Reserved11b = Take no action";
CM_ SG_ 2566698494 FusedOutput6 "Fused Output #6: State of Fused Output #6. Used to indicate the output state.00b = Output not powered01b = Output powered10b = Reserved11b = Take no action";
CM_ SG_ 2566698494 FusedOutput7 "Fused Output #7: State of Fused Output #7. Used to indicate the output state.00b = Output not powered01b = Output powered10b = Reserved11b = Take no action";
CM_ SG_ 2566698494 FusedOutput8 "Fused Output #8: State of Fused Output #8. Used to indicate the output state.00b = Output not powered01b = Output powered10b = Reserved11b = Take no action";
CM_ SG_ 2566698494 FusedOutput9 "Fused Output #9: State of Fused Output #9. Used to indicate the output state.00b = Output not powered01b = Output powered10b = Reserved11b = Take no action";
CM_ BO_ 2566698750 "Vehicle Electrical Power 5";
CM_ SG_ 2566698750 SLIBatteryPackCapacity "SLI Battery Pack Capacity: Original or rated total reserve capacity of the battery pack used for starting the engine, for lighting, and for ignition (SLI).This parameter shall be used to report the capacity of the battery pack.  If the capacity of in...";
CM_ SG_ 2566698750 SLIBatteryPackHealth "SLI Battery Pack Health: Capacity of the battery pack relative to its original specification for the battery pack used for starting the engine, for lighting, and for ignition (SLI). 0% means battery pack is not capable of holding any charge, 100% mea...";
CM_ SG_ 2566698750 SLIBatteryPackStateofCharge "SLI Battery Pack State of Charge: Indicates the remaining charge of the battery pack used for starting the engine, for lighting, and for ignition (SLI). 0% means no charge remaining, 100% means full capacity at the battery pack's current state of hea...";
CM_ SG_ 2566698750 SLICrnkngPrdtdMnmmBttrVltg "SLI Cranking Predicted Minimum Battery Voltage: Prediction of the minimum battery voltage used for starting the engine, for lighting, and for ignition (SLI) during a crank event, under present battery conditions.This parameter shall be used to report...";
CM_ BO_ 2566699006 "Hybrid System Status 2";
CM_ SG_ 2566699006 HrdBttrPkRmnngChrg "Hybrid Battery Pack Remaining Charge: Indicates the hybrid battery pack remaining charge. 0% means no charge remaining, 100% means full charge remaining.";
CM_ SG_ 2566699006 HrdSstmEngnStpStrtRmnngPrntg "Hybrid System Engine Stop-Start Remaining Percentage: Indicates the remaining percentage of engine stop-start operation allowed by the hybrid system.The calculation of the percentage is manufacturer specific.  It is an operational limitation, not a f...";
CM_ SG_ 2566699006 HrdPrplsnMdMxmmSpdSttng "Hybrid Propulsion Mode Maximum Speed Setting: The maximum speed setting as requested using Hybrid Propulsion Mode Requested Maximum Speed (SPN 9706).A value of FBh indicates that the sender supports this parameter, but there is currently no requested...";
CM_ SG_ 2566699006 HrdPrplsnMdRmnngDstn "Hybrid Propulsion Mode Remaining Distance: While in a Hybrid Propulsion Mode (see SPN 7889) other than Mode 1 - Stored Energy Source Sustaining, this reports a count down of the remaining distance until the mode is exited.  When the requested Hybrid ...";
CM_ BO_ 2566699262 "Aftertreatment 2 Service 2";
CM_ SG_ 2566699262 Atttt2DsPttFtTtNxtAtvRt "Aftertreatment 2 Diesel Particulate Filter Time to Next Active Regeneration: Indicates the time to the next active regeneration event of diesel particulate filter 2.";
CM_ SG_ 2566699262 Atttt2SCRSstTSLstSstCEvt "Aftertreatment 2 SCR System Time Since Last System Cleaning Event: Indicates the time since the last cleaning event of the SCR system in bank 2.";
CM_ BO_ 2566699518 "Aftertreatment 1 Service 2";
CM_ SG_ 2566699518 Atttt1DsPttFtTtNxtAtvRt "Aftertreatment 1 Diesel Particulate Filter Time to Next Active Regeneration: Indicates the time to the next active regeneration event of diesel particulate filter 1.";
CM_ SG_ 2566699518 Atttt1SCRSstTSLstSstCEvt "Aftertreatment 1 SCR System Time Since Last System Cleaning Event: Indicates the time since the last cleaning event of the SCR system in bank 1.";
CM_ BO_ 2566699774 "Aftertreatment 2 SCR Electronic Control Module Information";
CM_ SG_ 2566699774 Atttt2DsExstFdCtMd1PwSpp1 "Aftertreatment 2 Diesel Exhaust Fluid Control Module 1 Power Supply 1: State signal which indicates when the DEF control module 1 power supply of aftertreatment 2 is being driven. On means the ECU is powering the aftertreatment 2 DEF control module 1...";
CM_ SG_ 2566699774 Atttt2DsExstFdCtMd1PwSpp2 "Aftertreatment 2 Diesel Exhaust Fluid Control Module 1 Power Supply 2: State signal which indicates when the DEF control module 1 power supply 2 of aftertreatment 2 is being driven. On means the ECU is powering the aftertreatment 2 DEF control module...";
CM_ SG_ 2566699774 Atttt2DsExstFdCtMd1RCt "Aftertreatment 2 Diesel Exhaust Fluid Control Module 1 Relay Control: State signal which indicates when the DEF control module 1 relay of aftertreatment 2 is being energized. On means the ECU is powering the Aftertreatment 2 DEF dosing unit relay. No...";
CM_ SG_ 2566699774 Atttt2DsExstFdCtMd2PwSpp1 "Aftertreatment 2 Diesel Exhaust Fluid Control Module 2 Power Supply 1: State signal which indicates when the DEF control module 2 power supply of aftertreatment 2 is being driven. On means the ECU is powering the aftertreatment 2 DEF control module p...";
CM_ SG_ 2566699774 Atttt2DsExstFdCtMd2PwSpp2 "Aftertreatment 2 Diesel Exhaust Fluid Control Module 2 Power Supply 2: State signal which indicates when the DEF control module 2 power supply 2 of aftertreatment 2 is being driven. On means the ECU is powering the aftertreatment 2 DEF control module...";
CM_ SG_ 2566699774 Atttt2DsExstFdCtMd2RCt "Aftertreatment 2 Diesel Exhaust Fluid Control Module 2 Relay Control: State signal which indicates when the DEF control module 2 relay of aftertreatment 2 is being energized. On means the ECU is powering the Aftertreatment 2 DEF dosing unit relay. No...";
CM_ SG_ 2566699774 Atttt2DsExstFdCtMdCtB "Aftertreatment 2 Diesel Exhaust Fluid Control Module Circuit Breaker: The status of the circuit breaker that is used to power the Diesel Exhaust Fluid control module.00b = Off01b = On10b = Error11b = Not available";
CM_ BO_ 2566700030 "Aftertreatment 1 SCR Electronic Control Module Information";
CM_ SG_ 2566700030 Atttt1DsExstFdCtMd1PwSpp1 "Aftertreatment 1 Diesel Exhaust Fluid Control Module 1 Power Supply 1: State signal which indicates when the DEF control module power supply of aftertreatment 1 is being driven. On means the ECU is powering the aftertreatment 1 DEF control module pow...";
CM_ SG_ 2566700030 Atttt1DsExstFdCtMd1PwSpp2 "Aftertreatment 1 Diesel Exhaust Fluid Control Module 1 Power Supply 2: State signal which indicates when the DEF control module 1 power supply 2 of aftertreatment 1 is being driven. On means the ECU is powering the aftertreatment 1 DEF control module...";
CM_ SG_ 2566700030 Atttt1DsExstFdCtMd1RCt "Aftertreatment 1 Diesel Exhaust Fluid Control Module 1 Relay Control: State signal which indicates when the DEF control module relay of aftertreatment 1 is being energized. On means the ECU is powering the Aftertreatment 1 DEF dosing unit relay. Note...";
CM_ SG_ 2566700030 Atttt1DsExstFdCtMd2PwSpp1 "Aftertreatment 1 Diesel Exhaust Fluid Control Module 2 Power Supply 1: State signal which indicates when the DEF control module 2 power supply of aftertreatment 1 is being driven. On means the ECU is powering the aftertreatment 1 DEF control module p...";
CM_ SG_ 2566700030 Atttt1DsExstFdCtMd2PwSpp2 "Aftertreatment 1 Diesel Exhaust Fluid Control Module 2 Power Supply 2: State signal which indicates when the DEF control module 2 power supply 2 of aftertreatment 1 is being driven. On means the ECU is powering the aftertreatment 1 DEF control module...";
CM_ SG_ 2566700030 Atttt1DsExstFdCtMd2RCt "Aftertreatment 1 Diesel Exhaust Fluid Control Module 2 Relay Control: State signal which indicates when the DEF control module 2 relay of aftertreatment 1 is being energized. On means the ECU is powering the Aftertreatment 1 DEF dosing unit relay. No...";
CM_ SG_ 2566700030 Atttt1DsExstFdCtMdCtB "Aftertreatment 1 Diesel Exhaust Fluid Control Module Circuit Breaker: The status of the circuit breaker that is used to power the diesel exhaust control module.00b = off01b = on10b = error11b = not available";
CM_ BO_ 2566700286 "Aftertreatment 2 SCR Service Information 2";
CM_ SG_ 2566700286 Aftrtrtmnt2TtlDslExhstFldUsd "Aftertreatment 2 Total Diesel Exhaust Fluid Used: Total amount of DEF used by aftertreatment device 2 over the lifetime of the device.";
CM_ BO_ 2566700542 "Aftertreatment 1 SCR Service Information 2";
CM_ SG_ 2566700542 Aftrtrtmnt1TtlDslExhstFldUsd "Aftertreatment 1 Total Diesel Exhaust Fluid Used: Total amount of DEF used by aftertreatment device 1 over the lifetime of the device.";
CM_ SG_ 2566700542 AftrtrtmntTrpDslExhstFld "Aftertreatment Trip Diesel Exhaust Fluid: DEF consumed during all or part of a journey.";
CM_ BO_ 2566701566 "Transmission Fluids 3";
CM_ SG_ 2566701566 TransmissionClutch2Pressure "Transmission Clutch 2 Pressure: Gage pressure of hydraulic actuation fluid for a second transmission clutch. In dual input clutch applications, this refers to the second input clutch.";
CM_ SG_ 2566701566 TrnsmssnOlTrnsmssnClrOtltTmprtr "Transmission Oil Transmission Cooler Outlet Temperature: Temperature of transmission lubricant after it exits from the transmission cooler.";
CM_ BO_ 2566701822 "Hybrid System Status 1";
CM_ SG_ 2566701822 ExtrnlEnrgSrCnntnStts "External Energy Source Connection Status : External Energy Source Connection Status provides feedback to the External Energy Source Connection Demand (SPN 7890) if this SP is used to control the external energy source(s).  If SPN 7890 is not availabl...";
CM_ SG_ 2566701822 HrdPrplsnMdTrnstnStts "Hybrid Propulsion Mode Transition Status : Hybrid Propulsion Mode Transition Status is sent by the Hybrid System controller to indicate the reason for a mode transition occurring or being denied.  This parameter provides confirmation of any mode tran...";
CM_ SG_ 2566701822 HrdSstmEltrAltrntrIndtr "Hybrid System Electric Alternator Indicator: Signal from the hybrid system indicating that the electric alternator is failed or needs servicing.  The alternator Indicator (e.g. dash lamp) is to be activated.00b = Alternator Indicator is off01b = Alte...";
CM_ SG_ 2566701822 HrdSstmHghVltgExpsrIndtr "Hybrid System High Voltage Exposure Indicator: This signal indicates the condition and state of the the hybrid system or electric vehicle system high voltage exposure detection system (e.g. High Voltage Interlock Loop [HVIL]). The high voltage exposu...";
CM_ SG_ 2566701822 HrdSstmIntlztnIndtr "Hybrid System Initialization Indicator: Signal indicating when the hybrid system or electric vehicle system is initialized and ready to start the engine or other power source (e.g. fuel cell). The intent is that this would drive an indicator for the ...";
CM_ SG_ 2566701822 HrdSstmMtrOvrspdAdlAlrm "Hybrid System Motor Overspeed Audible Alarm: Signal from the hybrid system indicating that the overspeed audible alarm should be activated.00b = Motor Overspeed Audible Alarm is off01b = Motor Overspeed Audible Alarm is on10b = Error11b = Not Availab...";
CM_ SG_ 2566701822 HrdSstmMtrOvrspdIndtr "Hybrid System Motor Overspeed Indicator: Signal from the hybrid system indicating that the hybrid system motor is exceeding maximum speed limit.00b = Hybrid System Motor Overspeed Indicator is off01b = Hybrid System Motor Overspeed Indicator is on co...";
CM_ SG_ 2566701822 HrdSstmPrplsnDslStts "Hybrid System Propulsion Disable Status: Indicates if the hybrid system is in a state where propulsion is not available. This may be due to Hybrid System Propulsion Disable Request (SPN 7558), Hybrid System Propulsion Disable Switch (SPN 7554), or Hy...";
CM_ SG_ 2566701822 HrdSstmRgnrtvBrkngIndtr "Hybrid System Regenerative Braking Indicator: Signal from the hybrid system indicating when regenerative braking is active.00b = Regenerative braking is inactive, but not disabled01b = Regenerative braking is active10b = Regenerative braking is disab...";
CM_ SG_ 2566701822 HybridPropulsionModeStatus "Hybrid Propulsion Mode Status : Hybrid Propulsion Mode Status is the current Hybrid System Controller propulsion mode.  This parameter would typically echo the Hybrid Propulsion Mode Request (SPN 7889) assuming the request was honored and the Hybrid ...";
CM_ SG_ 2566701822 HybridSystemEngineAssistStatus "Hybrid System Engine Assist Status: Provides the engine an indication of when the hybrid system is not mechanically assisting rotation (i.e. not motoring) the engine. When this parameter is in state 00b, the engine can perform operations while free o...";
CM_ SG_ 2566701822 HybridSystemOBDRelatedDTCStatus "Hybrid System OBD Related DTC Status: Signal from hybrid system indicating the status of OBD related DTCs00b = Hybrid System does not have an active OBD related DTC01b = Hybrid System has an active OBD related DTC10b = SAE Reserved11b = Not available...";
CM_ SG_ 2566701822 HybridSystemOverheatIndicator "Hybrid System Overheat Indicator: Signal from a hybrid system indicating that at least one of its monitored temperatures is above normal acceptable limits, and as a result, hybrid system operation may be altered or restricted. The indicator is typica...";
CM_ SG_ 2566701822 HybridSystemServiceIndicator "Hybrid System Service Indicator: Signal from the hybrid system indicating that the hybrid system or one of its components requires servicing (e.g. oil change, coolant change).00b = Hybrid Service Indicator is off01b = Hybrid Service Indicator is on c...";
CM_ SG_ 2566701822 HybridSystemStopIndicator "Hybrid System Stop Indicator: Signal from a hybrid system indicating that some aspect of its operation is not functioning correctly, and as a result, the vehicle must be stopped. The indicator is typically a lamp. Distinctions in meaning between the ...";
CM_ SG_ 2566701822 HybridSystemWarningIndicator "Hybrid System Warning Indicator: Signal from a hybrid system indicating that some aspect of its operation is not functioning correctly, and as a result, hybrid system operation may be altered or restricted. The indicator is typically a lamp. Distinct...";
CM_ SG_ 2566701822 PropulsionSystemActive "Propulsion System Active: Indicates when the hybrid system or electric vehicle system is ready to provide or is actively providing propulsion as defined in ARB regulation 13CCR1971.1, which includes the amendments up to the Board hearing date of Augu...";
CM_ SG_ 2566701822 StoredEnergySourceLevel "Stored Energy Source Level: Stored Energy Source Level indicates the current operating stored energy source capacity.In a Diesel-Electric Hybrid, this is the current percentage of the HVES useable capacity.  When the state of charge is below the mini...";
CM_ SG_ 2566701822 StrdEnrgSrInrsngMdAllwd "Stored Energy Source Increasing Mode Allowed : Stored Energy Source Increasing Mode Allowed is sent by the Hybrid System controller to indicate when the Stored Energy Source Increasing Mode is available for use and/or allowed to be used.In a Diesel-E...";
CM_ SG_ 2566701822 StrdEnrgSrOnlMdAllwd "Stored Energy Source Only Mode Allowed: Stored Energy Source Only Mode Allowed is sent by the Hybrid System controller to indicate when Stored Energy Source Only Mode is available for use and/or allowed to be used.In a Diesel-Electric Hybrid, Stored ...";
CM_ BO_ 2566702078 "Fuel Information 4 (Gaseous)";
CM_ SG_ 2566702078 SupplyGasMethanePercentage "Supply Gas Methane Percentage: The percentage of methane in the gas supplied to the engine.";
CM_ BO_ 2566702334 "Aftertreatment 2 SCR Exhaust Gas Temperature 2";
CM_ SG_ 2566702334 Aftrtrtmnt2SCRIntrmdtTmprtr "Aftertreatment 2 SCR Intermediate Temperature: Temperature of engine combustion byproducts at an intermediate point in the SCR component in exhaust bank 2.";
CM_ SG_ 2566702334 Atttt2SCRItdtTptPFMI "Aftertreatment 2 SCR Intermediate Temperature Preliminary FMI: Used to identify the applicable J1939-73 FMI detected in the aftertreatment SCR intermediate temperature sensor by the manufacturer’s sensor control software in exhaust bank 2.  In the ca...";
CM_ BO_ 2566702590 "Aftertreatment 1 SCR Exhaust Gas Temperature 2";
CM_ SG_ 2566702590 Aftrtrtmnt1SCRIntrmdtTmprtr "Aftertreatment 1 SCR Intermediate Temperature: Temperature of engine combustion byproducts at an intermediate point in the SCR component in exhaust bank 1.";
CM_ SG_ 2566702590 Atttt1SCRItdtTptPFMI "Aftertreatment 1 SCR Intermediate Temperature Preliminary FMI: Used to identify the applicable J1939-73 FMI detected in the aftertreatment SCR intermediate temperature sensor by the manufacturer’s sensor control software in exhaust bank 1.  In the ca...";
CM_ BO_ 2566703358 "Electronic Engine Controller 13";
CM_ SG_ 2566703358 EngineDualFuelMode "Engine Dual Fuel Mode: Actual dual fuel mode, off or on.00b = Actual dual fuel mode off01b = Actual dual fuel mode on10b = Reserved11b = Not available";
CM_ SG_ 2566703358 EngineFuelingInhibitAllowed "Engine Fueling Inhibit Allowed: This parameter is broadcast by the engine control system, and indicates to other devices on the network whether or not it will respond to requests to inhibit engine fueling via SPN 5793 Desired Engine Fueling State. Wi...";
CM_ SG_ 2566703358 EngnFlngDsrdRqstCnt "Engine Fueling Desired Request Count: A signal issued by the engine control system indicating the number of devices from which the engine control system has received a fueling desired request. Requests included in this count are either from an extern...";
CM_ SG_ 2566703358 EngnFlngInhtPrvntdRsn "Engine Fueling Inhibit Prevented Reason: If Engine Fueling Inhibit Allowed (SPN 5795) indicates that the engine will inhibit fueling, then this parameter and Engine Fueling Inhibit Prevented Reason Extension (SPN 8145) will indicate the reason.If SPN...";
CM_ SG_ 2566703358 EngnFlngInhtPrvntdRsnExtnsn "Engine Fueling Inhibit Prevented Reason Extension: If Engine Fueling Inhibit Allowed (SPN 5795) indicates that the engine will inhibit fueling, then this parameter indicate the reason.  If more than one reason exists at the same time, then it is up t...";
CM_ SG_ 2566703358 EngnFlngInhtRqstCnt "Engine Fueling Inhibit Request Count: A signal issued by the engine control system indicating the number of devices from which the engine control system has received a fueling not desired request. Requests included in this count are either from an ex...";
CM_ SG_ 2566703358 EngnGsSstttnFlPrntg "Engine Gas Substitution Fuel Percentage: Percentage of Gaseous fuel used. 0% means no Gaseous fuel used and 100% means completely gaseous fuel is used.Gas substitution is the process for a dual fuel engine system of substituting gas, e.g. natural gas...";
CM_ SG_ 2566703358 EngnPrttnDrtOvrrdStts "Engine Protection Derate Override Status: Status of overriding an engine protection derate.This is to temporarily override an engine protection derate due to coolant temperature, oil pressure etc... This is for applications such as fire, rescue, and mi...";
CM_ SG_ 2566703358 FeedbackEngineFuelingState "Feedback Engine Fueling State: This parameter provides feedback to the network that SPN 5793 Desired Engine Fueling State was honored. SPN 5795 Engine Fueling Inhibit Allowed indicates the engine's current ability to honor requests via SPN 5793 Desir...";
CM_ SG_ 2566703358 SrAddrssfCntrllngDvfrFlngStt "Source Address of Controlling Device for Fueling State: The J1939 source address of the device currently controlling the fueling state via SPN 5793.254 (FEh) is used to indicate that the Source Address of Controlling Device for Fueling State paramete...";
CM_ SG_ 2566703358 RemainingEngineMotoringTime "Remaining Engine Motoring Time: A nonzero value of this parameter indicates that the engine requires motoring.  It reflects the consecutive period of time the engine needs motoring (i.e. fueling equal to zero with engine spinning) to allow certain en...";
CM_ SG_ 2566703358 EnginePerformanceBiasLevel "Engine Performance Bias Level: This parameter reflects the actual engine performance bias level in use. For values between 0% and 50%, functionality is biased toward fuel economy, with values closer to 0% indicating more bias toward fuel economy.50% ...";
CM_ SG_ 2566703358 MinimumEngineMotoringSpeed "Minimum Engine Motoring Speed: Indicates the engine speed that needs to be equaled or exceeded while motoring (i.e. fueling equal to zero with engine spinning).   When Remaining Engine Motoring Time (See SPN 12857) is a valid value this speed must be...";
CM_ BO_ 2566703614 "Engine Fuel/Throttle Valve Information 2";
CM_ SG_ 2566703614 EngineFuelValve1Temperature "Engine Fuel Valve 1 Temperature: Temperature of the Engine Fuel Valve 1 drive circuitry. Temperature excursions may affect the torque output.";
CM_ SG_ 2566703614 EngineFuelValve2Temperature "Engine Fuel Valve 2 Temperature: Temperature of the Engine Fuel Valve 2 drive circuitry. Temperature excursions may affect the torque output.";
CM_ SG_ 2566703614 EngineThrottleValve1Position2 "Engine Throttle Valve 1 Position 2: The position of the valve used to regulate the supply of a fluid, usually air or fuel/air mixture, to an engine. This position is measured by a second sensor.";
CM_ SG_ 2566703614 EngineThrottleValve1Temperature "Engine Throttle Valve 1 Temperature: Temperature of the engine throttle valve 1 drive circuitry (SPN 51).  Temperature excursions may affect the torque output.";
CM_ SG_ 2566703614 EngineThrottleValve2Temperature "Engine Throttle Valve 2 Temperature: Temperature of the engine throttle valve 2 drive circuitry (SPN 3673).  Temperature excursions may affect the torque output.";
CM_ SG_ 2566703614 EngnFlRkFlSpplTmprtr "Engine Fuel Rack Fuel Supply Temperature: Temperature of fuel in the engine fuel rack.";
CM_ SG_ 2566703614 EngnTrhrgrWstgtAttr2Tmprtr "Engine Turbocharger Wastegate Actuator 2 Temperature: Temperature of the Engine Turbocharger Wastegate Actuator 2 drive circuitry.  Temperature excursions may affect the torque output.";
CM_ BO_ 2566703870 "Engine Exhaust Gas Recirculation 2 Actuator";
CM_ SG_ 2566703870 EExstGsRt2Att1TptStts "Engine Exhaust Gas Recirculation 2 Actuator 1 Temperature Status: Used to identify the status of the Engine Exhaust Gas Recirculation 2 Actuator 1 drive circuitry temperature.  Temperature excursions may affect the torque output.000b = High Most seve...";
CM_ SG_ 2566703870 EExstGsRt2Att2TptStts "Engine Exhaust Gas Recirculation 2 Actuator 2 Temperature Status: Used to identify the status of the Engine Exhaust Gas Recirculation 2 Actuator 2 drive circuitry temperature.  Temperature excursions may affect the torque output.000b = High Most seve...";
CM_ SG_ 2566703870 EngnExhstGsRrltn2Attr1DsrdPstn "Engine Exhaust Gas Recirculation 2 Actuator 1 Desired Position: The requested position of the Engine Exhaust Gas Recirculation 2 Actuator 1 by the engine ECU, where 0% represents fully closed and 100% represents fully open.This is the position that t...";
CM_ SG_ 2566703870 EngnExhstGsRrltn2Attr1OprtnStts "Engine Exhaust Gas Recirculation 2 Actuator 1 Operation Status: Used to identify the status of Exhaust Gas Recirculation 2 Actuator 10000b = Normal0001b = Alarm (fully operational but needs service)0010b = Alarm High Severity (functional but transien...";
CM_ SG_ 2566703870 EngnExhstGsRrltn2Attr1PrlmnrFMI "Engine Exhaust Gas Recirculation 2 Actuator 1 Preliminary FMI: Used to identify the applicable J1939-73 FMI detected in the Engine Exhaust Gas Recirculation 2 Actuator 1 by the manufacturer’s software.  When there are multiple failures, the most seve...";
CM_ SG_ 2566703870 EngnExhstGsRrltn2Attr1Tmprtr "Engine Exhaust Gas Recirculation 2 Actuator 1 Temperature: Temperature of the Engine Exhaust Gas Recirculation 2 Actuator 1 drive circuitry.  Temperature excursions may affect the torque output.";
CM_ SG_ 2566703870 EngnExhstGsRrltn2Attr2DsrdPstn "Engine Exhaust Gas Recirculation 2 Actuator 2 Desired Position: The requested position of the Engine Exhaust Gas Recirculation 2 Actuator 2 by the engine ECU, where 0% represents fully closed and 100% represents fully open.This is the position that t...";
CM_ SG_ 2566703870 EngnExhstGsRrltn2Attr2OprtnStts "Engine Exhaust Gas Recirculation 2 Actuator 2 Operation Status: Used to identify the status of Exhaust Gas Recirculation 2 Actuator 20000b = Normal0001b = Alarm (fully operational but needs service)0010b = Alarm High Severity (functional but transien...";
CM_ SG_ 2566703870 EngnExhstGsRrltn2Attr2PrlmnrFMI "Engine Exhaust Gas Recirculation 2 Actuator 2 Preliminary FMI: Used to identify the applicable J1939-73 FMI detected in the Engine Exhaust Gas Recirculation 2 Actuator 2 by the manufacturer’s software. When there are multiple failures, the most sever...";
CM_ SG_ 2566703870 EngnExhstGsRrltn2Attr2Tmprtr "Engine Exhaust Gas Recirculation 2 Actuator 2 Temperature: Temperature of the Engine Exhaust Gas Recirculation 2 Actuator 2 drive circuitry.  Temperature excursions may affect the torque output.";
CM_ BO_ 2566704126 "Engine Exhaust Gas Recirculation 1 Actuator";
CM_ SG_ 2566704126 EExstGsRt1Att1TptStts "Engine Exhaust Gas Recirculation 1 Actuator 1 Temperature Status: Used to identify the status of the Engine Exhaust Gas Recirculation 1 Actuator 1 drive circuitry temperature.  Temperature excursions may affect the torque output.000b = High Most seve...";
CM_ SG_ 2566704126 EExstGsRt1Att2TptStts "Engine Exhaust Gas Recirculation 1 Actuator 2 Temperature Status: Used to identify the status of the Engine Exhaust Gas Recirculation 1 Actuator 2 drive circuitry temperature.  Temperature excursions may affect the torque output.000b = High Most seve...";
CM_ SG_ 2566704126 EngnExhstGsRrltn1Attr1DsrdPstn "Engine Exhaust Gas Recirculation 1 Actuator 1 Desired Position: The requested position of the Engine Exhaust Gas Recirculation 1 Actuator 1 by the engine ECU, where 0% represents fully closed and 100% represents fully open.This is the position that t...";
CM_ SG_ 2566704126 EngnExhstGsRrltn1Attr1OprtnStts "Engine Exhaust Gas Recirculation 1 Actuator 1 Operation Status: Used to identify the status of Exhaust Gas Recirculation 1 Actuator 10000b = Normal0001b = Alarm (fully operational but needs service)0010b = Alarm High Severity (functional but transien...";
CM_ SG_ 2566704126 EngnExhstGsRrltn1Attr1PrlmnrFMI "Engine Exhaust Gas Recirculation 1 Actuator 1 Preliminary FMI: Used to identify the applicable J1939-73 FMI detected in the Engine Exhaust Gas Recirculation 1 Actuator 1 by the manufacturer’s software.  When there are multiple failures, the most seve...";
CM_ SG_ 2566704126 EngnExhstGsRrltn1Attr1Tmprtr "Engine Exhaust Gas Recirculation 1 Actuator 1 Temperature: Temperature of the Engine Exhaust Gas Recirculation 1 Actuator 1 drive circuitry.  Temperature excursions may affect the torque output.";
CM_ SG_ 2566704126 EngnExhstGsRrltn1Attr2DsrdPstn "Engine Exhaust Gas Recirculation 1 Actuator 2 Desired Position: The requested position of the Engine Exhaust Gas Recirculation 1 Actuator 2 by the engine ECU, where 0% represents fully closed and 100% represents fully open.This is the position that t...";
CM_ SG_ 2566704126 EngnExhstGsRrltn1Attr2OprtnStts "Engine Exhaust Gas Recirculation 1 Actuator 2 Operation Status: Used to identify the status of Exhaust Gas Recirculation 1 Actuator 20000b = Normal0001b = Alarm (fully operational but needs service)0010b = Alarm High Severity (functional but transien...";
CM_ SG_ 2566704126 EngnExhstGsRrltn1Attr2PrlmnrFMI "Engine Exhaust Gas Recirculation 1 Actuator 2 Preliminary FMI: Used to identify the applicable J1939-73 FMI detected in the Engine Exhaust Gas Recirculation 1 Actuator 2 by the manufacturer’s software. When there are multiple failures, the most sever...";
CM_ SG_ 2566704126 EngnExhstGsRrltn1Attr2Tmprtr "Engine Exhaust Gas Recirculation 1 Actuator 2 Temperature: Temperature of the Engine Exhaust Gas Recirculation 1 Actuator 2 drive circuitry.  Temperature excursions may affect the torque output.";
CM_ BO_ 2566704382 "Electronic Engine Controller 12";
CM_ SG_ 2566704382 Aftrtrtmnt1Otlt1GsSnsrPwrSppl "Aftertreatment 1 Outlet 1 Gas Sensor Power Supply: State signal which indicates when the Aftertreatment 1 Outlet 1 Gas Sensor driver output is being driven. On means the ECU is powering the Aftertreatment 1 Outlet 1 Gas Sensor. Note that the ECU is e...";
CM_ SG_ 2566704382 Aftrtrtmnt1Otlt2GsSnsrPwrSppl "Aftertreatment 1 Outlet 2 Gas Sensor Power Supply: State signal which indicates when the Aftertreatment 1 Outlet 2 Gas Sensor driver output is being driven.00b = Off01b = On: The ECU is powering the Aftertreatment 1 Outlet 2 Gas Sensor10b = Error11b ...";
CM_ SG_ 2566704382 Aftrtrtmnt2Otlt1GsSnsrPwrSppl "Aftertreatment 2 Outlet 1 Gas Sensor Power Supply: State signal which indicates when the Aftertreatment 2 Outlet 1 Gas Sensor driver output is being driven.  On means the ECU is powering the Aftertreatment 2 Outlet 1 Gas Sensor.  Note that the ECU is...";
CM_ SG_ 2566704382 EngnExhst1GsSnsr1PwrSppl "Engine Exhaust 1 Gas Sensor 1 Power Supply: State signal which indicates when the Engine Exhaust 1 Intake 1 Gas Sensor driver output is being driven.  On means the ECU is powering the Engine Exhaust 1 Intake 1 Gas Sensor.  Note that the ECU is extern...";
CM_ SG_ 2566704382 EngnExhst2GsSnsr1PwrSppl "Engine Exhaust 2 Gas Sensor 1 Power Supply: State signal which indicates when the Engine Exhaust 2 Intake 1 Gas Sensor driver output is being driven.  On means the ECU is powering the Engine Exhaust 2 Intake 1 Gas Sensor.  Note that the ECU is extern...";
CM_ SG_ 2566704382 EngnExhst1GsSnsr2PwrSppl "Engine Exhaust 1 Gas Sensor 2 Power Supply: State signal which indicates when the Engine Exhaust 1 Gas Sensor 2 driver output is being driven.  This sensor is located at the intake of the aftertreatment system if an aftertreatment system exists.00b =...";
CM_ BO_ 2566705150 "NOx Sensor Self-Diagnosis Request";
CM_ SG_ 2566705150 Atttt1OttNOxSsSdssT "Aftertreatment 1 Outlet NOx Sensor Self-diagnosis Trigger: Signal to trigger the self-diagnosis of NOx sensor ATO1 (Aftertreatment Outlet Bank 1)0000b = Diagnostic mode disabled0001b = NOx Sensor ATO1 Self-diagnosis Request at Lambda=1.00010b = NOx S...";
CM_ SG_ 2566705150 Atttt2OttNOxSsSdssT "Aftertreatment 2 Outlet NOx Sensor Self-diagnosis Trigger: Signal to trigger the self-diagnosis of NOx sensor ATO2 (Aftertreatment Outlet Bank 2)0000b = Diagnostic mode disabled0001b = NOx Sensor ATO2 Self-diagnosis Request at Lambda=1.00010b = NOx S...";
CM_ SG_ 2566705150 EngnExhst1NOxSnsrSlfdgnssTrggr "Engine Exhaust 1 NOx Sensor Self-diagnosis Trigger: Signal to trigger the self-diagnosis of NOx sensor Engine Exhaust Bank 1 (EEB1).  This sensor is located at the intake of the aftertreatment system if an aftertreatment system exists.0000b = Diagnos...";
CM_ SG_ 2566705150 EngnExhst2NOxSnsrSlfdgnssTrggr "Engine Exhaust 2 NOx Sensor Self-diagnosis Trigger: Signal to trigger the self-diagnosis of NOx sensor Engine Exhaust Bank 2 (EEB2).  This sensor is located at the intake of the aftertreatment system if an aftertreatment system exists.0000b = Diagnos...";
CM_ BO_ 2566705406 "Engine Particulate Sensor Information";
CM_ SG_ 2566705406 Aftrtrtmnt1PrtltSnsr "Aftertreatment 1 Particulate Sensor: The particulate sensor measures the mass concentration of particulate matter in the exhaust downstream of the DPF in exhaust bank 1.";
CM_ SG_ 2566705406 Aftrtrtmnt1PrtltSnsrCrrnt "Aftertreatment 1 Particulate Sensor Current: Raw aftertreatment 1 PM sensor electrical current reading.";
CM_ SG_ 2566705406 Aftrtrtmnt2PrtltSnsr "Aftertreatment 2 Particulate Sensor: The particulate sensor measures the mass concentration of particulate matter in the exhaust downstream of the DPF in exhaust bank 2.";
CM_ BO_ 2566706686 "Aftertreatment 1 Diesel Exhaust Fluid Pump 1 Information";
CM_ SG_ 2566706686 Aftrtrtmnt1DslExhstFldPmpHtr "Aftertreatment 1 Diesel Exhaust Fluid Pump Heater: Percentage of heating applied to the aftertreatment 1 diesel exhaust fluid pump heater. A value of 0% means no heating applied, a value of 100% means full heating applied. The diesel exhaust fluid pu...";
CM_ SG_ 2566706686 Atttt1DsExstFdDsUt1HtR "Aftertreatment 1 Diesel Exhaust Fluid Dosing Unit 1 Heater Relay: The status of the relay that controls Aftertreatment 1 diesel exhaust fluid dosing Unit 1 Heater.00b = Off01b = On10b = Error11b = Not available";
CM_ SG_ 2566706686 Atttt1DsExstFdPp2MtSpd "Aftertreatment 1 Diesel Exhaust Fluid Pump 2 Motor Speed: Rotational speed of the motor driving the second pump for the diesel exhaust fluid used in aftertreatment system 1 (exhaust bank 1).";
CM_ SG_ 2566706686 Atttt1DsExstFdPpPwSpp "Aftertreatment 1 Diesel Exhaust Fluid Pump Power Supply: State signal which indicates when the aftertreatment 1 Diesel Exhaust Fluid (DEF) pump power output is being driven.  On means the ECU is powering the aftertreatment 1 DEF pump power output.  N...";
CM_ SG_ 2566706686 AttttDsExstFdTsPpPR "Aftertreatment Diesel Exhaust Fluid Transfer Pump Purge Relay: The state of the relay that controls the purging of the pump used to transfer diesel exhaust fluid from the bulk storage tank to a local tank.00b = Off  (relay not energized)01b = On  (re...";
CM_ BO_ 2566706942 "Aftertreatment 1 Diesel Particulate Filter 2 Soot 5";
CM_ SG_ 2566706942 Atttt1DsPttFt2StSsAssFq3 "Aftertreatment 1 Diesel Particulate Filter 2 Soot Sensor Analysis Frequency 3: The analysis frequency associated with the frequency 3 soot signal for the diesel particulate filter 2 soot sensor.  See SPN 5646.";
CM_ SG_ 2566706942 Atttt1DsPttFt2StSsAssFq4 "Aftertreatment 1 Diesel Particulate Filter 2 Soot Sensor Analysis Frequency 4: The analysis frequency associated with the frequency 4 soot signal for the diesel particulate filter 2 soot sensor.  See SPN 5647.";
CM_ SG_ 2566706942 Atttt1DsPttFt2StSsFq3StS "Aftertreatment 1 Diesel Particulate Filter 2 Soot Sensor Frequency 3 Soot Signal: The soot signal attenuation measurement for analysis frequency 3 for the diesel particulate filter 2 soot sensor.  See SPN 5646.";
CM_ SG_ 2566706942 Atttt1DsPttFt2StSsFq4StS "Aftertreatment 1 Diesel Particulate Filter 2 Soot Sensor Frequency 4 Soot Signal: The soot signal attenuation measurement for analysis frequency 4 for the diesel particulate filter 2 soot sensor.  See SPN 5647.";
CM_ BO_ 2566707198 "Aftertreatment 1 Diesel Particulate Filter 2 Soot 4";
CM_ SG_ 2566707198 Atttt1DsPttFt2StSsAssFq1 "Aftertreatment 1 Diesel Particulate Filter 2 Soot Sensor Analysis Frequency 1: The analysis frequency associated with the frequency 1 soot signal for the diesel particulate filter 2 soot sensor.  See SPN 5644.";
CM_ SG_ 2566707198 Atttt1DsPttFt2StSsAssFq2 "Aftertreatment 1 Diesel Particulate Filter 2 Soot Sensor Analysis Frequency 2: The analysis frequency associated with the frequency 2 soot signal for the diesel particulate filter 2 soot sensor.  See SPN 5645.";
CM_ SG_ 2566707198 Atttt1DsPttFt2StSsFq1StS "Aftertreatment 1 Diesel Particulate Filter 2 Soot Sensor Frequency 1 Soot Signal: The soot signal attenuation measurement for analysis frequency 1 for the diesel particulate filter 2 soot sensor.  See SPN 5644.";
CM_ SG_ 2566707198 Atttt1DsPttFt2StSsFq2StS "Aftertreatment 1 Diesel Particulate Filter 2 Soot Sensor Frequency 2 Soot Signal: The soot signal attenuation measurement for analysis frequency 2 for the diesel particulate filter 2 soot sensor.  See SPN 5645.";
CM_ BO_ 2566707454 "Aftertreatment 1 Diesel Particulate Filter 2 Soot 3";
CM_ SG_ 2566707454 Atttt1DsPttFt2StSsAssRqstFq1 "Aftertreatment 1 Diesel Particulate Filter 2 Soot Sensor Analysis Request Frequency 1: First requested analysis frequency for the diesel particulate filter 2 soot sensor.";
CM_ SG_ 2566707454 Atttt1DsPttFt2StSsAssRqstFq2 "Aftertreatment 1 Diesel Particulate Filter 2 Soot Sensor Analysis Request Frequency 2: Second requested analysis frequency for the diesel particulate filter 2 soot sensor.";
CM_ SG_ 2566707454 Atttt1DsPttFt2StSsAssRqstFq3 "Aftertreatment 1 Diesel Particulate Filter 2 Soot Sensor Analysis Request Frequency 3: Third requested analysis frequency for the diesel particulate filter 2 soot sensor.";
CM_ SG_ 2566707454 Atttt1DsPttFt2StSsAssRqstFq4 "Aftertreatment 1 Diesel Particulate Filter 2 Soot Sensor Analysis Request Frequency 4: Fourth requested analysis frequency for the diesel particulate filter 2 soot sensor.";
CM_ BO_ 2566707710 "Aftertreatment 1 Diesel Particulate Filter 1 Soot 5";
CM_ SG_ 2566707710 Atttt1DsPttFt1StSsAssFq3 "Aftertreatment 1 Diesel Particulate Filter 1 Soot Sensor Analysis Frequency 3: The analysis frequency associated with the frequency 3 soot signal for the diesel particulate filter 1 soot sensor.  See SPN 5634.";
CM_ SG_ 2566707710 Atttt1DsPttFt1StSsAssFq4 "Aftertreatment 1 Diesel Particulate Filter 1 Soot Sensor Analysis Frequency 4: The analysis frequency associated with the frequency 4 soot signal for the diesel particulate filter 1 soot sensor.  See SPN 5635.";
CM_ SG_ 2566707710 Atttt1DsPttFt1StSsFq3StS "Aftertreatment 1 Diesel Particulate Filter 1 Soot Sensor Frequency 3 Soot Signal: The soot signal attenuation measurement for analysis frequency 3 for the diesel particulate filter 1 soot sensor.  See SPN 5634.";
CM_ SG_ 2566707710 Atttt1DsPttFt1StSsFq4StS "Aftertreatment 1 Diesel Particulate Filter 1 Soot Sensor Frequency 4 Soot Signal: The soot signal attenuation measurement for analysis frequency 4 for the diesel particulate filter 1 soot sensor.  See SPN 5635.";
CM_ BO_ 2566707966 "Aftertreatment 1 Diesel Particulate Filter 1 Soot 4";
CM_ SG_ 2566707966 Atttt1DsPttFt1StSsAssFq1 "Aftertreatment 1 Diesel Particulate Filter 1 Soot Sensor Analysis Frequency 1: The analysis frequency associated with the frequency 1 soot signal for the diesel particulate filter 1 soot sensor.  See SPN 5632.";
CM_ SG_ 2566707966 Atttt1DsPttFt1StSsAssFq2 "Aftertreatment 1 Diesel Particulate Filter 1 Soot Sensor Analysis Frequency 2: The analysis frequency associated with the frequency 2 soot signal for the diesel particulate filter 1 soot sensor.  See SPN 5633.";
CM_ SG_ 2566707966 Atttt1DsPttFt1StSsFq1StS "Aftertreatment 1 Diesel Particulate Filter 1 Soot Sensor Frequency 1 Soot Signal: The soot signal attenuation measurement for analysis frequency 1 for the diesel particulate filter 1 soot sensor.  See SPN 5632.";
CM_ SG_ 2566707966 Atttt1DsPttFt1StSsFq2StS "Aftertreatment 1 Diesel Particulate Filter 1 Soot Sensor Frequency 2 Soot Signal: The soot signal attenuation measurement for analysis frequency 2 for the diesel particulate filter 1 soot sensor.  See SPN 5633.";
CM_ BO_ 2566708222 "Aftertreatment 1 Diesel Particulate Filter 1 Soot 3";
CM_ SG_ 2566708222 Atttt1DsPttFt1StSsAssRqstFq1 "Aftertreatment 1 Diesel Particulate Filter 1 Soot Sensor Analysis Request Frequency 1: First requested analysis frequency for the diesel particulate filter 1 soot sensor.";
CM_ SG_ 2566708222 Atttt1DsPttFt1StSsAssRqstFq2 "Aftertreatment 1 Diesel Particulate Filter 1 Soot Sensor Analysis Request Frequency 2: Second requested analysis frequency for the diesel particulate filter 1 soot sensor.";
CM_ SG_ 2566708222 Atttt1DsPttFt1StSsAssRqstFq3 "Aftertreatment 1 Diesel Particulate Filter 1 Soot Sensor Analysis Request Frequency 3: Third requested analysis frequency for the diesel particulate filter 1 soot sensor.";
CM_ SG_ 2566708222 Atttt1DsPttFt1StSsAssRqstFq4 "Aftertreatment 1 Diesel Particulate Filter 1 Soot Sensor Analysis Request Frequency 4: Fourth requested analysis frequency for the diesel particulate filter 1 soot sensor.";
CM_ BO_ 2566708478 "Cruise Control / Vehicle Speed 3";
CM_ SG_ 2566708478 AdptvCrsCntrlRdnssStts "Adaptive Cruise Control Readiness Status: This parameter is used to indicate an application's state of readiness for responding to commands from an adaptive cruise control system controller.00b = Off -- Cruise Control System is not configured to acce...";
CM_ SG_ 2566708478 AEBSreadinessstate "AEBS readiness state: Advanced emergency braking systems (AEBS) will limit the engine torque via TSC1 during warning and braking phases. Therefore the engine controller gives a feedback to the AEBS if it is configured and able to obey these limitatio...";
CM_ SG_ 2566708478 CrsCntrlDrvrCnlltnStts "Cruise Control Driver Cancellation Status: State signal which indicates that the cruise control is cancelled by driver action.  Driver actions could include switch off, brake pedal activation, clutch pedal actuation, cancel switch, or other reasons d...";
CM_ SG_ 2566708478 CrsCntrlStSpdHghRsltn "Cruise Control Set Speed (High Resolution): Value of set (chosen) velocity of velocity control system. See SPN 86 for an alternate resolution.If an algorithm that can modify the cruise control set point exists in the system, such as Predictive Cruise...";
CM_ SG_ 2566708478 CruiseControlSpeed "Cruise Control Speed: This parameter is the vehicle speed that the cruise control algorithm is currently using as its cruise control set point.Cruise Control Speed (SPN 7319) will include the effects of other algorithms, such as Predictive Cruise Con...";
CM_ SG_ 2566708478 CruiseControlSystemCommandState "Cruise Control System Command State: Indicates the current state of the cruise control system due to the Cruise Control System Commands, which include Cruise Control Disable Command (SPN 5603), Cruise Control Resume Command (SPN 5604), Cruise Control...";
CM_ SG_ 2566708478 PrdtvCrsCntrlStSpdOffstStts "Predictive Cruise Control Set Speed Offset Status: This parameter indicates if the cruise control algorithm is currently adding the value in Predictive Cruise Control Set Speed Offset (SPN 7316) to the Cruise Control Set Speed (SPN 86 or SPN 6809) fo...";
CM_ SG_ 2566708478 SAddssCtDvDsCsCt "Source Address of Controlling Device for Disabling Cruise Control: The source address of the SAE J1939 device that is currently sending the Cruise Control Disable Command (SPN 5603).If there are multiple devices sending Cruise Control Disable Command...";
CM_ SG_ 2566708478 SAddssCtDvPsCsCt "Source Address of Controlling Device for Pausing Cruise Control: The source address of the SAE J1939 device that is currently sending the Cruise Control Pause Command (SPN 5605).If there are multiple devices sending Cruise Control Pause Command with ...";
CM_ BO_ 2566708734 "Aftertreatment 2 Air Control 3";
CM_ SG_ 2566708734 Aftrtrtmnt2SndrArAsltPrssr "Aftertreatment 2 Secondary Air Absolute Pressure: Absolute pressure of the secondary air for aftertreatment 2. Secondary air is air provided to the exhaust system (per SAE J2403).For gage pressure, see SPN 3838.";
CM_ BO_ 2566708990 "Aftertreatment 1 Air Control 3";
CM_ SG_ 2566708990 Aftrtrtmnt1SndrArAsltPrssr "Aftertreatment 1 Secondary Air Absolute Pressure: Absolute pressure of the secondary air for aftertreatment 1. Secondary air is air provided to the exhaust system (per SAE J2403).For gage pressure, see SPN 3837.";
CM_ SG_ 2566708990 OprtrIndmntOvrrdRnwlRqrd "Operator Inducement Override Renewal Required: Indicates the required operator inducement override renewal state.00b = Not Required01b = Required10b = Error11b = Not Available";
CM_ BO_ 2566709246 "Engine Fluid Level/Pressure 12";
CM_ SG_ 2566709246 EFSppPpItAstPssExtddR "Engine Fuel Supply Pump Intake Absolute Pressure (Extended Range): Absolute pressure of fuel at the fuel supply pump intake. See Figures SPN16_A & SPN16_B. See SPN 1381 for alternate resolution.Engine Fuel Supply Pump Intake Absolute Pressure (Extend...";
CM_ SG_ 2566709246 EngineFuelFilterDegradation "Engine Fuel Filter Degradation: The estimated percentage relative to the useful life of the engine fuel filter. This is not a calculation of the physical restriction of the filter.  0% is typical of a new filter.  100% is typical of an end of life fi...";
CM_ SG_ 2566709246 EngineFuelReturnPressure "Engine Fuel Return Pressure: Used to read fuel (or gas) pressure passing through the return line.";
CM_ SG_ 2566709246 EngnFlDlvrAsltPrssr "Engine Fuel Delivery Absolute Pressure: Absolute pressure of fuel in system as delivered from supply pump to the injection pump.  See also SPN 94 for Fuel Delivery Pressure (Gage).";
CM_ SG_ 2566709246 EngnFltrdFlDlvrAsltPrssr "Engine Filtered Fuel Delivery Absolute Pressure: Absolute pressure of fuel in system as delivered from supply pump to the injection pump after the pressure side fuel filter.  See SPN 5579 for gage pressure of fuel in system after the pressure side fu...";
CM_ SG_ 2566709246 EngnFltrdFlDlvrPrssr "Engine Filtered Fuel Delivery Pressure: Gage pressure of fuel in system as delivered from supply pump to the injection pump after the pressure side fuel filter.  See SPN 5580 for absolute pressure of fuel in system after the pressure side fuel filter...";
CM_ SG_ 2566709246 EngnThrttlVlv2DffrntlPrssr "Engine Throttle Valve 2 Differential Pressure: The differential pressure between the intake and outlet of the throttle valve 2 (SPN 3673). The differential pressure is measured from the intake with respect to the outlet of the throttle valve.";
CM_ BO_ 2566709502 "Diesel Particulate Filter Control 2";
CM_ SG_ 2566709502 Aftertreatment1FuelMassRate "Aftertreatment 1 Fuel Mass Rate: Mass rate of total fuel being delivered to aftertreatment 1 for DPF regeneration.";
CM_ SG_ 2566709502 Aftertreatment2FuelMassRate "Aftertreatment 2 Fuel Mass Rate: Mass rate of total fuel being delivered to Atertreatment 2 for DPF regeneration.";
CM_ SG_ 2566709502 Atttt1DsPttFtItTptStPt "Aftertreatment 1 Diesel Particulate Filter Intake Temperature Set Point: Set point temperature for the particulate filter (DPF) regeneration at the intake to the DPF for Exhaust bank 1.";
CM_ SG_ 2566709502 EngineUnburnedFuelPercentage "Engine Unburned Fuel Percentage: The unburned amount of diesel fuel coming out of the engine. This fuel increases the temperature while oxidated in the DOC. Therefore, this amount of fuel also needs to be taken into account of the HCD temperature con...";
CM_ BO_ 2566709758 "Fuel Economy 2 (Liquid)";
CM_ SG_ 2566709758 EngineDieselFuelDemandRate "Engine Diesel Fuel Demand Rate: Amount of diesel fuel that would be consumed by an engine per unit of time if it were not substituting gaseous fuel.  This parameter is the sum of SPN 183 and the amount of diesel fuel that is being displaced by gaseou...";
CM_ SG_ 2566709758 EngineFuelRateHighResolution "Engine Fuel Rate (High Resolution): Amount of fuel consumed by engine per unit of time.  NOTE - See SPN 183 for alternate resolution.";
CM_ BO_ 2566710014 "Supplemental Fan Status";
CM_ SG_ 2566710014 SpplmntlFnCntrllrECUTmprtr "Supplemental Fan Controller ECU Temperature: Measured temperature of Supplemental Fan Controller ECU.";
CM_ SG_ 2566710014 SpplmntlFnCntrllrTmprtrStts "Supplemental Fan Controller Temperature Status: Internal Controller Temperature Status of Supplemental Fan.000b = High most severe 001b = High Least severe 010b = In Range 011b = Low Least severe 100b = Low Most severe 101b = Not Defined 110b = Error...";
CM_ SG_ 2566710014 SupplementalFanCurrent "Supplemental Fan Current: Measured electrical current of supplemental fan drive.";
CM_ SG_ 2566710014 SupplementalFanDirectionStatus "Supplemental Fan Direction Status: Rotational Direction of Supplemental Fan. Fan could be spinning forward or reverse.00b = Forward01b = Reverse10b = Error11b = Not available/Not installed";
CM_ SG_ 2566710014 SupplementalFanDriveStatus "Supplemental Fan Drive Status: The drive status of the Supplemental Fan. This status parameter indicates the overall health of the fan drive. It will indicate that the fan is working OK or if there is an internal fault such as open winding or interna...";
CM_ SG_ 2566710014 SupplementalFanEnableStatus "Supplemental Fan Enable Status: Enable/Disable Status of Supplemental Fan.00b = Disabled01b = Enabled10b = Error11b = Not available/Not installed";
CM_ SG_ 2566710014 SupplementalFanPower "Supplemental Fan Power: Estimated Power output of Supplemental Fan";
CM_ SG_ 2566710014 SupplementalFanSpeed "Supplemental Fan Speed: Measured speed of supplemental fan.";
CM_ SG_ 2566710014 SupplementalFanVelocityStatus "Supplemental Fan Velocity Status: Status of the rotational velocity of Supplemental Fan. Used to indicate if the fan is spinning at the desired speed. If fan is not able to obtain the commanded speed, velocity error is indicated. If fan is unable to ...";
CM_ BO_ 2566710526 "Engine Fuel Properties";
CM_ SG_ 2566710526 EngineFuelDensity "Engine Fuel Density: Density of engine fuel";
CM_ SG_ 2566710526 EngineFuelDynamicViscosity "Engine Fuel Dynamic Viscosity: Dynamic viscosity of engine fuel";
CM_ SG_ 2566710526 EngnFl1Tmprtr1HghRsltn "Engine Fuel 1 Temperature 1 (High Resolution): Engine Fuel Temperature of the first fuel type. See also SPNs 174 or 3468 for alternate resolution.";
CM_ SG_ 2566710526 EngnFlDltrtHghRsltn "Engine Fuel Dielectricity (High Resolution): Engine fuel relative dielectricity.";
CM_ BO_ 2566710782 "Hydraulic Oil Properties";
CM_ SG_ 2566710782 HdrlOlRltvDltrtHghRsltn "Hydraulic Oil Relative Dielectricity (High Resolution): Hydraulic oil relative dielectricity used to describe the hydraulic oil quality.  This hydraulic fluid is for the entire hydraulics system of a piece of equipment.";
CM_ SG_ 2566710782 HdrlOlTmprtrHghRsltn "Hydraulic Oil Temperature (High Resolution): Hydraulic Oil Temperature.  This hydraulic fluid is for the entire hydraulics system of a piece of equipment.";
CM_ SG_ 2566710782 HydraulicOilDensity "Hydraulic Oil Density: Density of hydraulic oil.  This hydraulic fluid is for the entire hydraulics system of a piece of equipment.";
CM_ SG_ 2566710782 HydraulicOilDynamicViscosity "Hydraulic Oil Dynamic Viscosity: Dynamic viscosity of hydraulic oil.  This hydraulic fluid is for the entire hydraulics system of a piece of equipment.";
CM_ BO_ 2566711038 "Vehicle/Chassis Lubrication System 2";
CM_ SG_ 2566711038 LubricationCycleModeLockStatus "Lubrication Cycle Mode Lock Status: Reports status of the ability to change the lubrication cycle mode.  Locking the lubrication mode would prevent the changing of the lubrication cycle mode, perhaps by an operator00b = Not Locked01b = Locked10b = Er...";
CM_ SG_ 2566711038 LubricationCycleModeStatus "Lubrication Cycle Mode Status: Reports the current lubrication cycle mode of the lubrication system000b = Cycle mode # 1 (Lowest Lubrication Frequency)001b = Cycle mode # 2010b = Cycle mode # 3 (Highest Lubrication Frequency)011b to 101b = Reserved 1...";
CM_ SG_ 2566711038 LubricationOperationModeStatus "Lubrication Operation Mode Status: Reports the current operational mode status of the lubrication system.  Automatic is the normal operation mode of lubrication system. In this mode the operator has the privilege to change duty cycle mode, if the lub...";
CM_ SG_ 2566711038 LubricationPumpEnableStatus "Lubrication Pump Enable Status: Reports the operational status of the lubrication system pump.  In the disabled state, the lubrication pump will not run a lubrication cycle.  In the enabled state, the lubrication system will perform normal operations...";
CM_ SG_ 2566711038 LubricationReservoirLevel "Lubrication Reservoir Level: Reports the status of the lubrication system reservior level.  The lubrication reservoir stores the grease for the lubrication system. The lubrication pump draws grease from this reservoir and pushes it into the vehicle/c...";
CM_ SG_ 2566711038 LubricationTimingCycleStatus "Lubrication Timing Cycle Status: Reports the status of the lubrication activation clock.00b = Paused 01b = Enabled10b = Error 11b = Not available or not installed     Note:  In some vehicles or machines, lubrication is only required when the vehicle ...";
CM_ BO_ 2566711294 "Engine Configuration 3";
CM_ SG_ 2566711294 EngnFrtnPrntTrqAtIdlPnt1 "Engine Friction Percent Torque At Idle, Point 1: The static portion of the friction torque at speed point 1 (SPN 188) of the engine torque map in the engine configuration message.  This parameter does not include Estimated Pumping – Percent Torque (S...";
CM_ SG_ 2566711294 EngnFrtnPrntTrqPnt2 "Engine Friction Percent Torque, Point 2: The static portion of the friction torque at speed point 2 (SPN 528) of the engine torque map in the engine configuration message.  This parameter does not include Estimated Pumping – Percent Torque (SPN 5398)...";
CM_ SG_ 2566711294 EngnFrtnPrntTrqPnt3 "Engine Friction Percent Torque, Point 3: The static portion of the friction torque at speed point 3 (SPN 529) of the engine torque map in the engine configuration message.  This parameter does not include Estimated Pumping – Percent Torque (SPN 5398)...";
CM_ SG_ 2566711294 EngnFrtnPrntTrqPnt4 "Engine Friction Percent Torque, Point 4: The static portion of the friction torque at speed point 4 (SPN 530) of the engine torque map in the engine configuration message.  This parameter does not include Estimated Pumping – Percent Torque (SPN 5398)...";
CM_ SG_ 2566711294 EngnFrtnPrntTrqPnt5 "Engine Friction Percent Torque, Point 5: The static portion of the friction torque at speed point 5 (SPN 531) of the engine torque map in the engine configuration message.  This parameter does not include Estimated Pumping – Percent Torque (SPN 5398)...";
CM_ SG_ 2566711294 EngnFrtnPrntTrqPnt6 "Engine Friction Percent Torque, Point 6: For engine configuration map modes 1 and 2, this is the static portion of the friction torque at speed point 6 (SPN 532) of the engine torque map.  For engine configuration map mode 3, this parameter is the st...";
CM_ SG_ 2566711294 EngnFrtnPrntTrqPnt7 "Engine Friction Percent Torque, Point 7: The static portion of the friction torque at speed point 7 (SPN 533) of the engine torque map in the engine configuration message.  This parameter does not include Estimated Pumping – Percent Torque (SPN 5398)...";
CM_ BO_ 2566711550 "Intake Valve Actuation Control";
CM_ SG_ 2566711550 ItVvAttSstOPss1SdCt "Intake Valve Actuation System Oil Pressure 1 Solenoid Control: Indicates the current command to the solenoid that controls the intake valve actuation system oil pressure 1 valve. This valve opens or closes a connection from the intake valve actuation...";
CM_ SG_ 2566711550 ItVvAttSstOPss2SdCt "Intake Valve Actuation System Oil Pressure 2 Solenoid Control: Indicates the current command to the solenoid that controls the intake valve actuation system oil pressure 2 valve. This valve opens or closes a connection from the intake valve actuation...";
CM_ BO_ 2566711806 "Armrest Switch Matrix Commands";
CM_ SG_ 2566711806 Armrest1Switch1 "Armrest 1 Switch 1: Status of the first switch located in armrest 1.00b = Off01b = On10b = Reserved11b = Don't care/take no action";
CM_ SG_ 2566711806 Armrest1Switch2 "Armrest 1 Switch 2: Status of the second switch located in armrest 1.00b = Off01b = On10b = Reserved11b = Don't care/take no action";
CM_ SG_ 2566711806 Armrest2Switch1 "Armrest 2 Switch 1: Status of the first switch located in armrest 2.00b = Off01b = On10b = Reserved11b = Don't care/take no action";
CM_ SG_ 2566711806 Armrest2Switch2 "Armrest 2 Switch 2: Status of the second switch located in armrest 2.00b = Off01b = On10b = Reserved11b = Don't care/take no action";
CM_ BO_ 2566712318 "Aftertreatment 2 NOx Adsorber Information";
CM_ SG_ 2566712318 Aftrtrtmnt2NOxAdsrrDslftnStts "Aftertreatment 2 NOx Adsorber Desulfation Status: Indicates whether the NOx adsorber desulfation regeneration in the second aftertreatment system is active or inactive00b = Inactive01b = Active10b = Error indicator11b = Not available";
CM_ SG_ 2566712318 Aftrtrtmnt2NOxAdsrrRgnrtnStts "Aftertreatment 2 NOx Adsorber Regeneration Status: Indicates whether the NOx adsorber regeneration in the second aftertreatment system is active or inactive00b = Inactive01b = Active10b = Error indicator11b = Not available";
CM_ BO_ 2566712574 "Aftertreatment 1 NOx Adsorber Information";
CM_ SG_ 2566712574 Aftrtrtmnt1NOxAdsrrDslftnStts "Aftertreatment 1 NOx Adsorber Desulfation Status: Indicates whether the NOx adsorber desulfation regeneration in the first aftertreatment system is active or inactive00b = Inactive01b = Active10b = Error indicator11b = Not available";
CM_ SG_ 2566712574 Aftrtrtmnt1NOxAdsrrRgnrtnStts "Aftertreatment 1 NOx Adsorber Regeneration Status: Indicates whether the NOx adsorber regeneration in the first aftertreatment system is active or inactive.00b = Inactive01b = Active10b = Error indicator11b = Not available";
CM_ BO_ 2566712830 "Aftertreatment 2 Warm Up Diesel Oxidation Catalyst Information";
CM_ SG_ 2566712830 Atttt2WUpDsOxdtCtstItTpt "Aftertreatment 2 Warm Up Diesel Oxidation Catalyst Intake Temperature: Temperature of engine combustion byproducts entering the warm up Diesel Oxidation Catalyst in exhaust bank 2.  This diesel parameter should be used with engines fueled by diesel f...";
CM_ SG_ 2566712830 Atttt2WUpDsOxdtCtstOttTpt "Aftertreatment 2 Warm Up Diesel Oxidation Catalyst Outlet Temperature: Temperature of engine combustion byproducts leaving the warm up Diesel Oxidation Catalyst in exhaust bank 2.  This diesel parameter should be used with engines fueled by diesel fu...";
CM_ BO_ 2566713598 "Engine Fuel/Lube Systems 2";
CM_ SG_ 2566713598 EngnFlFltrStnSdDgrdtn "Engine Fuel Filter (Suction Side) Degradation: The estimated percentage relative to the useful life of the engine fuel filter on the suction side which is located betwee the fuel tank and the fuel supply pump.Note:  This is not a calculation of the p...";
CM_ SG_ 2566713598 EngnFlFltrStnSdIntkAsltPrssr "Engine Fuel Filter (Suction Side) Intake Absolute Pressure: Absolute pressure of fuel at the intake of the fuel filter (suction side) located between the fuel tank and the fuel supply pump.  See Figures SPN16_A & SPN16_B.";
CM_ SG_ 2566713598 FuelTankTransferPump "Fuel Tank Transfer Pump: Operating state of the fuel tank transfer pump. The fuel tank transfer pump transfers fuel from the secondary fuel tank to the primary fuel tank.00b = Off01b = On10b = Error11b = Not available";
CM_ SG_ 2566713598 FuelTankTransferPumpPressure "Fuel Tank Transfer Pump Pressure: Gage pressure of the fuel in the system as delivered by the transfer pump.";
CM_ SG_ 2566713598 EngineFuelPumpIntakeOilPressure "Engine Fuel Pump Intake Oil Pressure: Oil pressure at the intake of the engine fuel pump.";
CM_ BO_ 2566713854 "Engine Turbocharger Wastegate Actuator and Exhaust Back Pressure Regulator Information";
CM_ SG_ 2566713854 EExstPssRtCtOptStts "Engine Exhaust Pressure Regulator Control Operation Status: Used to identify the status of Engine Exhaust Pressure Regulator.0000b = Normal0001b = Alarm (fully operational but needs service)0010b = Alarm High Severity (functional but transient perfor...";
CM_ SG_ 2566713854 EngnExhstBnk1PrssrRgltrPstn "Engine Exhaust Bank 1 Pressure Regulator Position: The position of the Exhaust Pressure Regulator (EPR) in bank 1 expressed as a percentage of full travel.  One hundred percent means the regulator is fully closed, providing the maximum restriction to...";
CM_ SG_ 2566713854 EngnExhstPrssrAttr1DsrdPstn "Engine Exhaust Pressure Actuator 1 Desired Position: The requested position of the Engine Exhaust Pressure Actuator 1 by the engine ECU, where 0% represents fully closed and 100% represents fully open.This is the position that the device is attemptin...";
CM_ SG_ 2566713854 EngnExhstPrssrAttr1Tmprtr "Engine Exhaust Pressure Actuator 1 Temperature: Temperature of the Engine Exhaust Pressure Actuator 1 drive circuitry.  Temperature excursions may affect the torque output.";
CM_ SG_ 2566713854 EngnExhstPrssrRgltrPrlmnrFMI "Engine Exhaust Pressure Regulator Preliminary FMI: Used to identify the applicable J1939-73 FMI detected in the Engine Exhaust Pressure Regulator (EPR) by the manufacturers software.  When there are multiple failures, the most severe is transmitted.A...";
CM_ SG_ 2566713854 EngnExhstPrssrRgltrTmprtrStts "Engine Exhaust Pressure Regulator Temperature Status: Used to identify the status of the Engine Exhaust Pressure Regulator (EPR) drive circuitry temperature. Temperature excursions may affect the torque output.000b = High most severe001b = High Least...";
CM_ SG_ 2566713854 EngnTrhrgrWstgtAttr1OprtnStts "Engine Turbocharger Wastegate Actuator 1 Operation Status: Used to identify the status of Engine Turbocharger Wastegate Actuator 1.0000b = Normal0001b = Alarm (fully operational but needs service)0010b = Alarm High Severity (functional but transient ...";
CM_ SG_ 2566713854 EngnTrhrgrWstgtAttr1Tmprtr "Engine Turbocharger Wastegate Actuator 1 Temperature: Temperature of the Engine Turbocharger Wastegate Actuator 1 drive circuitry.  Temperature excursions may affect the torque output.";
CM_ SG_ 2566713854 EngnTrhrgrWstgtAttr2OprtnStts "Engine Turbocharger Wastegate Actuator 2 Operation Status: Used to identify the status of Engine Turbocharger Wastegate Actuator 2.0000b = Normal0001b = Alarm (fully operational but needs service)0010b = Alarm High Severity (functional but transient ...";
CM_ SG_ 2566713854 EngnTrhrgrWstgtAttr2PrlmnrFMI "Engine Turbocharger Wastegate Actuator 2 Preliminary FMI: Used to identify the applicable J1939-73 FMI detected in the Engine Turbocharger Wastegate Actuator 2 by the manufacturers software. When there is multiple failures, the most severe is transmi...";
CM_ SG_ 2566713854 EngnTrhrgrWstgtAttr2TmprtrStts "Engine Turbocharger Wastegate Actuator 2 Temperature Status: Used to identify the status of the Engine Turbocharger Wastegate Actuator 2 drive circuitry temperature.  Temperature excursions may affect the torque output.000b = High most severe001b = H...";
CM_ BO_ 2566714110 "Engine Fuel/Throttle Valve Information 1";
CM_ SG_ 2566714110 EngineFuelValve1OperationStatus "Engine Fuel Valve 1 Operation Status: Used to identify the status of Engine Fuel Valve 1.0000b = Normal0001b = Alarm (fully operational but needs service)0010b = Alarm High Severity (functional but transient performance may be reduced)0011b = Derate ...";
CM_ SG_ 2566714110 EngineFuelValve1PreliminaryFMI "Engine Fuel Valve 1 Preliminary FMI: Used to identify the applicable J1939-73 FMI detected in the Engine Fuel Valve 1 by the manufacturers software. When there is multiple failures, the most severe is transmitted.A value of 31 is sent to indicate tha...";
CM_ SG_ 2566714110 EngineFuelValve2OperationStatus "Engine Fuel Valve 2 Operation Status: Used to identify the status of Engine Fuel Valve 2.0000b = Normal0001b = Alarm (fully operational but needs service)0010b = Alarm High Severity (functional but transient performance may be reduced)0011b = Derate ...";
CM_ SG_ 2566714110 EngineFuelValve2PreliminaryFMI "Engine Fuel Valve 2 Preliminary FMI: Used to identify the applicable J1939-73 FMI detected in the Engine Fuel Valve 2 by the manufacturers software.  When there is multiple failures, the most severe is transmitted.A value of 31 is sent to indicate th...";
CM_ SG_ 2566714110 EngnDsrdThrttlVlv1Pstn "Engine Desired Throttle Valve 1 Position : The desired position of the Throttle valve 1 (SPN 51) that is regulating the fluid, usually air/fuel mixture to the engine as commanded by the Engine Control unit.  0% represents no supply and 100% is full s...";
CM_ SG_ 2566714110 EngnDsrdThrttlVlv2Pstn "Engine Desired Throttle Valve 2 Position: The desired position of the engine throttle valve 2 (SPN 3673) that is regulating the fluid, usually air/fuel mixture to the engine as commanded by the Engine Control Unit.  0% represents no supply and 100% i...";
CM_ SG_ 2566714110 EngnFlVlv1TmprtrStts "Engine Fuel Valve 1 Temperature Status: Used to identify the status of the Engine Fuel valve 1 drive circuitry temperature.  Temperature excursions may affect the torque output.000b = High Most severe001b = High Least severe010b = In Range011b = Low ...";
CM_ SG_ 2566714110 EngnFlVlv2TmprtrStts "Engine Fuel Valve 2 Temperature Status: Used to identify the status of the Engine Fuel valve 2 drive circuitry temperature.  Temperature excursions may affect the torque output.000b = High most severe001b = High Least severe010b = In Range011b = Low ...";
CM_ SG_ 2566714110 EngnThrttlVlv1OprtnStts "Engine Throttle Valve 1 Operation Status: Used to identify the status of engine throttle valve 1 (SPN 51).0000b = Normal0001b = Alarm (fully operational but needs service)0010b = Alarm High Severity (functional but transient performance may be reduce...";
CM_ SG_ 2566714110 EngnThrttlVlv1PrlmnrFMI "Engine Throttle Valve 1 Preliminary FMI: Used to identify the applicable J1939-73 FMI detected in the engine throttle valve 1 (SPN 51) by the manufacturers software.  When there is multiple failures, the most severe is transmitted.A value of 31 is se...";
CM_ SG_ 2566714110 EngnThrttlVlv1TmprtrStts "Engine Throttle Valve 1 Temperature Status: Used to identify the status of the engine throttle valve 1 (SPN 51) drive circuitry temperature.  Temperature excursions may affect the torque output.000b = High most severe001b = High Least severe010b = In...";
CM_ SG_ 2566714110 EngnThrttlVlv2OprtnStts "Engine Throttle Valve 2 Operation Status: Used to identify the status of engine throttle valve 2 (SPN 3673).0000b = Normal0001b = Alarm (fully operational but needs service)0010b = Alarm High Severity (functional but transient performance may be redu...";
CM_ SG_ 2566714110 EngnThrttlVlv2PrlmnrFMI "Engine Throttle Valve 2 Preliminary FMI: Used to identify the applicable J1939-73 FMI detected in the engine throttle valve 2 (SPN 3673) by the manufacturers software.  When there is multiple failures, the most severe is transmitted.A value of 31 is ...";
CM_ SG_ 2566714110 EngnThrttlVlv2Tmprtrstts "Engine Throttle Valve 2 Temperature status: Used to identify the status of the Engine throttle valve 2 (SPN 3673) drive circuitry temperature.  Temperature excursions may affect the torque output.000b = High Most severe001b = High Least severe010b = ...";
CM_ BO_ 2566714366 "Engine Turbocharger Compressor Bypass Information";
CM_ SG_ 2566714366 EngnTrhrgrCmprssrBpssAttr2Pstn "Engine Turbocharger Compressor Bypass Actuator 2 Position: Measures the position of the turbocharger compressor bypass actuator 2, where 0% represents bypass fully closed and 100% represents bypass fully open. Typically, the compressor bypass is used...";
CM_ SG_ 2566714366 ETCpssBpssAtt1OptStts "Engine Turbocharger Compressor Bypass Actuator 1 Operation Status: Used to identify the status of Engine Turbocharger Compressor Bypass Actuator 1.0000b = Normal0001b = Alarm (fully operational but needs service)0010b = Alarm High Severity (functiona...";
CM_ SG_ 2566714366 ETCpssBpssAtt1Tpt "Engine Turbocharger Compressor Bypass Actuator 1 Temperature: Temperature of the Engine Turbocharger Compressor Bypass Actuator 1 drive circuitry.    Temperature excursions may affect the torque output.";
CM_ SG_ 2566714366 ETCpssBpssAtt2DsdPst "Engine Turbocharger Compressor Bypass Actuator 2 Desired Position: The desired position of the Engine Turbocharger Compressor Bypass actuator 2 by the engine ECU, where 0% represents bypass fully closed and 100% represents bypass fully open.This is t...";
CM_ SG_ 2566714366 ETCpssBpssAtt2OptStts "Engine Turbocharger Compressor Bypass Actuator 2 Operation Status: Used to identify the status of Engine Turbocharger Compressor Bypass Actuator 2.0000b = Normal0001b = Alarm (fully operational but needs service)0010b = Alarm High Severity (functiona...";
CM_ SG_ 2566714366 ETCpssBpssAtt2Tpt "Engine Turbocharger Compressor Bypass Actuator 2 Temperature: Temperature of the Engine Turbocharger Compressor Bypass Actuator 2 drive circuitry.    Temperature excursions may affect the torque output.";
CM_ SG_ 2566714366 ETCpssBpssAtt2TptStts "Engine Turbocharger Compressor Bypass Actuator 2 Temperature Status: Used to identify the status of the Engine Turbocharger Compresssor Bypass Actuator 2 drive circuitry temperature.  Temperature excursions may affect the torque output.000b = High mo...";
CM_ SG_ 2566714366 ETpssBpssAtt2PFMI "Engine Turbocharger compressor Bypass Actuator 2 Preliminary FMI: Used to identify the applicable J1939-73 FMI detected in the Engine Turbocharger Compressor Bypass Actuator 1 by the manufacturers software.  When there is multiple failures, the most ...";
CM_ BO_ 2566714622 "Charge Air Cooler 2";
CM_ SG_ 2566714622 EngnChrgArClr2AmntArTmprtr "Engine Charge Air Cooler 2 Ambient Air Temperature: Temperature of the air surrounding charge air cooler 2.";
CM_ SG_ 2566714622 EngnChrgArClr2Effn "Engine Charge Air Cooler 2 Efficiency: Engine charge air cooler 2 (CAC2) is an indication of the CAC’s ability to reduce the temperature of the combustion air that is being routed through the CAC. 0% = no reduction in temperature, 100% = maximum cool...";
CM_ SG_ 2566714622 EngnChrgArClr2IntkTmprtr "Engine Charge Air Cooler 2 Intake Temperature: Temperature of the combustion air measured at the charge air cooler 2 Intake.";
CM_ SG_ 2566714622 EngnChrgArClr2OtltTmprtr "Engine Charge Air Cooler 2 Outlet Temperature: Temperature of combustion air after it exits from the Charge Air Cooler 2 but before any mixing of recirculated exhaust gas.";
CM_ BO_ 2566714878 "Charge Air Cooler 2 Precooler";
CM_ SG_ 2566714878 EngnChrgArClr2PrlrEffn "Engine Charge Air Cooler 2 Precooler Efficiency: Engine charge air cooler 2 (CAC2) precooler efficiency is an indication of the precooler’s ability to reduce the temperature of the gas that is being routed through the precooler. 0% = no reduction in ...";
CM_ SG_ 2566714878 EngnChrgArClr2PrlrIntkTmprtr "Engine Charge Air Cooler 2 Precooler Intake Temperature: Temperature of the combustion air measured at the charge air cooler 2 precooler Intake.";
CM_ SG_ 2566714878 EngnChrgArClr2PrlrOtltTmprtr "Engine Charge Air Cooler 2 Precooler Outlet Temperature: Temperature of the combustion air measured at the charge air cooler 2 precooler outlet.";
CM_ BO_ 2566715134 "Charge Air Cooler 1";
CM_ SG_ 2566715134 EngnChrgArClr1AmntArTmprtr "Engine Charge Air Cooler 1 Ambient Air Temperature: Temperature of the air surrounding charge air cooler 1.";
CM_ SG_ 2566715134 EngnChrgArClr1Effn "Engine Charge Air Cooler 1 Efficiency: Engine charge air cooler 1(CAC1) efficiency is an indication of the CAC’s ability to reduce the temperature of the combustion air that is being routed through the CAC1. 0% = no reduction in temperature, 100% = m...";
CM_ SG_ 2566715134 EngnChrgArClr1IntkTmprtr "Engine Charge Air Cooler 1 Intake Temperature: Temperature of the combustion air measured at the CAC 1 Intake.";
CM_ BO_ 2566715390 "Charge Air Cooler 1 Precooler";
CM_ SG_ 2566715390 EngnChrgArClr1PrlrEffn "Engine Charge Air Cooler 1 Precooler Efficiency: Engine charge air cooler 1 (CAC1) precooler efficiency is an indication of the precooler’s ability to reduce the temperature of the combustion air that is being routed through the precooler. 0% = no re...";
CM_ SG_ 2566715390 EngnChrgArClr1PrlrIntkTmprtr "Engine Charge Air Cooler 1 Precooler Intake Temperature: Temperature of the combustion air measured at the charge air cooler 1 precooler intake.";
CM_ SG_ 2566715390 EngnChrgArClr1PrlrOtltTmprtr "Engine Charge Air Cooler 1 Precooler Outlet Temperature: Temperature of the combustion air measured at the charge air cooler 1 precooler outlet.";
CM_ BO_ 2566715646 "Diesel Particulate Filter 2 Soot 2";
CM_ SG_ 2566715646 Atttt2DsPttFtStSM "Aftertreatment 2 Diesel Particulate Filter Soot Signal Minimum: Minimum output signal level of the current soot measurement from diesel particulate filter 2 soot sensor.  This is a statistical value, not the minimum sensing capability of the sensor.";
CM_ SG_ 2566715646 Atttt2DsPttFtStSMx "Aftertreatment 2 Diesel Particulate Filter Soot Signal Maximum: Maximum output signal level of the current soot measurement from diesel particulate filter 2 soot sensor.  This is a statistical value, not the maximum sensing capability of the sensor.";
CM_ SG_ 2566715646 Atttt2DsPttFtStSStddDvt "Aftertreatment 2 Diesel Particulate Filter Soot Signal Standard Deviation: Standard deviation of the soot measurement from diesel particulate filter 2 soot sensor.";
CM_ BO_ 2566715902 "Diesel Particulate Filter 1 Soot 2";
CM_ SG_ 2566715902 Atttt1DsPttFtStSM "Aftertreatment 1 Diesel Particulate Filter Soot Signal Minimum: Minimum output signal level of the current soot measurement from diesel particulate filter 1 soot sensor.  This is a statistical value, not the minimum sensing capability of the sensor.";
CM_ SG_ 2566715902 Atttt1DsPttFtStSMx "Aftertreatment 1 Diesel Particulate Filter Soot Signal Maximum: Maximum output signal level of the current soot measurement from diesel particulate filter 1 soot sensor.  This is a statistical value, not the maximum sensing capability of the sensor.";
CM_ SG_ 2566715902 Atttt1DsPttFtStSStddDvt "Aftertreatment 1 Diesel Particulate Filter Soot Signal Standard Deviation: Standard deviation of the soot measurement from diesel particulate filter 1 soot sensor.";
CM_ BO_ 2566717438 "Engine Temperature 5";
CM_ SG_ 2566717438 EngnExhstGsRrltn2MxrIntkTmprtr "Engine Exhaust Gas Recirculation 2 Mixer Intake Temperature: The temperature of the EGR gas entering the intake of EGR2 system mixer.";
CM_ SG_ 2566717438 EngnExhstGsRrltn2Tmprtr "Engine Exhaust Gas Recirculation 2 Temperature : Temperature of Recirculated Exhaust Gas of EGR2";
CM_ BO_ 2566717950 "Low Voltage Disconnect  Status";
CM_ SG_ 2566717950 LowVoltageDisconnectTemperature "Low Voltage Disconnect Temperature: Internal temperature of the LVD.";
CM_ SG_ 2566717950 LwVltgDsnntCrrntOprtngMd "Low Voltage Disconnect Current Operating Mode: Current operating mode of the LVD.  The current mode is dependent on the state of the Manual Disconnect/Connect hardwired inputs and on the most-recent received LVD Set Desired Operating Mode message.  T...";
CM_ SG_ 2566717950 LwVltgDsnntMnlCnntStt "Low Voltage Disconnect Manual Connect State: State of the Manual Connect hardwired input to the LVD.  Manual Connect is used to override the LVD's normal activlty and connect all of the LVD outputs.  Manual Connect has priority over the Manual Dicson...";
CM_ SG_ 2566717950 LwVltgDsnntMnlDsnntStt "Low Voltage Disconnect Manual Disconnect State: State of the Manual Disconnect hardwired input to the LVD.  Manual Disconnect is used to override the LVD's normal activlty and dicconnect all of the LVD outputs.  Manual Disconnect is lower in priority...";
CM_ SG_ 2566717950 LwVltgDsnntOtpt1Stt "Low Voltage Disconnect Output #1 State: State of the Output #1 from the LVD.  Output #1 controls an external load or relay.  This external load could be independent of the main output, and may apply to an application specific circuit or zone.  If the...";
CM_ SG_ 2566717950 LwVltgDsnntOtpt2Stt "Low Voltage Disconnect Output #2 State: State of the Output #2 from the LVD.  Output #2 controls an external load or relay.  This external load could be independent of the main output, and may apply to an application specific circuit or zone.  If the...";
CM_ SG_ 2566717950 LwVltgDsnntOtpt3Stt "Low Voltage Disconnect Output #3 State: State of the Output #3 from the LVD.  Output #3 controls an external load or relay.  This external load could be independent of the main output, and may apply to an application specific circuit or zone.  If the...";
CM_ SG_ 2566717950 LwVltgDsnntVtOtptStt "Low Voltage Disconnect Vout Output State: State of the Vout Output from the LVD.  Vout is the LVD's main internal, controllable, high-current output.  If the LVD supports prioritization, this circuit will be the last to disconnect and the first to re...";
CM_ BO_ 2566718718 "Direct Lamp Control Data 2";
CM_ SG_ 2566718718 HillHolderLampData "Hill Holder Lamp Data: This message will be transmitted by the controller that is illuminating the lamps.00b = Lamp deactivated (Off)01b = Lamp activated (On)10b = Error11b = Not Available";
CM_ SG_ 2566718718 VehicleAirPressureLowLampData "Vehicle Air Pressure Low Lamp Data: This parameter provides measured data from the Vehicle Air Pressure Low Lamp.00b = Lamp deactivated (Off)01b = Lamp activated (On)10b = Error11b = Not available";
CM_ SG_ 2566718718 VehicleBatteryChargingLampData "Vehicle Battery Charging Lamp Data: This parameter provides measured data from the Vehicle Battery Charging Lamp.00b = Lamp deactivated (Off)01b = Lamp activated (On)10b = Error11b = Not available";
CM_ SG_ 2566718718 VehicleFuelLevelLowLampData "Vehicle Fuel Level Low Lamp Data: This parameter provides measured data from the Vehicle Fuel Level Low Lamp.00b = Lamp deactivated (Off)01b = Lamp activated (On)10b = Error11b = Not available";
CM_ SG_ 2566718718 VhlBttrVltgLwLmpDt "Vehicle Battery Voltage Low Lamp Data: This parameter provides measured data from the Vehicle Battery Voltage Low Lamp.00b = Lamp deactivated (Off)01b = Lamp activated (On)10b = Error11b = Not available";
CM_ SG_ 2566718718 VhlHVACRrltnLmpDt "Vehicle HVAC Recirculation Lamp Data: This parameter provides measured data from the Vehicle HVAC Recirculation Lamp.00b = Lamp deactivated (Off)01b = Lamp activated (On)10b = Error11b = Not available";
CM_ SG_ 2566718718 VhlLmtdPrfrmnMdLmpDt "Vehicle Limited Performance Mode Lamp Data: This parameter provides measured data from the Vehicle Limited Performance Mode Lamp.Vehicle limited performance mode is when a derate is active, for example.00b = Lamp deactivated (Off)01b = Lamp activated...";
CM_ SG_ 2566718718 PrimaryAirPressureLowLampData "Primary Air Pressure Low Lamp Data: This parameter provides measured data from the Primary Air Pressure Lamp.00b = Lamp deactivated (Off)01b = Lamp activated (On)10b = Error11b = Not available";
CM_ SG_ 2566718718 SecondaryAirPressureLowLampData "Secondary Air Pressure Low Lamp Data: This parameter provides measured data from the Secondary Air Pressure Lamp.00b = Lamp deactivated (Off)01b = Lamp activated (On)10b = Error11b = Not available";
CM_ SG_ 2566718718 OptionalLamp1Data "Optional Lamp 1 Data: This parameter provides measured data from Optional Lamp #1. Optional lamps are those that are configured for a specific application.00b = Lamp deactivated (Off)01b = Lamp activated (On)10b = Error11b = Not available";
CM_ SG_ 2566718718 OptionalLamp2Data "Optional Lamp 2 Data: This parameter provides measured data from Optional Lamp #2. Optional lamps are those that are configured for a specific application.00b = Lamp deactivated (Off)01b = Lamp activated (On)10b = Error11b = Not available";
CM_ SG_ 2566718718 OptionalLamp3Data "Optional Lamp 3 Data: This parameter provides measured data from Optional Lamp #3. Optional lamps are those that are configured for a specific application.00b = Lamp deactivated (Off)01b = Lamp activated (On)10b = Error11b = Not available";
CM_ SG_ 2566718718 OptionalLamp4Data "Optional Lamp 4 Data: This parameter provides measured data from Optional Lamp #4. Optional lamps are those that are configured for a specific application.00b = Lamp deactivated (Off)01b = Lamp activated (On)10b = Error11b = Not available";
CM_ SG_ 2566718718 OptionalLamp5Data "Optional Lamp 5 Data: This parameter provides measured data from Optional Lamp #5. Optional lamps are those that are configured for a specific application.00b = Lamp deactivated (Off)01b = Lamp activated (On)10b = Error11b = Not available";
CM_ SG_ 2566718718 OptionalLamp6Data "Optional Lamp 6 Data: This parameter provides measured data from Optional Lamp #6. Optional lamps are those that are configured for a specific application.00b = Lamp deactivated (Off)01b = Lamp activated (On)10b = Error11b = Not available";
CM_ BO_ 2566718974 "Direct Lamp Control Data 1";
CM_ SG_ 2566718974 CmprssnBrkEnlSwthIndtrLmpDt "Compression Brake Enable Switch Indicator Lamp Data: This parameter provides measured data from the Compression Brake Enable Switch Indicator Lamp.00b = Lamp deactivated (Off)01b = Lamp activated (On)10b = Error11b = Not available";
CM_ SG_ 2566718974 EngineAmberWarningLampData "Engine Amber Warning Lamp Data: This parameter provides measured data from the Engine Amber Warning Lamp.00b = Lamp deactivated (Off)01b = Lamp activated (On)10b = Error11b = Not available";
CM_ SG_ 2566718974 EngineBrakeActiveLampData "Engine Brake Active Lamp Data: This parameter provides measured data from the Engine Brake Active Lamp.00b = Lamp deactivated (Off)01b = Lamp activated (On)10b = Error11b = Not available";
CM_ SG_ 2566718974 EngineCoolantLevelLowLampData "Engine Coolant Level Low Lamp Data: This parameter provides measured data from the Engine Coolant Level Low Lamp.00b = Lamp deactivated (Off)01b = Lamp activated (On)10b = Error11b = Not available";
CM_ SG_ 2566718974 EngineOilPressureLowLampData "Engine Oil Pressure Low Lamp Data: This parameter provides measured data from the Engine Oil Pressure Low Lamp.00b = Lamp deactivated (Off)01b = Lamp activated (On)10b = Error11b = Not available";
CM_ SG_ 2566718974 EngineProtectLampData "Engine Protect Lamp Data: This parameter provides measured data from the Engine Protect Lamp.00b = Lamp deactivated (Off)01b = Lamp activated (On)10b = Error11b = Not available";
CM_ SG_ 2566718974 EngineRedStopLampData "Engine Red Stop Lamp Data: This parameter provides measured data from the Engine Red Stop Lamp.00b = Lamp deactivated (Off)01b = Lamp activated (On)10b = Error11b = Not available";
CM_ SG_ 2566718974 EngineSpeedHighLampData "Engine Speed High Lamp Data: This parameter provides measured data from the Engine Speed High Warning Lamp.00b = Lamp Deactivated (Off)01b = Lamp Activated (On)10b = Error11b = Not available";
CM_ SG_ 2566718974 EngineSpeedVeryHighLampData "Engine Speed Very High Lamp Data: This parameter provides measured data from the Engine Speed Very High Warning Lamp.00b = Lamp Deactivated (Off)01b = Lamp Activated (On)10b = Error11b = Not available";
CM_ SG_ 2566718974 EngineWaitToStartLampData "Engine Wait To Start Lamp Data: This parameter provides measured data from the Engine Wait To Start Lamp.  See SPN 1081 for the command.00b = Lamp deactived (off)01b = Lamp actived (on)10b = Error11b = Not available";
CM_ SG_ 2566718974 EngnArFltrRstrtnLmpDt "Engine Air Filter Restriction Lamp Data: This parameter provides measured data from the Engine Air Filter Restriction Lamp.00b = Lamp deactivated (Off)01b = Lamp activated (On)10b = Error11b = Not available";
CM_ SG_ 2566718974 EngnClntTmprtrHghLmpDt "Engine Coolant Temperature High Lamp Data: This parameter provides measured data from the Engine Coolant Temperature High Lamp.00b = Lamp deactivated (Off)01b = Lamp activated (On)10b = Error11b = Not available";
CM_ SG_ 2566718974 EngnCntrlMdl1RdfrUsLmpDt "Engine Control Module 1 Ready for Use Lamp Data: This parameter provides measured data from the Engine Control Module 1 Ready for Use Lamp.00b = Lamp deactivated (Off)01b = Lamp activated (On)10b = Error11b = Not Available";
CM_ SG_ 2566718974 EngnCntrlMdl2RdfrUsLmpDt "Engine Control Module 2 Ready for Use Lamp Data: This parameter provides measured data from the Engine Control Module 2 Ready for Use Lamp.00b = Lamp deactivated (Off)01b = Lamp activated (On)10b = Error11b = Not Available";
CM_ SG_ 2566718974 EngnCntrlMdl3RdfrUsLmpDt "Engine Control Module 3 Ready for Use Lamp Data: This parameter provides measured data from the Engine Control Module 3 Ready for Use Lamp.00b = Lamp deactivated (Off)01b = Lamp activated (On)10b = Error11b = Not Available";
CM_ SG_ 2566718974 EngnFlFltrRstrtdLmpDt "Engine Fuel Filter Restricted Lamp Data: This parameter provides measured data from the Engine Fuel Filter Restricted Lamp.00b = Lamp deactivated (Off)01b = Lamp activated (On)10b = Error11b = Not available";
CM_ SG_ 2566718974 EngnIdlMngmntAtvLmpDt "Engine Idle Management Active Lamp Data: This parameter provides measured data from the Engine Idle Management Active Lamp.00b = Lamp deactivated (Off)01b = Lamp activated (On)10b = Error11b = Not available";
CM_ SG_ 2566718974 OBDMalfunctionIndicatorLampData "OBD Malfunction Indicator Lamp Data: This parameter provides measured data from the OBD Malfunction Indicator Lamp.00b = Lamp deactivated (Off)01b = Lamp activated (On)10b = Error11b = Not available";
CM_ SG_ 2566718974 VhlAlrtnRtLmtLmpDt "Vehicle Acceleration Rate Limit Lamp Data: This parameter provides measured data from the Vehicle Acceleration Rate Limit Lamp.00b = Lamp deactivated (Off)01b = Lamp activated (On)10b = Error11b = Not available";
CM_ SG_ 2566718974 EngnStpStrtAtmtStpAtvLmpDt "Engine Stop-Start Automatic Stop Active Lamp Data: Provides measured data from the engine stop-start automatic stop active lamp.00b = Lamp deactivated (Off)01b = Lamp activated (On)10b = Error11b = Not available";
CM_ SG_ 2566718974 EngnStpStrtAtmtStrtFldLmpDt "Engine Stop-Start Automatic Start Failed Lamp Data: Provides measured data from the engine stop-start automatic start failed lamp.00b = Lamp deactivated (Off)01b = Lamp activated (On)10b = Error11b = Not available";
CM_ SG_ 2566718974 EngineStopStartEnabledLampData "Engine Stop-Start Enabled Lamp Data: Provides measured data from the engine stop-start enabled lamp.00b = Lamp deactivated (Off)01b = Lamp activated (On)10b = Error11b = Not available";
CM_ SG_ 2566718974 EngnOlTmprtrHghLmpDt "Engine Oil Temperature High Lamp Data: This parameter provides measured data from the Engine Oil Temperature Lamp.00b = Lamp deactivated (Off)01b = Lamp activated (On)10b = Error11b = Not available";
CM_ SG_ 2566718974 EngnFlTmprtrHghLmpDt "Engine Fuel Temperature High Lamp Data: This parameter provides measured data from the Engine Fuel Temperature Lamp.00b = Lamp deactivated (Off)01b = Lamp activated (On)10b = Error11b = Not available";
CM_ SG_ 2566718974 EngnIntrlrTmprtrHghLmpDt "Engine Intercooler Temperature High Lamp Data: This parameter provides measured data from the Engine Intercooler Temperature Lamp.00b = Lamp deactivated (Off)01b = Lamp activated (On)10b = Error11b = Not available";
CM_ SG_ 2566718974 EngineAirShutoffLampData "Engine Air Shutoff Lamp Data: This parameter provides measured data from the Engine Air Shutoff Lamp.00b = Lamp Deactivated (Off)01b = Lamp Activated (On)10b = Error11b = Not available";
CM_ BO_ 2566719230 "Direct Lamp Control Command 2";
CM_ SG_ 2566719230 HillHolderLampCommand "Hill Holder Lamp Command: Command signal directly controlling Hill Holder Lamp.00b = Lamp Off01b = Lamp On10b = Lamp Flash (1 Hz)11b = Not available";
CM_ SG_ 2566719230 VehicleFuelLevelLowLampCommand "Vehicle Fuel Level Low Lamp Command: Command signal directly controlling the Vehicle Fuel Level Low Lamp.00b = Lamp Off01b = Lamp On10b = Reserved11b = Not available";
CM_ SG_ 2566719230 VhlArPrssrLwLmpCmmnd "Vehicle Air Pressure Low Lamp Command: Command signal directly controlling the Vehicle Air Pressure Low Lamp.00b = Lamp Off01b = Lamp On10b = Reserved11b = Not available";
CM_ SG_ 2566719230 VhlBttrChrgngLmpCmmnd "Vehicle Battery Charging Lamp Command: Command signal directly controlling the Vehicle Battery Charging Lamp.00b = Lamp Off01b = Lamp On10b = Reserved11b = Not available";
CM_ SG_ 2566719230 VhlBttrVltgLwLmpCmmnd "Vehicle Battery Voltage Low Lamp Command: Command signal directly controlling the Vehicle Battery Voltage Low Lamp.00b = Lamp Off01b = Lamp On10b = Reserved11b = Not available";
CM_ SG_ 2566719230 VhlHVACRrltnLmpCmmnd "Vehicle HVAC Recirculation Lamp Command: Command signal directly controlling the Vehicle HVAC Recirculation Lamp.00b = Lamp Off01b = Lamp On10b = Reserved11b = Not available";
CM_ SG_ 2566719230 VhlLmtdPrfrmnMdLmpCmmnd "Vehicle Limited Performance Mode Lamp Command: Command signal directly controlling the vehicle limited performance mode lamp.Vehicle limited performance mode is when a derate is active, for example.00b = Lamp Off01b = Lamp On10b = Reserved11b = Not a...";
CM_ SG_ 2566719230 PrmrArPrssrLwLmpCmmnd "Primary Air Pressure Low Lamp Command: Command signal directly controlling the Primary Air Pressure Lamp.00b = Lamp Off01b = Lamp On10b = Reserved11b = Not available";
CM_ SG_ 2566719230 SndrArPrssrLwLmpCmmnd "Secondary Air Pressure Low Lamp Command: Command signal directly controlling the Secondary Air Pressure Lamp.00b = Lamp Off01b = Lamp On10b = Reserved11b = Not available";
CM_ SG_ 2566719230 OptionalLamp1Command "Optional Lamp 1 Command: Command signal directly controlling Optional Lamp #1. Optional lamps are those that are configured for a specific application.00b = Lamp Off01b = Lamp On10b = Reserved11b = Not available";
CM_ SG_ 2566719230 OptionalLamp2Command "Optional Lamp 2 Command: Command signal directly controlling Optional Lamp #2. Optional lamps are those that are configured for a specific application.00b = Lamp Off01b = Lamp On10b = Reserved11b = Not available";
CM_ SG_ 2566719230 OptionalLamp3Command "Optional Lamp 3 Command: Command signal directly controlling Optional Lamp #3. Optional lamps are those that are configured for a specific application.00b = Lamp Off01b = Lamp On10b = Reserved11b = Not available";
CM_ SG_ 2566719230 OptionalLamp4Command "Optional Lamp 4 Command: Command signal directly controlling Optional Lamp #4. Optional lamps are those that are configured for a specific application.00b = Lamp Off01b = Lamp On10b = Reserved11b = Not available";
CM_ SG_ 2566719230 OptionalLamp5Command "Optional Lamp 5 Command: Command signal directly controlling Optional Lamp #5. Optional lamps are those that are configured for a specific application.00b = Lamp Off01b = Lamp On10b = Reserved11b = Not available";
CM_ SG_ 2566719230 OptionalLamp6Command "Optional Lamp 6 Command: Command signal directly controlling Optional Lamp #6. Optional lamps are those that are configured for a specific application.00b = Lamp Off01b = Lamp On10b = Reserved11b = Not available";
CM_ BO_ 2566719486 "Direct Lamp Control Command 1";
CM_ SG_ 2566719486 CmprssnBrkEnlSwthIndtrLmpCmmnd "Compression Brake Enable Switch Indicator Lamp Command: Command signal directly controlling Compression Brake Enable Switch Indicator Lamp.  The compression brake switch indicator signals the status of the compression brake enable switch to the opera...";
CM_ SG_ 2566719486 EngineAmberWarningLampCommand "Engine Amber Warning Lamp Command: Command signal directly controlling the Engine Amber Warning Lamp00b = Lamp Off01b = Lamp On10b = Reserved11b = Not availableNote:  SPN 624 should be used for reporting diagnostics of the Engine Amber Warning Lamp....";
CM_ SG_ 2566719486 EngineBrakeActiveLampCommand "Engine Brake Active Lamp Command: Command signal directly controlling the Engine Brake Active Lamp. This is used for engine based retarders.00b = Lamp Off01b = Lamp On10b = Reserved11b = Not available";
CM_ SG_ 2566719486 EngineOilPressureLowLampCommand "Engine Oil Pressure Low Lamp Command: Command signal directly controlling the Engine Oil Pressure Low Lamp00b = Lamp Off01b = Lamp On10b = Reserved11b = Not available";
CM_ SG_ 2566719486 EngineProtectLampCommand "Engine Protect Lamp Command: Command signal directly controlling the Engine Protect Lamp00b = Lamp Off01b = Lamp On10b = Reserved11b = Not availableNote:  SPN 987 should be used for reporting diagnostics of the Engine Protect Lamp.";
CM_ SG_ 2566719486 EngineRedStopLampCommand "Engine Red Stop Lamp Command: Command signal directly controlling the Engine Red Stop Lamp00b = Lamp Off01b = Lamp On10b = Reserved11b = Not availableNote:  SPN 623 should be used for reporting diagnostics of the Engine Red Stop Lamp.";
CM_ SG_ 2566719486 EngineSpeedHighLampCommand "Engine Speed High Lamp Command: Command signal directly controlling the Engine Speed High Warning lamp.00b = Lamp Off01b = Lamp On10b = Reserved11b = Not available";
CM_ SG_ 2566719486 EngineSpeedVeryHighLampCommand "Engine Speed Very High Lamp Command: Command signal directly controlling the Engine Speed Very High Warning lamp.00b = Lamp Off01b = Lamp On10b = Reserved11b = Not available";
CM_ SG_ 2566719486 EngnArFltrRstrtnLmpCmmnd "Engine Air Filter Restriction Lamp Command: Command signal directly controlling the Engine Air Filter Restriction Lamp.00b = Lamp Off01b = Lamp On10b = Reserved11b = Not available";
CM_ SG_ 2566719486 EngnClntLvlLwLmpCmmnd "Engine Coolant Level Low Lamp Command: Command signal directly controlling the Engine Coolant Level Low Lamp00b = Lamp Off01b = Lamp On10b = Reserved11b = Not available";
CM_ SG_ 2566719486 EngnClntTmprtrHghLmpCmmnd "Engine Coolant Temperature High Lamp Command: Command signal directly controlling the Engine Coolant Temperature High Lamp00b = Lamp Off01b = Lamp On10b = Reserved11b = Not available";
CM_ SG_ 2566719486 EngnCntrlMdl1RdfrUsLmpCmmnd "Engine Control Module 1 Ready for Use Lamp Command: Command signal directly controlling the Engine Control Module 1 Ready for use Lamp. This lamp is used to indicate whether ECM 1 can control the operation of the engine. In case of a failure in ECM 1...";
CM_ SG_ 2566719486 EngnCntrlMdl2RdfrUsLmpCmmnd "Engine Control Module 2 Ready for Use Lamp Command: Command signal directly controlling the Engine Control Module 2 Ready for Use Lamp. This lamp is used to indicate whether ECM 2 can control the operation of the engine. In case of a failure in ECM 2...";
CM_ SG_ 2566719486 EngnCntrlMdl3RdfrUsLmpCmmnd "Engine Control Module 3 Ready for Use Lamp Command: Command signal directly controlling the Engine Control Module 3 Ready for Use Lamp. This lamp is used to indicate whether ECM 3 can control the operation of the engine. In case of a failure in ECM 3...";
CM_ SG_ 2566719486 EngnFlFltrRstrtdLmpCmmnd "Engine Fuel Filter Restricted Lamp Command: Command signal directly controlling the Engine Fuel Filter Restricted Lamp.00b = Lamp Off01b = Lamp On10b = Reserved11b = Not available";
CM_ SG_ 2566719486 EngnIdlMngmntAtvLmpCmmnd "Engine Idle Management Active Lamp Command: Command signal directly controlling the Engine Idle Management Active Lamp00b = Lamp Off01b = Lamp On10b = Reserved11b = Not availableNote:  SPN 1661 should be used for reporting diagnostics of the Engine I...";
CM_ SG_ 2566719486 EngnIdlMngmntPndngEvntLmpCmmnd "Engine Idle Management Pending Event Lamp Command: Command signal directly controlling the Engine Idle Management Pending Event Lamp.  An engine start-up or shutdown is considered an event.00b = Lamp Off01b = Lamp On10b = Reserved11b = Not available...";
CM_ SG_ 2566719486 OBDMlfntnIndtrLmpCmmnd "OBD Malfunction Indicator Lamp Command: Command signal directly controlling the OBD Malfunction Indicator Lamp00b = Lamp Off01b = Lamp On10b = Reserved11b = Not availableNote:  SPN 1213 should be used for reporting diagnostics of the OBD Malfunction ...";
CM_ SG_ 2566719486 VhlAlrtnRtLmtLmpCmmnd "Vehicle Acceleration Rate Limit Lamp Command: Command signal directly controlling the Vehicle Acceleration Rate Limit Lamp.00b = Lamp Off01b = Lamp On10b = Reserved11b = Not availableNOTE: SPN 2979 is the original parameter used to provide vehicle ac...";
CM_ SG_ 2566719486 EngnStpStrtAtmtStpAtvLmpCmmnd "Engine Stop-Start Automatic Stop Active Lamp Command: Command signal directly controlling the engine stop-start automatic stop active lamp.00b = Lamp off01b = Lamp on10b = Reserved11b = Not availableNote: SPN 9680 should be used for reporting diagnos...";
CM_ SG_ 2566719486 EngnStpStrtAtmtStrtFldLmpCmmnd "Engine Stop-Start Automatic Start Failed Lamp Command: Command signal directly controlling the engine stop-start automatic start failed lamp.00b = Lamp off01b = Lamp on10b = Reserved11b = Not availableNote: SPN 9681 should be used for reporting diagn...";
CM_ SG_ 2566719486 EngnStpStrtEnldLmpCmmnd "Engine Stop-Start Enabled Lamp Command: Command signal directly controlling the engine stop-start enabled lamp.00b = Lamp off01b = Lamp on10b = Reserved11b = Not availableNote: SPN 9682 should be used for reporting diagnostics of the engine stop-star...";
CM_ SG_ 2566719486 EngnOlTmprtrHghLmpCmmnd "Engine Oil Temperature High Lamp Command: Command signal directly controlling the Engine Oil Temperature Lamp.00b = Lamp Off01b = Lamp On10b = Reserved11b = Not available";
CM_ SG_ 2566719486 EngnFlTmprtrHghLmpCmmnd "Engine Fuel Temperature High Lamp Command: Command signal directly controlling the Engine Fuel Temperature Lamp.00b = Lamp Off01b = Lamp On10b = Reserved11b = Not available";
CM_ SG_ 2566719486 EngnIntrlrTmprtrHghLmpCmmnd "Engine Intercooler Temperature High Lamp Command: Command signal directly controlling the Engine Intercooler Temperature Lamp.00b = Lamp Off01b = Lamp On10b = Reserved11b = Not available";
CM_ SG_ 2566719486 EngineAirShutoffLampCommand "Engine Air Shutoff Lamp Command: Command signal directly controlling the Engine Air Shutoff Lamp.00b = Lamp Off01b = Lamp On10b = Reserved11b = Not available";
CM_ BO_ 2566719998 "High Resolution Fuel Consumption (Liquid)";
CM_ SG_ 2566719998 EngineTripFuelHighResolution "Engine Trip Fuel (High Resolution): Fuel consumed during all or part of a journey.   High resolution used for calculations and fleet management systems.  See SPN 182 for alternate resolution.";
CM_ SG_ 2566719998 EngnTtlFlUsdHghRsltn "Engine Total Fuel Used (High Resolution): Accumulated amount of fuel used during vehicle operation.  High resolution used for calculations and fleet management systems.  See SPN 250 for alternate resolution.";
BA_DEF_ SG_  "SPN" INT 0 524287;
BA_DEF_ BO_  "VFrameFormat" ENUM  "StandardCAN","ExtendedCAN","reserved","J1939PG";
BA_DEF_DEF_  "SPN" 0;
BA_DEF_DEF_  "VFrameFormat" "J1939PG";
BA_ "SPN" SG_ 2566697726 SwitchedOutput10Current 6121;
BA_ "SPN" SG_ 2566697726 SwitchedOutput11Current 6122;
BA_ "SPN" SG_ 2566697726 SwitchedOutput12Current 6123;
BA_ "SPN" SG_ 2566697726 SwitchedOutput13Current 6124;
BA_ "SPN" SG_ 2566697726 SwitchedOutput14Current 6125;
BA_ "SPN" SG_ 2566697726 SwitchedOutput15Current 6126;
BA_ "SPN" SG_ 2566697726 SwitchedOutput16Current 6127;
BA_ "SPN" SG_ 2566697726 SwitchedOutput17Current 6128;
BA_ "SPN" SG_ 2566697726 SwitchedOutput18Current 6129;
BA_ "SPN" SG_ 2566697726 SwitchedOutput19Current 6130;
BA_ "SPN" SG_ 2566697726 SwitchedOutput1Current 6112;
BA_ "SPN" SG_ 2566697726 SwitchedOutput20Current 6131;
BA_ "SPN" SG_ 2566697726 SwitchedOutput21Current 6132;
BA_ "SPN" SG_ 2566697726 SwitchedOutput22Current 6133;
BA_ "SPN" SG_ 2566697726 SwitchedOutput23Current 6134;
BA_ "SPN" SG_ 2566697726 SwitchedOutput24Current 6135;
BA_ "SPN" SG_ 2566697726 SwitchedOutput25Current 6136;
BA_ "SPN" SG_ 2566697726 SwitchedOutput26Current 6137;
BA_ "SPN" SG_ 2566697726 SwitchedOutput27Current 6138;
BA_ "SPN" SG_ 2566697726 SwitchedOutput28Current 6139;
BA_ "SPN" SG_ 2566697726 SwitchedOutput29Current 6140;
BA_ "SPN" SG_ 2566697726 SwitchedOutput2Current 6113;
BA_ "SPN" SG_ 2566697726 SwitchedOutput30Current 6141;
BA_ "SPN" SG_ 2566697726 SwitchedOutput31Current 6142;
BA_ "SPN" SG_ 2566697726 SwitchedOutput32Current 6143;
BA_ "SPN" SG_ 2566697726 SwitchedOutput3Current 6114;
BA_ "SPN" SG_ 2566697726 SwitchedOutput4Current 6115;
BA_ "SPN" SG_ 2566697726 SwitchedOutput5Current 6116;
BA_ "SPN" SG_ 2566697726 SwitchedOutput6Current 6117;
BA_ "SPN" SG_ 2566697726 SwitchedOutput7Current 6118;
BA_ "SPN" SG_ 2566697726 SwitchedOutput8Current 6119;
BA_ "SPN" SG_ 2566697726 SwitchedOutput9Current 6120;
BA_ "SPN" SG_ 2566697982 FusedOutput10Current 6089;
BA_ "SPN" SG_ 2566697982 FusedOutput11Current 6090;
BA_ "SPN" SG_ 2566697982 FusedOutput12Current 6091;
BA_ "SPN" SG_ 2566697982 FusedOutput13Current 6092;
BA_ "SPN" SG_ 2566697982 FusedOutput14Current 6093;
BA_ "SPN" SG_ 2566697982 FusedOutput15Current 6094;
BA_ "SPN" SG_ 2566697982 FusedOutput16Current 6095;
BA_ "SPN" SG_ 2566697982 FusedOutput17Current 6096;
BA_ "SPN" SG_ 2566697982 FusedOutput18Current 6097;
BA_ "SPN" SG_ 2566697982 FusedOutput19Current 6098;
BA_ "SPN" SG_ 2566697982 FusedOutput1Current 6080;
BA_ "SPN" SG_ 2566697982 FusedOutput20Current 6099;
BA_ "SPN" SG_ 2566697982 FusedOutput21Current 6100;
BA_ "SPN" SG_ 2566697982 FusedOutput22Current 6101;
BA_ "SPN" SG_ 2566697982 FusedOutput23Current 6102;
BA_ "SPN" SG_ 2566697982 FusedOutput24Current 6103;
BA_ "SPN" SG_ 2566697982 FusedOutput25Current 6104;
BA_ "SPN" SG_ 2566697982 FusedOutput26Current 6105;
BA_ "SPN" SG_ 2566697982 FusedOutput27Current 6106;
BA_ "SPN" SG_ 2566697982 FusedOutput28Current 6107;
BA_ "SPN" SG_ 2566697982 FusedOutput29Current 6108;
BA_ "SPN" SG_ 2566697982 FusedOutput2Current 6081;
BA_ "SPN" SG_ 2566697982 FusedOutput30Current 6109;
BA_ "SPN" SG_ 2566697982 FusedOutput31Current 6110;
BA_ "SPN" SG_ 2566697982 FusedOutput32Current 6111;
BA_ "SPN" SG_ 2566697982 FusedOutput3Current 6082;
BA_ "SPN" SG_ 2566697982 FusedOutput4Current 6083;
BA_ "SPN" SG_ 2566697982 FusedOutput5Current 6084;
BA_ "SPN" SG_ 2566697982 FusedOutput6Current 6085;
BA_ "SPN" SG_ 2566697982 FusedOutput7Current 6086;
BA_ "SPN" SG_ 2566697982 FusedOutput8Current 6087;
BA_ "SPN" SG_ 2566697982 FusedOutput9Current 6088;
BA_ "SPN" SG_ 2566698238 SwitchedOutput1 6051;
BA_ "SPN" SG_ 2566698238 SwitchedOutput10 6058;
BA_ "SPN" SG_ 2566698238 SwitchedOutput11 6057;
BA_ "SPN" SG_ 2566698238 SwitchedOutput12 6056;
BA_ "SPN" SG_ 2566698238 SwitchedOutput13 6063;
BA_ "SPN" SG_ 2566698238 SwitchedOutput14 6062;
BA_ "SPN" SG_ 2566698238 SwitchedOutput15 6061;
BA_ "SPN" SG_ 2566698238 SwitchedOutput16 6060;
BA_ "SPN" SG_ 2566698238 SwitchedOutput17 6067;
BA_ "SPN" SG_ 2566698238 SwitchedOutput18 6066;
BA_ "SPN" SG_ 2566698238 SwitchedOutput19 6065;
BA_ "SPN" SG_ 2566698238 SwitchedOutput2 6050;
BA_ "SPN" SG_ 2566698238 SwitchedOutput20 6064;
BA_ "SPN" SG_ 2566698238 SwitchedOutput21 6071;
BA_ "SPN" SG_ 2566698238 SwitchedOutput22 6070;
BA_ "SPN" SG_ 2566698238 SwitchedOutput23 6069;
BA_ "SPN" SG_ 2566698238 SwitchedOutput24 6068;
BA_ "SPN" SG_ 2566698238 SwitchedOutput25 6075;
BA_ "SPN" SG_ 2566698238 SwitchedOutput26 6074;
BA_ "SPN" SG_ 2566698238 SwitchedOutput27 6073;
BA_ "SPN" SG_ 2566698238 SwitchedOutput28 6072;
BA_ "SPN" SG_ 2566698238 SwitchedOutput29 6079;
BA_ "SPN" SG_ 2566698238 SwitchedOutput3 6049;
BA_ "SPN" SG_ 2566698238 SwitchedOutput30 6078;
BA_ "SPN" SG_ 2566698238 SwitchedOutput31 6077;
BA_ "SPN" SG_ 2566698238 SwitchedOutput32 6076;
BA_ "SPN" SG_ 2566698238 SwitchedOutput4 6048;
BA_ "SPN" SG_ 2566698238 SwitchedOutput5 6055;
BA_ "SPN" SG_ 2566698238 SwitchedOutput6 6054;
BA_ "SPN" SG_ 2566698238 SwitchedOutput7 6053;
BA_ "SPN" SG_ 2566698238 SwitchedOutput8 6052;
BA_ "SPN" SG_ 2566698238 SwitchedOutput9 6059;
BA_ "SPN" SG_ 2566698494 FusedOutput1 6019;
BA_ "SPN" SG_ 2566698494 FusedOutput10 6026;
BA_ "SPN" SG_ 2566698494 FusedOutput11 6025;
BA_ "SPN" SG_ 2566698494 FusedOutput12 6024;
BA_ "SPN" SG_ 2566698494 FusedOutput13 6031;
BA_ "SPN" SG_ 2566698494 FusedOutput14 6030;
BA_ "SPN" SG_ 2566698494 FusedOutput15 6029;
BA_ "SPN" SG_ 2566698494 FusedOutput16 6028;
BA_ "SPN" SG_ 2566698494 FusedOutput17 6035;
BA_ "SPN" SG_ 2566698494 FusedOutput18 6034;
BA_ "SPN" SG_ 2566698494 FusedOutput19 6033;
BA_ "SPN" SG_ 2566698494 FusedOutput2 6018;
BA_ "SPN" SG_ 2566698494 FusedOutput20 6032;
BA_ "SPN" SG_ 2566698494 FusedOutput21 6039;
BA_ "SPN" SG_ 2566698494 FusedOutput22 6038;
BA_ "SPN" SG_ 2566698494 FusedOutput23 6037;
BA_ "SPN" SG_ 2566698494 FusedOutput24 6036;
BA_ "SPN" SG_ 2566698494 FusedOutput25 6043;
BA_ "SPN" SG_ 2566698494 FusedOutput26 6042;
BA_ "SPN" SG_ 2566698494 FusedOutput27 6041;
BA_ "SPN" SG_ 2566698494 FusedOutput28 6040;
BA_ "SPN" SG_ 2566698494 FusedOutput29 6047;
BA_ "SPN" SG_ 2566698494 FusedOutput3 6017;
BA_ "SPN" SG_ 2566698494 FusedOutput30 6046;
BA_ "SPN" SG_ 2566698494 FusedOutput31 6045;
BA_ "SPN" SG_ 2566698494 FusedOutput32 6044;
BA_ "SPN" SG_ 2566698494 FusedOutput4 6016;
BA_ "SPN" SG_ 2566698494 FusedOutput5 6023;
BA_ "SPN" SG_ 2566698494 FusedOutput6 6022;
BA_ "SPN" SG_ 2566698494 FusedOutput7 6021;
BA_ "SPN" SG_ 2566698494 FusedOutput8 6020;
BA_ "SPN" SG_ 2566698494 FusedOutput9 6027;
BA_ "SPN" SG_ 2566698750 SLIBatteryPackCapacity 5982;
BA_ "SPN" SG_ 2566698750 SLIBatteryPackHealth 5983;
BA_ "SPN" SG_ 2566698750 SLIBatteryPackStateofCharge 5981;
BA_ "SPN" SG_ 2566698750 SLICrnkngPrdtdMnmmBttrVltg 7497;
BA_ "SPN" SG_ 2566699006 HrdBttrPkRmnngChrg 5464;
BA_ "SPN" SG_ 2566699006 HrdSstmEngnStpStrtRmnngPrntg 8558;
BA_ "SPN" SG_ 2566699006 HrdPrplsnMdMxmmSpdSttng 9708;
BA_ "SPN" SG_ 2566699006 HrdPrplsnMdRmnngDstn 9709;
BA_ "SPN" SG_ 2566699262 Atttt2DsPttFtTtNxtAtvRt 5979;
BA_ "SPN" SG_ 2566699262 Atttt2SCRSstTSLstSstCEvt 6948;
BA_ "SPN" SG_ 2566699518 Atttt1DsPttFtTtNxtAtvRt 5978;
BA_ "SPN" SG_ 2566699518 Atttt1SCRSstTSLstSstCEvt 6941;
BA_ "SPN" SG_ 2566699774 Atttt2DsExstFdCtMd1PwSpp1 5968;
BA_ "SPN" SG_ 2566699774 Atttt2DsExstFdCtMd1PwSpp2 6310;
BA_ "SPN" SG_ 2566699774 Atttt2DsExstFdCtMd1RCt 5967;
BA_ "SPN" SG_ 2566699774 Atttt2DsExstFdCtMd2PwSpp1 7533;
BA_ "SPN" SG_ 2566699774 Atttt2DsExstFdCtMd2PwSpp2 7534;
BA_ "SPN" SG_ 2566699774 Atttt2DsExstFdCtMd2RCt 7532;
BA_ "SPN" SG_ 2566699774 Atttt2DsExstFdCtMdCtB 8483;
BA_ "SPN" SG_ 2566700030 Atttt1DsExstFdCtMd1PwSpp1 5966;
BA_ "SPN" SG_ 2566700030 Atttt1DsExstFdCtMd1PwSpp2 6309;
BA_ "SPN" SG_ 2566700030 Atttt1DsExstFdCtMd1RCt 5965;
BA_ "SPN" SG_ 2566700030 Atttt1DsExstFdCtMd2PwSpp1 7522;
BA_ "SPN" SG_ 2566700030 Atttt1DsExstFdCtMd2PwSpp2 7523;
BA_ "SPN" SG_ 2566700030 Atttt1DsExstFdCtMd2RCt 7521;
BA_ "SPN" SG_ 2566700030 Atttt1DsExstFdCtMdCtB 7417;
BA_ "SPN" SG_ 2566700286 Aftrtrtmnt2TtlDslExhstFldUsd 5964;
BA_ "SPN" SG_ 2566700542 Aftrtrtmnt1TtlDslExhstFldUsd 5963;
BA_ "SPN" SG_ 2566700542 AftrtrtmntTrpDslExhstFld 6563;
BA_ "SPN" SG_ 2566701566 TransmissionClutch2Pressure 5937;
BA_ "SPN" SG_ 2566701566 TrnsmssnOlTrnsmssnClrOtltTmprtr 5938;
BA_ "SPN" SG_ 2566701822 ExtrnlEnrgSrCnntnStts 7898;
BA_ "SPN" SG_ 2566701822 HrdPrplsnMdTrnstnStts 7897;
BA_ "SPN" SG_ 2566701822 HrdSstmEltrAltrntrIndtr 7451;
BA_ "SPN" SG_ 2566701822 HrdSstmHghVltgExpsrIndtr 7454;
BA_ "SPN" SG_ 2566701822 HrdSstmIntlztnIndtr 7453;
BA_ "SPN" SG_ 2566701822 HrdSstmMtrOvrspdAdlAlrm 7450;
BA_ "SPN" SG_ 2566701822 HrdSstmMtrOvrspdIndtr 7449;
BA_ "SPN" SG_ 2566701822 HrdSstmPrplsnDslStts 8267;
BA_ "SPN" SG_ 2566701822 HrdSstmRgnrtvBrkngIndtr 7452;
BA_ "SPN" SG_ 2566701822 HybridPropulsionModeStatus 7896;
BA_ "SPN" SG_ 2566701822 HybridSystemEngineAssistStatus 7418;
BA_ "SPN" SG_ 2566701822 HybridSystemOBDRelatedDTCStatus 6810;
BA_ "SPN" SG_ 2566701822 HybridSystemOverheatIndicator 5873;
BA_ "SPN" SG_ 2566701822 HybridSystemServiceIndicator 7448;
BA_ "SPN" SG_ 2566701822 HybridSystemStopIndicator 5874;
BA_ "SPN" SG_ 2566701822 HybridSystemWarningIndicator 5872;
BA_ "SPN" SG_ 2566701822 PropulsionSystemActive 7315;
BA_ "SPN" SG_ 2566701822 StoredEnergySourceLevel 7895;
BA_ "SPN" SG_ 2566701822 StrdEnrgSrInrsngMdAllwd 7894;
BA_ "SPN" SG_ 2566701822 StrdEnrgSrOnlMdAllwd 7893;
BA_ "SPN" SG_ 2566702078 SupplyGasMethanePercentage 5867;
BA_ "SPN" SG_ 2566702334 Aftrtrtmnt2SCRIntrmdtTmprtr 5864;
BA_ "SPN" SG_ 2566702334 Atttt2SCRItdtTptPFMI 5865;
BA_ "SPN" SG_ 2566702590 Aftrtrtmnt1SCRIntrmdtTmprtr 5862;
BA_ "SPN" SG_ 2566702590 Atttt1SCRItdtTptPFMI 5863;
BA_ "SPN" SG_ 2566703358 EngineDualFuelMode 6791;
BA_ "SPN" SG_ 2566703358 EngineFuelingInhibitAllowed 5795;
BA_ "SPN" SG_ 2566703358 EngnFlngDsrdRqstCnt 6897;
BA_ "SPN" SG_ 2566703358 EngnFlngInhtPrvntdRsn 5866;
BA_ "SPN" SG_ 2566703358 EngnFlngInhtPrvntdRsnExtnsn 8145;
BA_ "SPN" SG_ 2566703358 EngnFlngInhtRqstCnt 6896;
BA_ "SPN" SG_ 2566703358 EngnGsSstttnFlPrntg 6333;
BA_ "SPN" SG_ 2566703358 EngnPrttnDrtOvrrdStts 9174;
BA_ "SPN" SG_ 2566703358 FeedbackEngineFuelingState 5794;
BA_ "SPN" SG_ 2566703358 SrAddrssfCntrllngDvfrFlngStt 6307;
BA_ "SPN" SG_ 2566703358 RemainingEngineMotoringTime 12857;
BA_ "SPN" SG_ 2566703358 EnginePerformanceBiasLevel 10297;
BA_ "SPN" SG_ 2566703358 MinimumEngineMotoringSpeed 12858;
BA_ "SPN" SG_ 2566703614 EngineFuelValve1Temperature 5785;
BA_ "SPN" SG_ 2566703614 EngineFuelValve2Temperature 5786;
BA_ "SPN" SG_ 2566703614 EngineThrottleValve1Position2 6650;
BA_ "SPN" SG_ 2566703614 EngineThrottleValve1Temperature 5783;
BA_ "SPN" SG_ 2566703614 EngineThrottleValve2Temperature 5784;
BA_ "SPN" SG_ 2566703614 EngnFlRkFlSpplTmprtr 7314;
BA_ "SPN" SG_ 2566703614 EngnTrhrgrWstgtAttr2Tmprtr 5787;
BA_ "SPN" SG_ 2566703870 EExstGsRt2Att1TptStts 5774;
BA_ "SPN" SG_ 2566703870 EExstGsRt2Att2TptStts 5778;
BA_ "SPN" SG_ 2566703870 EngnExhstGsRrltn2Attr1DsrdPstn 5776;
BA_ "SPN" SG_ 2566703870 EngnExhstGsRrltn2Attr1OprtnStts 5781;
BA_ "SPN" SG_ 2566703870 EngnExhstGsRrltn2Attr1PrlmnrFMI 5773;
BA_ "SPN" SG_ 2566703870 EngnExhstGsRrltn2Attr1Tmprtr 5775;
BA_ "SPN" SG_ 2566703870 EngnExhstGsRrltn2Attr2DsrdPstn 5780;
BA_ "SPN" SG_ 2566703870 EngnExhstGsRrltn2Attr2OprtnStts 5782;
BA_ "SPN" SG_ 2566703870 EngnExhstGsRrltn2Attr2PrlmnrFMI 5777;
BA_ "SPN" SG_ 2566703870 EngnExhstGsRrltn2Attr2Tmprtr 5779;
BA_ "SPN" SG_ 2566704126 EExstGsRt1Att1TptStts 5764;
BA_ "SPN" SG_ 2566704126 EExstGsRt1Att2TptStts 5768;
BA_ "SPN" SG_ 2566704126 EngnExhstGsRrltn1Attr1DsrdPstn 5766;
BA_ "SPN" SG_ 2566704126 EngnExhstGsRrltn1Attr1OprtnStts 5771;
BA_ "SPN" SG_ 2566704126 EngnExhstGsRrltn1Attr1PrlmnrFMI 5763;
BA_ "SPN" SG_ 2566704126 EngnExhstGsRrltn1Attr1Tmprtr 5765;
BA_ "SPN" SG_ 2566704126 EngnExhstGsRrltn1Attr2DsrdPstn 5770;
BA_ "SPN" SG_ 2566704126 EngnExhstGsRrltn1Attr2OprtnStts 5772;
BA_ "SPN" SG_ 2566704126 EngnExhstGsRrltn1Attr2PrlmnrFMI 5767;
BA_ "SPN" SG_ 2566704126 EngnExhstGsRrltn1Attr2Tmprtr 5769;
BA_ "SPN" SG_ 2566704382 Aftrtrtmnt1Otlt1GsSnsrPwrSppl 5759;
BA_ "SPN" SG_ 2566704382 Aftrtrtmnt1Otlt2GsSnsrPwrSppl 8147;
BA_ "SPN" SG_ 2566704382 Aftrtrtmnt2Otlt1GsSnsrPwrSppl 5761;
BA_ "SPN" SG_ 2566704382 EngnExhst1GsSnsr1PwrSppl 5758;
BA_ "SPN" SG_ 2566704382 EngnExhst2GsSnsr1PwrSppl 5760;
BA_ "SPN" SG_ 2566704382 EngnExhst1GsSnsr2PwrSppl 8146;
BA_ "SPN" SG_ 2566705150 Atttt1OttNOxSsSdssT 5709;
BA_ "SPN" SG_ 2566705150 Atttt2OttNOxSsSdssT 5711;
BA_ "SPN" SG_ 2566705150 EngnExhst1NOxSnsrSlfdgnssTrggr 5710;
BA_ "SPN" SG_ 2566705150 EngnExhst2NOxSnsrSlfdgnssTrggr 5712;
BA_ "SPN" SG_ 2566705406 Aftrtrtmnt1PrtltSnsr 5835;
BA_ "SPN" SG_ 2566705406 Aftrtrtmnt1PrtltSnsrCrrnt 7393;
BA_ "SPN" SG_ 2566705406 Aftrtrtmnt2PrtltSnsr 5836;
BA_ "SPN" SG_ 2566706686 Aftrtrtmnt1DslExhstFldPmpHtr 5706;
BA_ "SPN" SG_ 2566706686 Atttt1DsExstFdDsUt1HtR 5746;
BA_ "SPN" SG_ 2566706686 Atttt1DsExstFdPp2MtSpd 7461;
BA_ "SPN" SG_ 2566706686 Atttt1DsExstFdPpPwSpp 8474;
BA_ "SPN" SG_ 2566706686 AttttDsExstFdTsPpPR 13361;
BA_ "SPN" SG_ 2566706942 Atttt1DsPttFt2StSsAssFq3 5652;
BA_ "SPN" SG_ 2566706942 Atttt1DsPttFt2StSsAssFq4 5654;
BA_ "SPN" SG_ 2566706942 Atttt1DsPttFt2StSsFq3StS 5653;
BA_ "SPN" SG_ 2566706942 Atttt1DsPttFt2StSsFq4StS 5655;
BA_ "SPN" SG_ 2566707198 Atttt1DsPttFt2StSsAssFq1 5648;
BA_ "SPN" SG_ 2566707198 Atttt1DsPttFt2StSsAssFq2 5650;
BA_ "SPN" SG_ 2566707198 Atttt1DsPttFt2StSsFq1StS 5649;
BA_ "SPN" SG_ 2566707198 Atttt1DsPttFt2StSsFq2StS 5651;
BA_ "SPN" SG_ 2566707454 Atttt1DsPttFt2StSsAssRqstFq1 5644;
BA_ "SPN" SG_ 2566707454 Atttt1DsPttFt2StSsAssRqstFq2 5645;
BA_ "SPN" SG_ 2566707454 Atttt1DsPttFt2StSsAssRqstFq3 5646;
BA_ "SPN" SG_ 2566707454 Atttt1DsPttFt2StSsAssRqstFq4 5647;
BA_ "SPN" SG_ 2566707710 Atttt1DsPttFt1StSsAssFq3 5640;
BA_ "SPN" SG_ 2566707710 Atttt1DsPttFt1StSsAssFq4 5642;
BA_ "SPN" SG_ 2566707710 Atttt1DsPttFt1StSsFq3StS 5641;
BA_ "SPN" SG_ 2566707710 Atttt1DsPttFt1StSsFq4StS 5643;
BA_ "SPN" SG_ 2566707966 Atttt1DsPttFt1StSsAssFq1 5636;
BA_ "SPN" SG_ 2566707966 Atttt1DsPttFt1StSsAssFq2 5638;
BA_ "SPN" SG_ 2566707966 Atttt1DsPttFt1StSsFq1StS 5637;
BA_ "SPN" SG_ 2566707966 Atttt1DsPttFt1StSsFq2StS 5639;
BA_ "SPN" SG_ 2566708222 Atttt1DsPttFt1StSsAssRqstFq1 5632;
BA_ "SPN" SG_ 2566708222 Atttt1DsPttFt1StSsAssRqstFq2 5633;
BA_ "SPN" SG_ 2566708222 Atttt1DsPttFt1StSsAssRqstFq3 5634;
BA_ "SPN" SG_ 2566708222 Atttt1DsPttFt1StSsAssRqstFq4 5635;
BA_ "SPN" SG_ 2566708478 AdptvCrsCntrlRdnssStts 5606;
BA_ "SPN" SG_ 2566708478 AEBSreadinessstate 6208;
BA_ "SPN" SG_ 2566708478 CrsCntrlDrvrCnlltnStts 7836;
BA_ "SPN" SG_ 2566708478 CrsCntrlStSpdHghRsltn 6809;
BA_ "SPN" SG_ 2566708478 CruiseControlSpeed 7319;
BA_ "SPN" SG_ 2566708478 CruiseControlSystemCommandState 5607;
BA_ "SPN" SG_ 2566708478 PrdtvCrsCntrlStSpdOffstStts 7318;
BA_ "SPN" SG_ 2566708478 SAddssCtDvDsCsCt 5608;
BA_ "SPN" SG_ 2566708478 SAddssCtDvPsCsCt 5609;
BA_ "SPN" SG_ 2566708734 Aftrtrtmnt2SndrArAsltPrssr 5590;
BA_ "SPN" SG_ 2566708990 Aftrtrtmnt1SndrArAsltPrssr 5589;
BA_ "SPN" SG_ 2566708990 OprtrIndmntOvrrdRnwlRqrd 10154;
BA_ "SPN" SG_ 2566709246 EFSppPpItAstPssExtddR 7472;
BA_ "SPN" SG_ 2566709246 EngineFuelFilterDegradation 5584;
BA_ "SPN" SG_ 2566709246 EngineFuelReturnPressure 6816;
BA_ "SPN" SG_ 2566709246 EngnFlDlvrAsltPrssr 5578;
BA_ "SPN" SG_ 2566709246 EngnFltrdFlDlvrAsltPrssr 5580;
BA_ "SPN" SG_ 2566709246 EngnFltrdFlDlvrPrssr 5579;
BA_ "SPN" SG_ 2566709246 EngnThrttlVlv2DffrntlPrssr 7595;
BA_ "SPN" SG_ 2566709502 Aftertreatment1FuelMassRate 5503;
BA_ "SPN" SG_ 2566709502 Aftertreatment2FuelMassRate 5834;
BA_ "SPN" SG_ 2566709502 Atttt1DsPttFtItTptStPt 5501;
BA_ "SPN" SG_ 2566709502 EngineUnburnedFuelPercentage 5502;
BA_ "SPN" SG_ 2566709758 EngineDieselFuelDemandRate 7596;
BA_ "SPN" SG_ 2566709758 EngineFuelRateHighResolution 1600;
BA_ "SPN" SG_ 2566710014 SpplmntlFnCntrllrECUTmprtr 5561;
BA_ "SPN" SG_ 2566710014 SpplmntlFnCntrllrTmprtrStts 5559;
BA_ "SPN" SG_ 2566710014 SupplementalFanCurrent 5563;
BA_ "SPN" SG_ 2566710014 SupplementalFanDirectionStatus 5557;
BA_ "SPN" SG_ 2566710014 SupplementalFanDriveStatus 5560;
BA_ "SPN" SG_ 2566710014 SupplementalFanEnableStatus 5556;
BA_ "SPN" SG_ 2566710014 SupplementalFanPower 5564;
BA_ "SPN" SG_ 2566710014 SupplementalFanSpeed 5562;
BA_ "SPN" SG_ 2566710014 SupplementalFanVelocityStatus 5558;
BA_ "SPN" SG_ 2566710526 EngineFuelDensity 5538;
BA_ "SPN" SG_ 2566710526 EngineFuelDynamicViscosity 5537;
BA_ "SPN" SG_ 2566710526 EngnFl1Tmprtr1HghRsltn 5540;
BA_ "SPN" SG_ 2566710526 EngnFlDltrtHghRsltn 5539;
BA_ "SPN" SG_ 2566710782 HdrlOlRltvDltrtHghRsltn 5535;
BA_ "SPN" SG_ 2566710782 HdrlOlTmprtrHghRsltn 5536;
BA_ "SPN" SG_ 2566710782 HydraulicOilDensity 5534;
BA_ "SPN" SG_ 2566710782 HydraulicOilDynamicViscosity 5533;
BA_ "SPN" SG_ 2566711038 LubricationCycleModeLockStatus 5515;
BA_ "SPN" SG_ 2566711038 LubricationCycleModeStatus 5516;
BA_ "SPN" SG_ 2566711038 LubricationOperationModeStatus 5517;
BA_ "SPN" SG_ 2566711038 LubricationPumpEnableStatus 5518;
BA_ "SPN" SG_ 2566711038 LubricationReservoirLevel 5519;
BA_ "SPN" SG_ 2566711038 LubricationTimingCycleStatus 5520;
BA_ "SPN" SG_ 2566711294 EngnFrtnPrntTrqAtIdlPnt1 5471;
BA_ "SPN" SG_ 2566711294 EngnFrtnPrntTrqPnt2 5472;
BA_ "SPN" SG_ 2566711294 EngnFrtnPrntTrqPnt3 5473;
BA_ "SPN" SG_ 2566711294 EngnFrtnPrntTrqPnt4 5474;
BA_ "SPN" SG_ 2566711294 EngnFrtnPrntTrqPnt5 5475;
BA_ "SPN" SG_ 2566711294 EngnFrtnPrntTrqPnt6 5476;
BA_ "SPN" SG_ 2566711294 EngnFrtnPrntTrqPnt7 5477;
BA_ "SPN" SG_ 2566711550 ItVvAttSstOPss1SdCt 5499;
BA_ "SPN" SG_ 2566711550 ItVvAttSstOPss2SdCt 5500;
BA_ "SPN" SG_ 2566711806 Armrest1Switch1 1503;
BA_ "SPN" SG_ 2566711806 Armrest1Switch2 5492;
BA_ "SPN" SG_ 2566711806 Armrest2Switch1 5493;
BA_ "SPN" SG_ 2566711806 Armrest2Switch2 5494;
BA_ "SPN" SG_ 2566712318 Aftrtrtmnt2NOxAdsrrDslftnStts 5462;
BA_ "SPN" SG_ 2566712318 Aftrtrtmnt2NOxAdsrrRgnrtnStts 5460;
BA_ "SPN" SG_ 2566712574 Aftrtrtmnt1NOxAdsrrDslftnStts 5461;
BA_ "SPN" SG_ 2566712574 Aftrtrtmnt1NOxAdsrrRgnrtnStts 5459;
BA_ "SPN" SG_ 2566712830 Atttt2WUpDsOxdtCtstItTpt 5315;
BA_ "SPN" SG_ 2566712830 Atttt2WUpDsOxdtCtstOttTpt 5316;
BA_ "SPN" SG_ 2566713598 EngnFlFltrStnSdDgrdtn 6716;
BA_ "SPN" SG_ 2566713598 EngnFlFltrStnSdIntkAsltPrssr 5417;
BA_ "SPN" SG_ 2566713598 FuelTankTransferPump 4010;
BA_ "SPN" SG_ 2566713598 FuelTankTransferPumpPressure 7395;
BA_ "SPN" SG_ 2566713598 EngineFuelPumpIntakeOilPressure 9648;
BA_ "SPN" SG_ 2566713854 EExstPssRtCtOptStts 5628;
BA_ "SPN" SG_ 2566713854 EngnExhstBnk1PrssrRgltrPstn 5625;
BA_ "SPN" SG_ 2566713854 EngnExhstPrssrAttr1DsrdPstn 5789;
BA_ "SPN" SG_ 2566713854 EngnExhstPrssrAttr1Tmprtr 5790;
BA_ "SPN" SG_ 2566713854 EngnExhstPrssrRgltrPrlmnrFMI 5626;
BA_ "SPN" SG_ 2566713854 EngnExhstPrssrRgltrTmprtrStts 5627;
BA_ "SPN" SG_ 2566713854 EngnTrhrgrWstgtAttr1OprtnStts 5451;
BA_ "SPN" SG_ 2566713854 EngnTrhrgrWstgtAttr1Tmprtr 5788;
BA_ "SPN" SG_ 2566713854 EngnTrhrgrWstgtAttr2OprtnStts 5452;
BA_ "SPN" SG_ 2566713854 EngnTrhrgrWstgtAttr2PrlmnrFMI 5384;
BA_ "SPN" SG_ 2566713854 EngnTrhrgrWstgtAttr2TmprtrStts 5385;
BA_ "SPN" SG_ 2566714110 EngineFuelValve1OperationStatus 5447;
BA_ "SPN" SG_ 2566714110 EngineFuelValve1PreliminaryFMI 5380;
BA_ "SPN" SG_ 2566714110 EngineFuelValve2OperationStatus 5448;
BA_ "SPN" SG_ 2566714110 EngineFuelValve2PreliminaryFMI 5382;
BA_ "SPN" SG_ 2566714110 EngnDsrdThrttlVlv1Pstn 5374;
BA_ "SPN" SG_ 2566714110 EngnDsrdThrttlVlv2Pstn 5377;
BA_ "SPN" SG_ 2566714110 EngnFlVlv1TmprtrStts 5381;
BA_ "SPN" SG_ 2566714110 EngnFlVlv2TmprtrStts 5383;
BA_ "SPN" SG_ 2566714110 EngnThrttlVlv1OprtnStts 5445;
BA_ "SPN" SG_ 2566714110 EngnThrttlVlv1PrlmnrFMI 5375;
BA_ "SPN" SG_ 2566714110 EngnThrttlVlv1TmprtrStts 5376;
BA_ "SPN" SG_ 2566714110 EngnThrttlVlv2OprtnStts 5446;
BA_ "SPN" SG_ 2566714110 EngnThrttlVlv2PrlmnrFMI 5378;
BA_ "SPN" SG_ 2566714110 EngnThrttlVlv2Tmprtrstts 5379;
BA_ "SPN" SG_ 2566714366 EngnTrhrgrCmprssrBpssAttr2Pstn 5388;
BA_ "SPN" SG_ 2566714366 ETCpssBpssAtt1OptStts 5449;
BA_ "SPN" SG_ 2566714366 ETCpssBpssAtt1Tpt 5791;
BA_ "SPN" SG_ 2566714366 ETCpssBpssAtt2DsdPst 5389;
BA_ "SPN" SG_ 2566714366 ETCpssBpssAtt2OptStts 5450;
BA_ "SPN" SG_ 2566714366 ETCpssBpssAtt2Tpt 5792;
BA_ "SPN" SG_ 2566714366 ETCpssBpssAtt2TptStts 5391;
BA_ "SPN" SG_ 2566714366 ETpssBpssAtt2PFMI 5390;
BA_ "SPN" SG_ 2566714622 EngnChrgArClr2AmntArTmprtr 5291;
BA_ "SPN" SG_ 2566714622 EngnChrgArClr2Effn 5292;
BA_ "SPN" SG_ 2566714622 EngnChrgArClr2IntkTmprtr 5289;
BA_ "SPN" SG_ 2566714622 EngnChrgArClr2OtltTmprtr 5290;
BA_ "SPN" SG_ 2566714878 EngnChrgArClr2PrlrEffn 5288;
BA_ "SPN" SG_ 2566714878 EngnChrgArClr2PrlrIntkTmprtr 5286;
BA_ "SPN" SG_ 2566714878 EngnChrgArClr2PrlrOtltTmprtr 5287;
BA_ "SPN" SG_ 2566715134 EngnChrgArClr1AmntArTmprtr 5284;
BA_ "SPN" SG_ 2566715134 EngnChrgArClr1Effn 5285;
BA_ "SPN" SG_ 2566715134 EngnChrgArClr1IntkTmprtr 5283;
BA_ "SPN" SG_ 2566715390 EngnChrgArClr1PrlrEffn 5282;
BA_ "SPN" SG_ 2566715390 EngnChrgArClr1PrlrIntkTmprtr 5280;
BA_ "SPN" SG_ 2566715390 EngnChrgArClr1PrlrOtltTmprtr 5281;
BA_ "SPN" SG_ 2566715646 Atttt2DsPttFtStSM 5271;
BA_ "SPN" SG_ 2566715646 Atttt2DsPttFtStSMx 5270;
BA_ "SPN" SG_ 2566715646 Atttt2DsPttFtStSStddDvt 5269;
BA_ "SPN" SG_ 2566715902 Atttt1DsPttFtStSM 5268;
BA_ "SPN" SG_ 2566715902 Atttt1DsPttFtStSMx 5267;
BA_ "SPN" SG_ 2566715902 Atttt1DsPttFtStSStddDvt 5266;
BA_ "SPN" SG_ 2566717438 EngnExhstGsRrltn2MxrIntkTmprtr 5256;
BA_ "SPN" SG_ 2566717438 EngnExhstGsRrltn2Tmprtr 5255;
BA_ "SPN" SG_ 2566717950 LowVoltageDisconnectTemperature 5148;
BA_ "SPN" SG_ 2566717950 LwVltgDsnntCrrntOprtngMd 5143;
BA_ "SPN" SG_ 2566717950 LwVltgDsnntMnlCnntStt 5142;
BA_ "SPN" SG_ 2566717950 LwVltgDsnntMnlDsnntStt 5141;
BA_ "SPN" SG_ 2566717950 LwVltgDsnntOtpt1Stt 5146;
BA_ "SPN" SG_ 2566717950 LwVltgDsnntOtpt2Stt 5145;
BA_ "SPN" SG_ 2566717950 LwVltgDsnntOtpt3Stt 5144;
BA_ "SPN" SG_ 2566717950 LwVltgDsnntVtOtptStt 5147;
BA_ "SPN" SG_ 2566718718 HillHolderLampData 1848;
BA_ "SPN" SG_ 2566718718 VehicleAirPressureLowLampData 5106;
BA_ "SPN" SG_ 2566718718 VehicleBatteryChargingLampData 5108;
BA_ "SPN" SG_ 2566718718 VehicleFuelLevelLowLampData 5105;
BA_ "SPN" SG_ 2566718718 VhlBttrVltgLwLmpDt 5104;
BA_ "SPN" SG_ 2566718718 VhlHVACRrltnLmpDt 5107;
BA_ "SPN" SG_ 2566718718 VhlLmtdPrfrmnMdLmpDt 10296;
BA_ "SPN" SG_ 2566718718 PrimaryAirPressureLowLampData 13121;
BA_ "SPN" SG_ 2566718718 SecondaryAirPressureLowLampData 13122;
BA_ "SPN" SG_ 2566718718 OptionalLamp1Data 13123;
BA_ "SPN" SG_ 2566718718 OptionalLamp2Data 13124;
BA_ "SPN" SG_ 2566718718 OptionalLamp3Data 13125;
BA_ "SPN" SG_ 2566718718 OptionalLamp4Data 13126;
BA_ "SPN" SG_ 2566718718 OptionalLamp5Data 13127;
BA_ "SPN" SG_ 2566718718 OptionalLamp6Data 13128;
BA_ "SPN" SG_ 2566718974 CmprssnBrkEnlSwthIndtrLmpDt 5098;
BA_ "SPN" SG_ 2566718974 EngineAmberWarningLampData 5094;
BA_ "SPN" SG_ 2566718974 EngineBrakeActiveLampData 5097;
BA_ "SPN" SG_ 2566718974 EngineCoolantLevelLowLampData 5101;
BA_ "SPN" SG_ 2566718974 EngineOilPressureLowLampData 5099;
BA_ "SPN" SG_ 2566718974 EngineProtectLampData 5093;
BA_ "SPN" SG_ 2566718974 EngineRedStopLampData 5095;
BA_ "SPN" SG_ 2566718974 EngineSpeedHighLampData 6711;
BA_ "SPN" SG_ 2566718974 EngineSpeedVeryHighLampData 6712;
BA_ "SPN" SG_ 2566718974 EngineWaitToStartLampData 5416;
BA_ "SPN" SG_ 2566718974 EngnArFltrRstrtnLmpDt 5103;
BA_ "SPN" SG_ 2566718974 EngnClntTmprtrHghLmpDt 5100;
BA_ "SPN" SG_ 2566718974 EngnCntrlMdl1RdfrUsLmpDt 6202;
BA_ "SPN" SG_ 2566718974 EngnCntrlMdl2RdfrUsLmpDt 6203;
BA_ "SPN" SG_ 2566718974 EngnCntrlMdl3RdfrUsLmpDt 6204;
BA_ "SPN" SG_ 2566718974 EngnFlFltrRstrtdLmpDt 5470;
BA_ "SPN" SG_ 2566718974 EngnIdlMngmntAtvLmpDt 5102;
BA_ "SPN" SG_ 2566718974 OBDMalfunctionIndicatorLampData 5096;
BA_ "SPN" SG_ 2566718974 VhlAlrtnRtLmtLmpDt 6900;
BA_ "SPN" SG_ 2566718974 EngnStpStrtAtmtStpAtvLmpDt 9680;
BA_ "SPN" SG_ 2566718974 EngnStpStrtAtmtStrtFldLmpDt 9681;
BA_ "SPN" SG_ 2566718974 EngineStopStartEnabledLampData 9682;
BA_ "SPN" SG_ 2566718974 EngnOlTmprtrHghLmpDt 13118;
BA_ "SPN" SG_ 2566718974 EngnFlTmprtrHghLmpDt 13119;
BA_ "SPN" SG_ 2566718974 EngnIntrlrTmprtrHghLmpDt 13120;
BA_ "SPN" SG_ 2566718974 EngineAirShutoffLampData 13380;
BA_ "SPN" SG_ 2566719230 HillHolderLampCommand 1847;
BA_ "SPN" SG_ 2566719230 VehicleFuelLevelLowLampCommand 5088;
BA_ "SPN" SG_ 2566719230 VhlArPrssrLwLmpCmmnd 5089;
BA_ "SPN" SG_ 2566719230 VhlBttrChrgngLmpCmmnd 5091;
BA_ "SPN" SG_ 2566719230 VhlBttrVltgLwLmpCmmnd 5087;
BA_ "SPN" SG_ 2566719230 VhlHVACRrltnLmpCmmnd 5090;
BA_ "SPN" SG_ 2566719230 VhlLmtdPrfrmnMdLmpCmmnd 10295;
BA_ "SPN" SG_ 2566719230 PrmrArPrssrLwLmpCmmnd 13108;
BA_ "SPN" SG_ 2566719230 SndrArPrssrLwLmpCmmnd 13109;
BA_ "SPN" SG_ 2566719230 OptionalLamp1Command 13110;
BA_ "SPN" SG_ 2566719230 OptionalLamp2Command 13111;
BA_ "SPN" SG_ 2566719230 OptionalLamp3Command 13112;
BA_ "SPN" SG_ 2566719230 OptionalLamp4Command 13113;
BA_ "SPN" SG_ 2566719230 OptionalLamp5Command 13114;
BA_ "SPN" SG_ 2566719230 OptionalLamp6Command 13115;
BA_ "SPN" SG_ 2566719486 CmprssnBrkEnlSwthIndtrLmpCmmnd 3987;
BA_ "SPN" SG_ 2566719486 EngineAmberWarningLampCommand 5078;
BA_ "SPN" SG_ 2566719486 EngineBrakeActiveLampCommand 5081;
BA_ "SPN" SG_ 2566719486 EngineOilPressureLowLampCommand 5082;
BA_ "SPN" SG_ 2566719486 EngineProtectLampCommand 5077;
BA_ "SPN" SG_ 2566719486 EngineRedStopLampCommand 5079;
BA_ "SPN" SG_ 2566719486 EngineSpeedHighLampCommand 6709;
BA_ "SPN" SG_ 2566719486 EngineSpeedVeryHighLampCommand 6710;
BA_ "SPN" SG_ 2566719486 EngnArFltrRstrtnLmpCmmnd 5086;
BA_ "SPN" SG_ 2566719486 EngnClntLvlLwLmpCmmnd 5084;
BA_ "SPN" SG_ 2566719486 EngnClntTmprtrHghLmpCmmnd 5083;
BA_ "SPN" SG_ 2566719486 EngnCntrlMdl1RdfrUsLmpCmmnd 6205;
BA_ "SPN" SG_ 2566719486 EngnCntrlMdl2RdfrUsLmpCmmnd 6206;
BA_ "SPN" SG_ 2566719486 EngnCntrlMdl3RdfrUsLmpCmmnd 6207;
BA_ "SPN" SG_ 2566719486 EngnFlFltrRstrtdLmpCmmnd 5469;
BA_ "SPN" SG_ 2566719486 EngnIdlMngmntAtvLmpCmmnd 5085;
BA_ "SPN" SG_ 2566719486 EngnIdlMngmntPndngEvntLmpCmmnd 9372;
BA_ "SPN" SG_ 2566719486 OBDMlfntnIndtrLmpCmmnd 5080;
BA_ "SPN" SG_ 2566719486 VhlAlrtnRtLmtLmpCmmnd 6899;
BA_ "SPN" SG_ 2566719486 EngnStpStrtAtmtStpAtvLmpCmmnd 9683;
BA_ "SPN" SG_ 2566719486 EngnStpStrtAtmtStrtFldLmpCmmnd 9684;
BA_ "SPN" SG_ 2566719486 EngnStpStrtEnldLmpCmmnd 9685;
BA_ "SPN" SG_ 2566719486 EngnOlTmprtrHghLmpCmmnd 13105;
BA_ "SPN" SG_ 2566719486 EngnFlTmprtrHghLmpCmmnd 13106;
BA_ "SPN" SG_ 2566719486 EngnIntrlrTmprtrHghLmpCmmnd 13107;
BA_ "SPN" SG_ 2566719486 EngineAirShutoffLampCommand 13379;
BA_ "SPN" SG_ 2566719998 EngineTripFuelHighResolution 5053;
BA_ "SPN" SG_ 2566719998 EngnTtlFlUsdHghRsltn 5054;
VAL_ 2566718718 VehicleBatteryChargingLampData 3 "NotAvailable" 2 "Error" 1 "LampActivated" 0 "LampDeactivated" ;
VAL_ 2566718718 VehicleFuelLevelLowLampData 3 "NotAvailable" 2 "Error" 1 "LampActivated" 0 "LampDeactivated" ;
VAL_ 2566718974 OBDMalfunctionIndicatorLampData 3 "NotAvailable" 2 "Error" 1 "LampActivated" 0 "LampDeactivated" ;
VAL_ 2566711550 ItVvAttSstOPss1SdCt 3 "notAvailable" 2 "reservedForSAEAssignment" 1 "on" 0 "off" ;
VAL_ 2566711550 ItVvAttSstOPss2SdCt 3 "notAvailable" 2 "reservedForSAEAssignment" 1 "on" 0 "off" ;
VAL_ 2566711806 Armrest1Switch1 3 "DontCare_TakeNoAction" 2 "Reserved" 1 "On" 0 "Off" ;
VAL_ 2566711806 Armrest1Switch2 3 "DontCare_TakeNoAction" 2 "Reserved" 1 "On" 0 "Off" ;
VAL_ 2566711806 Armrest2Switch1 3 "DontCare_TakeNoAction" 2 "Reserved" 1 "On" 0 "Off" ;
VAL_ 2566711806 Armrest2Switch2 3 "DontCare_TakeNoAction" 2 "Reserved" 1 "On" 0 "Off" ;
VAL_ 2566712318 Aftrtrtmnt2NOxAdsrrRgnrtnStts 3 "NotAvailable" 2 "ErrorIndicator" 1 "Active" 0 "Inactive" ;
VAL_ 2566712318 Aftrtrtmnt2NOxAdsrrDslftnStts 3 "NotAvailable" 2 "ErrorIndicator" 1 "Active" 0 "Inactive" ;
VAL_ 2566712574 Aftrtrtmnt1NOxAdsrrRgnrtnStts 3 "NotAvailable" 2 "ErrorIndicator" 1 "Active" 0 "Inactive" ;
VAL_ 2566712574 Aftrtrtmnt1NOxAdsrrDslftnStts 3 "NotAvailable" 2 "ErrorIndicator" 1 "Active" 0 "Inactive" ;
VAL_ 2566713854 EngnTrhrgrWstgtAttr2TmprtrStts 7 "NotAvailable" 6 "Error" 5 "NotDefined" 4 "LowMostSevere" 3 "LowLeastSevere" 2 "InRange" 1 "HighLeastSevere" 0 "HighMostSevere" ;
VAL_ 2566713854 EngnTrhrgrWstgtAttr1OprtnStts 14 "Error" 6 "1101ReservedForFutureAssignment" 5 "UnCtrlledShutdownActive" 4 "CtrlledShutdownActive" 3 "DerateActive" 2 "AlarmHighSeverity" 1 "Alarm" 0 "Normal" ;
VAL_ 2566713854 EngnTrhrgrWstgtAttr2OprtnStts 14 "Error" 6 "1101ReservedForFutureAssignment" 5 "UnCtrlledShutdownActive" 4 "CtrlledShutdownActive" 3 "DerateActive" 2 "AlarmHighSeverity" 1 "Alarm" 0 "Normal" ;
VAL_ 2566714110 EngnThrttlVlv1TmprtrStts 7 "NotAvailable" 6 "Error" 5 "NotDefined" 4 "LowMostSevere" 3 "LowLeastSevere" 2 "InRange" 1 "HighLeastSevere" 0 "HighMostSevere" ;
VAL_ 2566714110 EngnThrttlVlv2Tmprtrstts 7 "NotAvailable" 6 "Error" 5 "NotDefined" 4 "LowMostSevere" 3 "LowLeastSevere" 2 "InRange" 1 "HighLeastSevere" 0 "HighMostSevere" ;
VAL_ 2566714110 EngnFlVlv1TmprtrStts 7 "NotAvailable" 6 "Error" 5 "NotDefined" 4 "LowMostSevere" 3 "LowLeastSevere" 2 "InRange" 1 "HighLeastSevere" 0 "HighMostSevere" ;
VAL_ 2566714110 EngnFlVlv2TmprtrStts 7 "NotAvailable" 6 "Error" 5 "NotDefined" 4 "LowMostSevere" 3 "LowLeastSevere" 2 "InRange" 1 "HighLeastSevere" 0 "HighMostSevere" ;
VAL_ 2566714110 EngnThrttlVlv1OprtnStts 15 "NotAvailable" 14 "Error" 6 "1101ReservedForFutureAssignment" 5 "UnCtrlledShutdownActive" 4 "CtrlledShutdownActive" 3 "DerateActive" 2 "AlarmHighSeverity" 1 "Alarm" 0 "Normal" ;
VAL_ 2566714110 EngnThrttlVlv2OprtnStts 14 "Error" 6 "1101ReservedForFutureAssignment" 5 "UnCtrlledShutdownActive" 4 "CtrlledShutdownActive" 3 "DerateActive" 2 "AlarmHighSeverity" 1 "Alarm" 0 "Normal" ;
VAL_ 2566714110 EngineFuelValve1OperationStatus 14 "Error" 6 "1101ReservedForFutureAssignment" 5 "UnCtrlledShutdownActive" 4 "CtrlledShutdownActive" 3 "DerateActive" 2 "AlarmHighSeverity" 1 "Alarm" 0 "Normal" ;
VAL_ 2566714110 EngineFuelValve2OperationStatus 14 "Error" 6 "1101ReservedForFutureAssignment" 5 "UnCtrlledShutdownActive" 4 "CtrlledShutdownActive" 3 "DerateActive" 2 "AlarmHighSeverity" 1 "Alarm" 0 "Normal" ;
VAL_ 2566714366 ETCpssBpssAtt2TptStts 7 "NotAvailable" 6 "Error" 5 "NotDefined" 4 "LowMostSevere" 3 "LowLeastSevere" 2 "InRange" 1 "HighLeastSevere" 0 "HighMostSevere" ;
VAL_ 2566714366 ETCpssBpssAtt1OptStts 14 "Error" 6 "1101ReservedForFutureAssignment" 5 "UnCtrlledShutdownActive" 4 "CtrlledShutdownActive" 3 "DerateActive" 2 "AlarmHighSeverity" 1 "Alarm" 0 "Normal" ;
VAL_ 2566714366 ETCpssBpssAtt2OptStts 14 "Error" 6 "1101ReservedForFutureAssignment" 5 "UnCtrlledShutdownActive" 4 "CtrlledShutdownActive" 3 "DerateActive" 2 "AlarmHighSeverity" 1 "Alarm" 0 "Normal" ;
VAL_ 2566717950 LwVltgDsnntMnlDsnntStt 3 "NotInstalled" 2 "Error" 1 "InputOn" 0 "InputOff" ;
VAL_ 2566717950 LwVltgDsnntMnlCnntStt 3 "NotInstalled" 2 "Error" 1 "InputOn" 0 "InputOff" ;
VAL_ 2566717950 LwVltgDsnntCrrntOprtngMd 15 "NotAvailable" 10 "1110Reserved" 9 "ManualConnectViaHardwiredInput" 8 "MnalDisconnectViaHardwiredInput" 6 "0111Reserved" 5 "ManualConnectViaJ1939Rq" 4 "ManualDisconnectViaJ1939Rq" 1 "0011Reserved" 0 "Automatic" ;
VAL_ 2566717950 LwVltgDsnntOtpt3Stt 15 "NotAvailableNotInstalled" 14 "OutputFault" 5 "1101Reserved" 4 "ConnectPendingAlarmActive" 3 "DisconnectPendingAlarmActive" 2 "DscnnctAlrmExprdOtptOffDscnnctd" 1 "OutputOnConnected" 0 "OutputOffDisconnected" ;
VAL_ 2566717950 LwVltgDsnntOtpt2Stt 15 "NotAvailableNotInstalled" 14 "OutputFault" 5 "1101Reserved" 4 "ConnectPendingAlarmActive" 3 "DisconnectPendingAlarmActive" 2 "DscnnctAlrmExprdOtptOffDscnnctd" 1 "OutputOnConnected" 0 "OutputOffDisconnected" ;
VAL_ 2566717950 LwVltgDsnntOtpt1Stt 15 "NotAvailableNotInstalled" 14 "OutputFault" 5 "1101Reserved" 4 "ConnectPendingAlarmActive" 3 "DisconnectPendingAlarmActive" 2 "DscnnctAlrmExprdOtptOffDscnnctd" 1 "OutputOnConnected" 0 "OutputOffDisconnected" ;
VAL_ 2566717950 LwVltgDsnntVtOtptStt 15 "NotAvailableNotInstalled" 14 "OutputFault" 5 "1101Reserved" 4 "ConnectPendingAlarmActive" 3 "DisconnectPendingAlarmActive" 2 "DscnnctAlrmExprdOtptOffDscnnctd" 1 "OutputOnConnected" 0 "OutputOffDisconnected" ;
VAL_ 2566718718 VhlBttrVltgLwLmpDt 3 "NotAvailable" 2 "Error" 1 "LampActivated" 0 "LampDeactivated" ;
VAL_ 2566718718 VehicleAirPressureLowLampData 3 "NotAvailable" 2 "Error" 1 "LampActivated" 0 "LampDeactivated" ;
VAL_ 2566718718 VhlHVACRrltnLmpDt 3 "NotAvailable" 2 "Error" 1 "LampActivated" 0 "LampDeactivated" ;
VAL_ 2566718974 EngineProtectLampData 3 "NotAvailable" 2 "Error" 1 "LampActivated" 0 "LampDeactivated" ;
VAL_ 2566718974 EngineAmberWarningLampData 3 "NotAvailable" 2 "Error" 1 "LampActivated" 0 "LampDeactivated" ;
VAL_ 2566718974 EngineRedStopLampData 3 "NotAvailable" 2 "Error" 1 "LampActivated" 0 "LampDeactivated" ;
VAL_ 2566718974 EngineBrakeActiveLampData 3 "NotAvailable" 2 "Error" 1 "LampActivated" 0 "LampDeactivated" ;
VAL_ 2566718974 CmprssnBrkEnlSwthIndtrLmpDt 3 "NotAvailable" 2 "Error" 1 "LampActivated" 0 "LampDeactivated" ;
VAL_ 2566718974 EngineOilPressureLowLampData 3 "NotAvailable" 2 "Error" 1 "LampActivated" 0 "LampDeactivated" ;
VAL_ 2566718974 EngnClntTmprtrHghLmpDt 3 "NotAvailable" 2 "Error" 1 "LampActivated" 0 "LampDeactivated" ;
VAL_ 2566718974 EngineCoolantLevelLowLampData 3 "NotAvailable" 2 "Error" 1 "LampActivated" 0 "LampDeactivated" ;
VAL_ 2566718974 EngnIdlMngmntAtvLmpDt 3 "NotAvailable" 2 "Error" 1 "LampActivated" 0 "LampDeactivated" ;
VAL_ 2566718974 EngnArFltrRstrtnLmpDt 3 "NotAvailable" 2 "Error" 1 "LampActivated" 0 "LampDeactivated" ;
VAL_ 2566718974 EngnFlFltrRstrtdLmpDt 3 "NotAvailable" 2 "Error" 1 "LampActivated" 0 "LampDeactivated" ;
VAL_ 2566718974 EngineWaitToStartLampData 3 "NotAvailable" 2 "Error" 1 "LampActive" 0 "LampDeactive" ;
VAL_ 2566719230 VhlBttrVltgLwLmpCmmnd 3 "NotAvailable" 2 "Reserved" 1 "LampOn" 0 "LampOff" ;
VAL_ 2566719230 VehicleFuelLevelLowLampCommand 3 "NotAvailable" 2 "Reserved" 1 "LampOn" 0 "LampOff" ;
VAL_ 2566719230 VhlArPrssrLwLmpCmmnd 3 "NotAvailable" 2 "Reserved" 1 "LampOn" 0 "LampOff" ;
VAL_ 2566719230 VhlHVACRrltnLmpCmmnd 3 "NotAvailable" 2 "Reserved" 1 "LampOn" 0 "LampOff" ;
VAL_ 2566719230 VhlBttrChrgngLmpCmmnd 3 "NotAvailable" 2 "Reserved" 1 "LampOn" 0 "LampOff" ;
VAL_ 2566719486 EngineProtectLampCommand 3 "NotAvailable" 2 "Reserved" 1 "LampOn" 0 "LampOff" ;
VAL_ 2566719486 EngineAmberWarningLampCommand 3 "NotAvailable" 2 "Reserved" 1 "LampOn" 0 "LampOff" ;
VAL_ 2566719486 EngineRedStopLampCommand 3 "NotAvailable" 2 "Reserved" 1 "LampOn" 0 "LampOff" ;
VAL_ 2566719486 OBDMlfntnIndtrLmpCmmnd 3 "NotAvailable" 2 "Reserved" 1 "LampOn" 0 "LampOff" ;
VAL_ 2566719486 EngineBrakeActiveLampCommand 3 "NotAvailable" 2 "Reserved" 1 "LampOn" 0 "LampOff" ;
VAL_ 2566719486 CmprssnBrkEnlSwthIndtrLmpCmmnd 3 "NotAvailable" 2 "Reserved" 1 "LampON" 0 "LampOFF" ;
VAL_ 2566719486 EngineOilPressureLowLampCommand 3 "NotAvailable" 2 "Reserved" 1 "LampOn" 0 "LampOff" ;
VAL_ 2566719486 EngnClntTmprtrHghLmpCmmnd 3 "NotAvailable" 2 "Reserved" 1 "LampOn" 0 "LampOff" ;
VAL_ 2566719486 EngnClntLvlLwLmpCmmnd 3 "NotAvailable" 2 "Reserved" 1 "LampOn" 0 "LampOff" ;
VAL_ 2566719486 EngnIdlMngmntAtvLmpCmmnd 3 "NotAvailable" 2 "Reserved" 1 "LampOn" 0 "LampOff" ;
VAL_ 2566719486 EngnArFltrRstrtnLmpCmmnd 3 "NotAvailable" 2 "Reserved" 1 "LampOn" 0 "LampOff" ;
VAL_ 2566719486 EngnFlFltrRstrtdLmpCmmnd 3 "NotAvailable" 2 "Flash" 1 "LampOn" 0 "LampOff" ;
